VERSION ""

NS_ :

BS_:

BU_: WRCS SRS LECM3 LECM1 ECUspare6 CMS CIOM CCM AlcoLock2

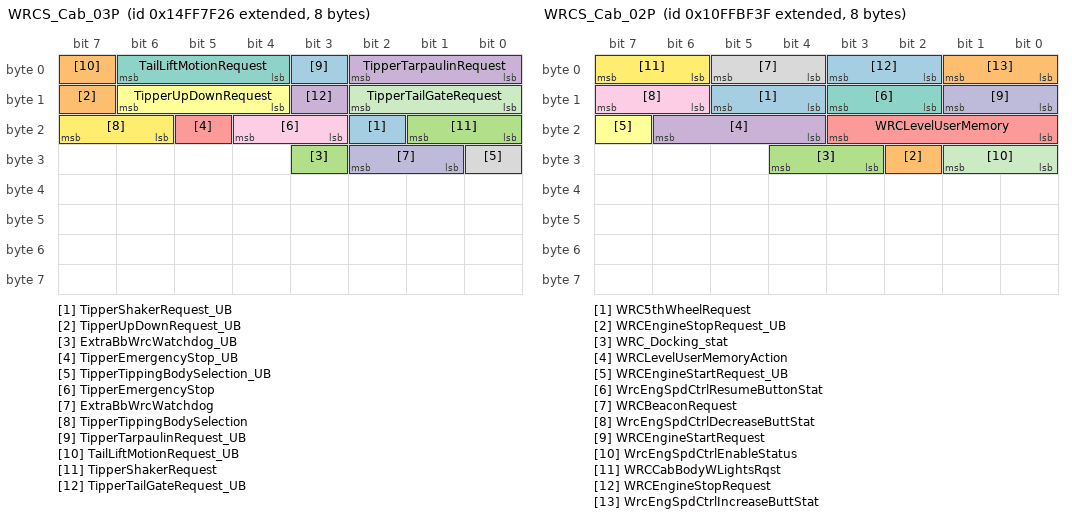
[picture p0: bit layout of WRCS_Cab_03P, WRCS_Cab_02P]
BO_ 2499772198 WRCS_Cab_03P: 8 WRCS
 SG_ TipperShakerRequest_UB : 18|1@1+ (1,0) [0|0] ""  CIOM
 SG_ TipperUpDownRequest_UB : 15|1@1+ (1,0) [0|0] ""  CIOM
 SG_ ExtraBbWrcWatchdog_UB : 27|1@1+ (1,0) [0|0] ""  CIOM
 SG_ TipperTarpaulinRequest : 0|3@1+ (1,0) [0|0] ""  CIOM
 SG_ TipperEmergencyStop_UB : 21|1@1+ (1,0) [0|0] ""  CIOM
 SG_ TipperUpDownRequest : 12|3@1+ (1,0) [0|0] ""  CIOM
 SG_ TailLiftMotionRequest : 4|3@1+ (1,0) [0|0] ""  CIOM
 SG_ TipperTippingBodySelection_UB : 24|1@1+ (1,0) [0|0] ""  CIOM
 SG_ TipperEmergencyStop : 19|2@1+ (1,0) [0|0] ""  CIOM
 SG_ ExtraBbWrcWatchdog : 25|2@1+ (1,0) [0|0] ""  CIOM
 SG_ TipperTailGateRequest : 8|3@1+ (1,0) [0|0] ""  CIOM
 SG_ TipperTippingBodySelection : 22|2@1+ (1,0) [0|0] ""  CIOM
 SG_ TipperTarpaulinRequest_UB : 3|1@1+ (1,0) [0|0] ""  CIOM
 SG_ TailLiftMotionRequest_UB : 7|1@1+ (1,0) [0|0] ""  CIOM
 SG_ TipperShakerRequest : 16|2@1+ (1,0) [0|0] ""  CIOM
 SG_ TipperTailGateRequest_UB : 11|1@1+ (1,0) [0|0] ""  CIOM

BO_ 2432679743 WRCS_Cab_02P: 8 WRCS
 SG_ WRC5thWheelRequest : 12|2@1+ (1,0) [0|0] ""  CIOM
 SG_ WRCEngineStopRequest_UB : 26|1@1+ (1,0) [0|0] ""  CIOM
 SG_ WRC_Docking_stat : 27|2@1+ (1,0) [0|0] ""  CIOM
 SG_ WRCLevelUserMemoryAction : 20|3@1+ (1,0) [0|0] ""  CIOM
 SG_ WRCLevelUserMemory : 16|4@1+ (1,0) [0|0] ""  CIOM
 SG_ WRCEngineStartRequest_UB : 23|1@1+ (1,0) [0|0] ""  CIOM
 SG_ WrcEngSpdCtrlResumeButtonStat : 10|2@1+ (1,0) [0|0] ""  CIOM
 SG_ WRCBeaconRequest : 4|2@1+ (1,0) [0|0] ""  CIOM
 SG_ WrcEngSpdCtrlDecreaseButtStat : 14|2@1+ (1,0) [0|0] ""  CIOM
 SG_ WRCEngineStartRequest : 8|2@1+ (1,0) [0|0] ""  CIOM
 SG_ WrcEngSpdCtrlEnableStatus : 24|2@1+ (1,0) [0|0] ""  CIOM
 SG_ WRCCabBodyWLightsRqst : 6|2@1+ (1,0) [0|0] ""  CIOM
 SG_ WRCEngineStopRequest : 2|2@1+ (1,0) [0|0] ""  CIOM
 SG_ WrcEngSpdCtrlIncreaseButtStat : 0|2@1+ (1,0) [0|0] ""  CIOM

BO_ 2365554559 WRCS_Cab_01P: 8 WRCS
 SG_ WrcPto1ButtonStatus : 2|2@1+ (1,0) [0|0] ""  CIOM
 SG_ ECSStandByReqWRC : 35|3@1+ (1,0) [0|0] ""  CIOM
 SG_ WRCCraneRequest : 22|2@1+ (1,0) [0|0] ""  CIOM
 SG_ WRCUnlockButtonStatus : 4|2@1+ (1,0) [0|0] ""  CIOM
 SG_ WRCRollRequest : 32|3@1+ (1,0) [0|0] ""  CIOM
 SG_ WRCAux3Request : 14|2@1+ (1,0) [0|0] ""  CIOM
 SG_ WRCAux2Request : 0|2@1+ (1,0) [0|0] ""  CIOM
 SG_ WrcPto3ButtonStatus : 20|2@1+ (1,0) [0|0] ""  CIOM
 SG_ WRCLevelAdjustmentAction : 44|4@1+ (1,0) [0|0] ""  CIOM
 SG_ WRCAux4Request : 10|2@1+ (1,0) [0|0] ""  CIOM
 SG_ WRCAux5Request : 8|2@1+ (1,0) [0|0] ""  CIOM
 SG_ WRCAux6Request : 16|2@1+ (1,0) [0|0] ""  CIOM
 SG_ WRCSideReverseWorkingRequest : 6|2@1+ (1,0) [0|0] ""  CIOM
 SG_ WrcPto2ButtonStatus : 12|2@1+ (1,0) [0|0] ""  CIOM
 SG_ WRCTailLiftRequest : 24|2@1+ (1,0) [0|0] ""  CIOM
 SG_ WrcPto4ButtonStatus : 30|2@1+ (1,0) [0|0] ""  CIOM
 SG_ WRCLevelAdjustmentStroke : 41|3@1+ (1,0) [0|0] ""  CIOM
 SG_ WRCLevelAdjustmentAxles : 38|3@1+ (1,0) [0|0] ""  CIOM
 SG_ WRCAirSuspensionStopRequest : 28|2@1+ (1,0) [0|0] ""  CIOM
 SG_ WRCAux1Request : 26|2@1+ (1,0) [0|0] ""  CIOM
 SG_ WRCLockButtonStatus : 18|2@1+ (1,0) [0|0] ""  CIOM

BO_ 2671902706 TesterFuncDiagMsg_Cab: 8 CIOM
 SG_ FuncDiagDataTester : 0|64@1+ (1,0) [0|0] ""  SRS,CCM,LECM1,WRCS,LECM3,CMS

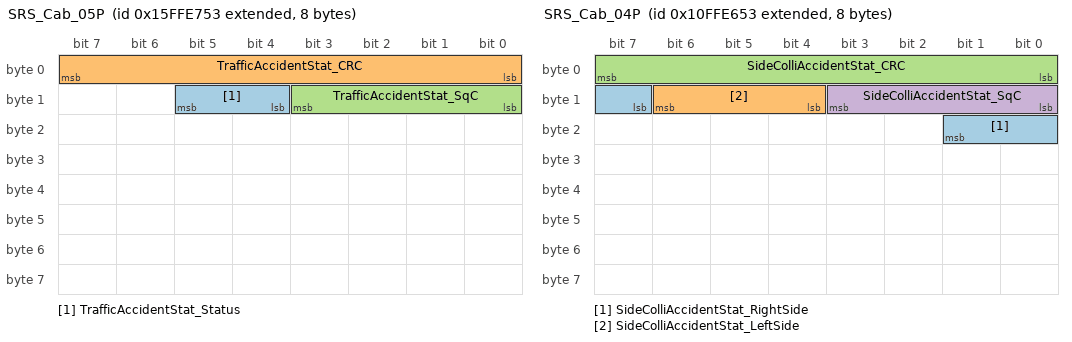
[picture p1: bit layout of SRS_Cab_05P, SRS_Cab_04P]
BO_ 2516576083 SRS_Cab_05P: 8 SRS
 SG_ TrafficAccidentStat_Status : 12|2@1+ (1,0) [0|0] ""  CIOM
 SG_ TrafficAccidentStat_CRC : 0|8@1+ (1,0) [0|255] ""  CIOM
 SG_ TrafficAccidentStat_SqC : 8|4@1+ (1,0) [0|14] "NotApplicable"  CIOM

BO_ 2432689747 SRS_Cab_04P: 8 SRS
 SG_ SideColliAccidentStat_RightSide : 15|3@1+ (1,0) [0|0] ""  CIOM
 SG_ SideColliAccidentStat_LeftSide : 12|3@1+ (1,0) [0|0] ""  CIOM
 SG_ SideColliAccidentStat_CRC : 0|8@1+ (1,0) [0|255] ""  CIOM
 SG_ SideColliAccidentStat_SqC : 8|4@1+ (1,0) [0|14] "NotApplicable"  CIOM

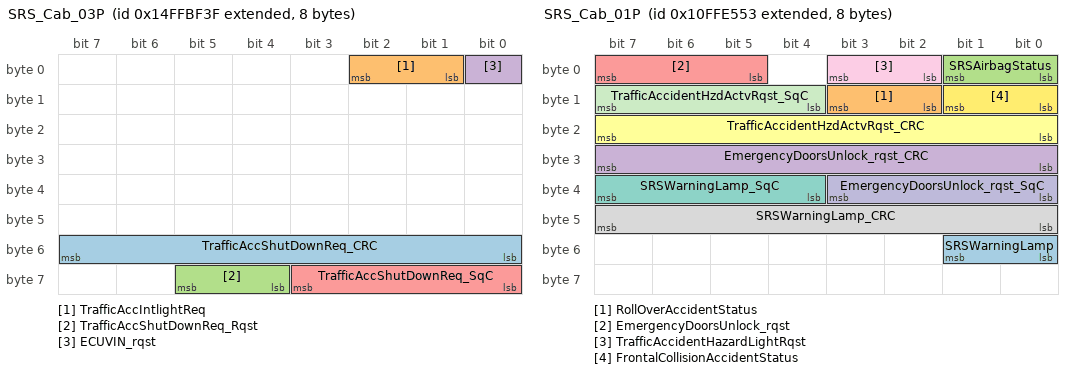
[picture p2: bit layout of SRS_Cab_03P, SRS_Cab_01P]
BO_ 2499788607 SRS_Cab_03P: 8 SRS
 SG_ TrafficAccShutDownReq_CRC : 48|8@1+ (1,0) [0|255] ""  CIOM
 SG_ TrafficAccIntlightReq : 1|2@1+ (1,0) [0|0] ""  CIOM
 SG_ TrafficAccShutDownReq_Rqst : 60|2@1+ (1,0) [0|0] ""  CIOM
 SG_ ECUVIN_rqst : 0|1@1+ (1,0) [0|0] ""  CIOM
 SG_ TrafficAccShutDownReq_SqC : 56|4@1+ (1,0) [0|0] ""  CIOM

BO_ 2432689491 SRS_Cab_01P: 8 SRS
 SG_ SRSWarningLamp : 48|2@1+ (1,0) [0|0] ""  CIOM
 SG_ RollOverAccidentStatus : 10|2@1+ (1,0) [0|0] ""  CCM,CIOM
 SG_ SRSAirbagStatus : 0|2@1+ (1,0) [0|0] ""  CIOM
 SG_ EmergencyDoorsUnlock_rqst_CRC : 24|8@1+ (1,0) [0|255] ""  CIOM
 SG_ EmergencyDoorsUnlock_rqst : 5|3@1+ (1,0) [0|0] ""  CIOM
 SG_ TrafficAccidentHzdActvRqst_CRC : 16|8@1+ (1,0) [0|255] ""  CIOM
 SG_ SRSWarningLamp_SqC : 36|4@1+ (1,0) [0|15] "Count"  CIOM
 SG_ SRSWarningLamp_CRC : 40|8@1+ (1,0) [0|255] ""  CIOM
 SG_ TrafficAccidentHazardLightRqst : 2|2@1+ (1,0) [0|0] ""  CIOM
 SG_ EmergencyDoorsUnlock_rqst_SqC : 32|4@1+ (1,0) [0|15] "Count"  CIOM
 SG_ TrafficAccidentHzdActvRqst_SqC : 12|4@1+ (1,0) [0|15] "Count"  CIOM
 SG_ FrontalCollisionAccidentStatus : 8|2@1+ (1,0) [0|0] ""  CIOM,CCM

BO_ 2658975757 SRSDiagPSTesterTx4_Cab: 8 SRS
 SG_ SRSDiagPSTesterTx4 : 0|64@1+ (1,0) [0|0] "" Vector__XXX

BO_ 2658975756 SRSDiagPSTesterTx3_Cab: 8 SRS
 SG_ SRSDiagPSTesterTx3 : 0|64@1+ (1,0) [0|0] "" Vector__XXX

BO_ 2658975755 SRSDiagPSTesterTx2_Cab: 8 SRS
 SG_ SRSDiagPSTesterTx2 : 0|64@1+ (1,0) [0|0] "" Vector__XXX

BO_ 2658967560 SRSDiagPSTesterTx1_Cab: 8 SRS
 SG_ SRSDiagPSTesterTx1 : 0|64@1+ (1,0) [0|0] "" Vector__XXX

BO_ 2658967559 SRSDiagPSTesterRx1_Cab: 8 Vector__XXX
 SG_ SRSDiagPSTesterRx1 : 0|64@1+ (1,0) [0|0] ""  SRS

BO_ 2671833762 PhysDiagRespMsg_F2_A2_Cab: 8 LECM3
 SG_ PhysDiagRespSig_F2_A2 : 0|64@1+ (1,0) [0|0] ""  CIOM

BO_ 2671833752 PhysDiagRespMsg_F2_98_Cab: 8 CCM
 SG_ PhysDiagRespSig_F2_98 : 0|64@1+ (1,0) [0|0] ""  CIOM

BO_ 2671833747 PhysDiagRespMsg_F2_93_Cab: 8 CMS
 SG_ PhysDiagRespSig_F2_93 : 0|64@1+ (1,0) [0|0] ""  CIOM

BO_ 2671833683 PhysDiagRespMsg_F2_53_Cab: 8 SRS
 SG_ PhysDiagRespSig_F2_53 : 0|64@1+ (1,0) [0|0] ""  CIOM

BO_ 2671833638 PhysDiagRespMsg_F2_26_Cab: 8 WRCS
 SG_ PhysDiagRespSig_F2_26 : 0|64@1+ (1,0) [0|0] ""  CIOM

BO_ 2564485459 PhysDiagRespMsg_F1_53_Cab: 8 SRS
 SG_ PhysDiagRespSig_F1_53 : 0|64@1+ (1,0) [0|0] ""  CIOM

BO_ 2671813362 PhysDiagReqMsg_A2_F2_Cab: 8 CIOM
 SG_ PhysDiagReqSig_A2_F2 : 0|64@1+ (1,0) [0|0] ""  LECM3,LECM1

BO_ 2671810802 PhysDiagReqMsg_98_F2_Cab: 8 CIOM
 SG_ PhysDiagReqSig_98_F2 : 0|64@1+ (1,0) [0|0] ""  CCM

BO_ 2671809522 PhysDiagReqMsg_93_F2_Cab: 8 CIOM
 SG_ PhysDiagReqSig_93_F2 : 0|64@1+ (1,0) [0|0] ""  CMS

BO_ 2671793138 PhysDiagReqMsg_53_F2_Cab: 8 CIOM
 SG_ PhysDiagReqSig_53_F2 : 0|64@1+ (1,0) [0|0] ""  SRS

BO_ 2564445169 PhysDiagReqMsg_53_F1_Cab: 8 CIOM
 SG_ PhysDiagReqSig_53_F1 : 0|64@1+ (1,0) [0|0] ""  SRS

BO_ 2671781618 PhysDiagReqMsg_26_F2_Cab: 8 CIOM
 SG_ PhysDiagReqSig_26_F2 : 0|64@1+ (1,0) [0|0] ""  WRCS

BO_ 2633990182 NmAsr_WRCS_Cab: 1 WRCS

BO_ 2633990227 NmAsr_SRS_Cab: 1 SRS

BO_ 2633990306 NmAsr_LECM1_Cab: 1 LECM3

BO_ 2633990291 NmAsr_CMS_Cab: 1 CMS

BO_ 2633990208 NmAsr_CIOM_Cab: 1 CIOM

BO_ 2633990296 NmAsr_CCM_Cab: 1 CCM

BO_ 2549208482 LECM3_Cab_02P: 8 LECM3
 SG_ LECM_Ent_UpDown_WheelStatus : 20|4@1+ (1,0) [0|0] ""  CIOM
 SG_ LECM_IntLight_SlprMaxLight_BS : 48|2@1+ (1,0) [0|0] ""  CIOM
 SG_ LECM_CabClim_Pwr_BtnStat : 14|2@1+ (1,0) [0|0] ""  CIOM
 SG_ LECM_LockControl_Lock_BtnStat : 52|2@1+ (1,0) [0|0] ""  CIOM
 SG_ LECM_CabClim_Auto_BtnStat : 10|2@1+ (1,0) [0|0] ""  CIOM
 SG_ LECM_CabClim_AC_BtnStat : 18|2@1+ (1,0) [0|0] ""  CIOM
 SG_ LECM_CabClim_FrPwr_BtnStat : 8|2@1+ (1,0) [0|0] ""  CIOM
 SG_ LECM_Ent_Volume_WheelStatus : 28|4@1+ (1,0) [0|0] ""  CIOM
 SG_ LECMCabClimSetTempSelectGuiReq : 62|2@1+ (1,0) [0|0] ""  CIOM
 SG_ LECM_IntLight_SlprAmbLow_BS : 46|2@1+ (1,0) [0|0] ""  CIOM
 SG_ LECM_CabClim_MaxDef_GuiReq : 54|2@1+ (1,0) [0|0] ""  CIOM
 SG_ LECM_CabClim_Fan_WheelStatus : 32|4@1+ (1,0) [0|0] ""  CIOM
 SG_ LECM_IntLight_SlprAmbUpp_BS : 44|2@1+ (1,0) [0|0] ""  CIOM
 SG_ LECM_Ent_AudioSettingsViewSts : 56|4@1+ (1,0) [0|0] ""  CIOM
 SG_ LECM_Panic_CMS_BtnStat : 50|2@1+ (1,0) [0|0] ""  CIOM
 SG_ LECM_CabClim_Sync_GuiReq : 16|2@1+ (1,0) [0|0] ""  CIOM
 SG_ LecmCutOffAnswerGuiRqst : 60|2@1+ (1,0) [0|0] ""  CIOM
 SG_ LECM_Ent_MediaSource_BtnStat : 12|2@1+ (1,0) [0|0] ""  CIOM
 SG_ LECM_CabClim_Temp_WheelStatus : 24|4@1+ (1,0) [0|0] ""  CIOM
 SG_ LECM_Power_Inverter_BtnStat : 0|2@1+ (1,0) [0|0] ""  CIOM
 SG_ LECM_Ent_SkpLeft_BtnStat : 2|2@1+ (1,0) [0|0] ""  CIOM
 SG_ LECM_IntLight_SlprDecrease_BS : 40|2@1+ (1,0) [0|0] ""  CIOM
 SG_ LECM_Ent_OnOff_BtnStat : 6|2@1+ (1,0) [0|0] ""  CIOM
 SG_ LECM_IntLight_SlprIncrease_BS : 42|2@1+ (1,0) [0|0] ""  CIOM
 SG_ LECM_Ent_SkpRight_BtnStat : 4|2@1+ (1,0) [0|0] ""  CIOM

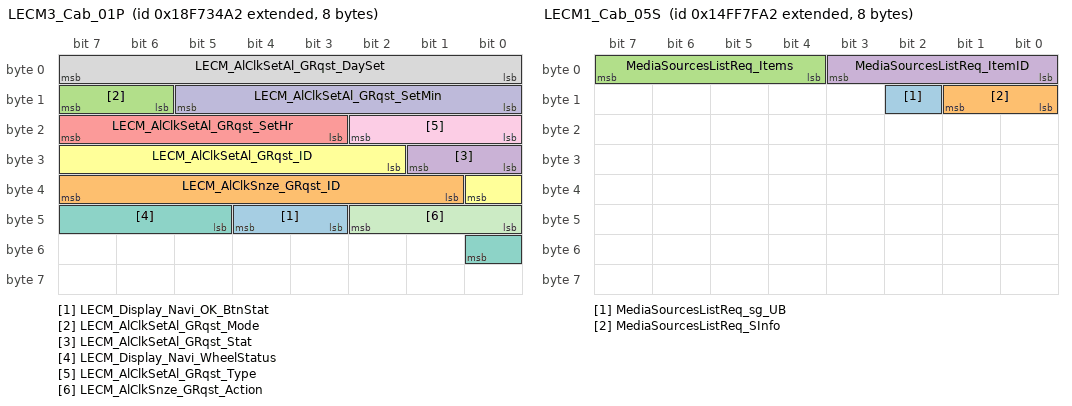
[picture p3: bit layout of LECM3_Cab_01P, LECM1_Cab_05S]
BO_ 2566337698 LECM3_Cab_01P: 8 LECM3
 SG_ LECM_Display_Navi_OK_BtnStat : 43|2@1+ (1,0) [0|0] ""  CIOM
 SG_ LECM_AlClkSnze_GRqst_ID : 33|7@1+ (1,0) [0|0] ""  CIOM
 SG_ LECM_AlClkSetAl_GRqst_Mode : 14|2@1+ (1,0) [0|0] ""  CIOM
 SG_ LECM_AlClkSetAl_GRqst_Stat : 24|2@1+ (1,0) [0|0] ""  CIOM
 SG_ LECM_AlClkSetAl_GRqst_SetHr : 19|5@1+ (1,0) [0|31] "h"  CIOM
 SG_ LECM_AlClkSetAl_GRqst_ID : 26|7@1+ (1,0) [0|0] ""  CIOM
 SG_ LECM_Display_Navi_WheelStatus : 45|4@1+ (1,0) [0|0] ""  CIOM
 SG_ LECM_AlClkSetAl_GRqst_DaySet : 0|8@1+ (1,0) [0|255] ""  CIOM
 SG_ LECM_AlClkSetAl_GRqst_Type : 16|3@1+ (1,0) [0|0] ""  CIOM
 SG_ LECM_AlClkSetAl_GRqst_SetMin : 8|6@1+ (1,0) [0|63] "min"  CIOM
 SG_ LECM_AlClkSnze_GRqst_Action : 40|3@1+ (1,0) [0|0] ""  CIOM

BO_ 2499772322 LECM1_Cab_05S: 8 LECM1
 SG_ MediaSourcesListReq_sg_UB : 10|1@1+ (1,0) [0|0] ""  CIOM
 SG_ MediaSourcesListReq_SInfo : 8|2@1+ (1,0) [0|0] ""  CIOM
 SG_ MediaSourcesListReq_Items : 4|4@1+ (1,0) [0|0] ""  CIOM
 SG_ MediaSourcesListReq_ItemID : 0|4@1+ (1,0) [0|0] ""  CIOM

BO_ 2489730210 LECM1_Cab_04P: 8 LECM1
 SG_ BunkH1AudioSrcSem_rqst : 0|4@1+ (1,0) [0|0] ""  CIOM
 SG_ CMSOnOffRqst : 4|2@1+ (1,0) [0|0] ""  CIOM

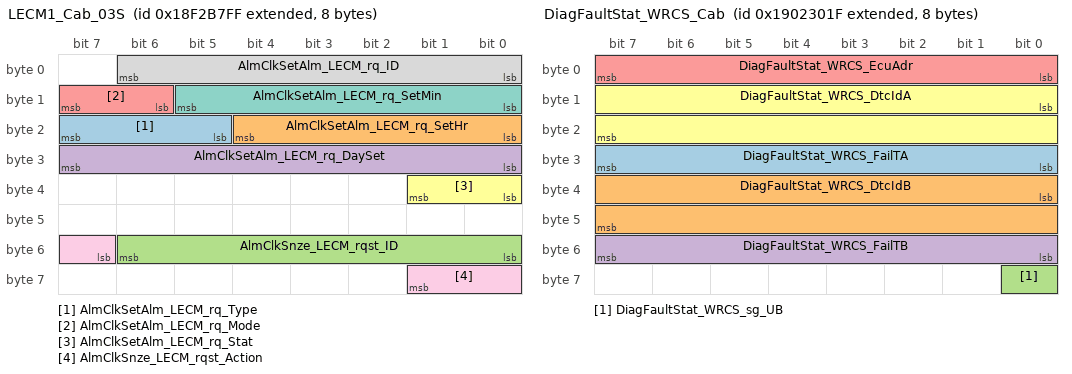
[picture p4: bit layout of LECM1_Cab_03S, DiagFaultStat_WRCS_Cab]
BO_ 2566043647 LECM1_Cab_03S: 8 LECM1
 SG_ AlmClkSetAlm_LECM_rq_Type : 21|3@1+ (1,0) [0|0] ""  CIOM
 SG_ AlmClkSetAlm_LECM_rq_SetHr : 16|5@1+ (1,0) [0|31] "h"  CIOM
 SG_ AlmClkSnze_LECM_rqst_ID : 48|7@1+ (1,0) [0|0] ""  CIOM
 SG_ AlmClkSetAlm_LECM_rq_DaySet : 24|8@1+ (1,0) [0|255] ""  CIOM
 SG_ AlmClkSetAlm_LECM_rq_Mode : 14|2@1+ (1,0) [0|0] ""  CIOM
 SG_ AlmClkSetAlm_LECM_rq_Stat : 32|2@1+ (1,0) [0|0] ""  CIOM
 SG_ AlmClkSetAlm_LECM_rq_SetMin : 8|6@1+ (1,0) [0|63] "min"  CIOM
 SG_ AlmClkSetAlm_LECM_rq_ID : 0|7@1+ (1,0) [0|0] ""  CIOM
 SG_ AlmClkSnze_LECM_rqst_Action : 55|3@1+ (1,0) [0|0] ""  CIOM

BO_ 2432693154 LECM1_Cab_02P: 8 LECM1
 SG_ BunkH1Prev_ButtonStatus : 0|2@1+ (1,0) [0|0] ""  CIOM
 SG_ BunkH1PowerWinOpenDSBtn_stat_UB : 58|1@1+ (1,0) [0|0] ""  CIOM
 SG_ BunkH1RoofhatchOpenBtn_Stat : 32|2@1+ (1,0) [0|0] ""  CIOM
 SG_ BunkH1IntLghtActvnBtn_stat : 6|2@1+ (1,0) [0|0] ""  CIOM
 SG_ BunkH1AudioSource_rqst : 48|3@1+ (1,0) [0|0] ""  CIOM
 SG_ BunkH1TempDec_ButtonStatus : 24|2@1+ (1,0) [0|0] ""  CCM
 SG_ BunkH1IntLghtDirAccsUpBtn_stat : 46|2@1+ (1,0) [0|0] ""  CIOM
 SG_ BunkH1RoofhatchCloseBtn_Stat : 28|2@1+ (1,0) [0|0] ""  CIOM
 SG_ BunkH1PowerWinClosePSBtn_stat_UB : 55|1@1+ (1,0) [0|0] ""  CIOM
 SG_ BunkH1VolumeDown_ButtonStatus : 18|2@1+ (1,0) [0|0] ""  CIOM
 SG_ BunkH1PowerWinCloseDSBtn_stat : 16|2@1+ (1,0) [0|0] ""  CIOM
 SG_ BunkH1Next_ButtonStatus : 20|2@1+ (1,0) [0|0] ""  CIOM
 SG_ BunkH1UnlockButtonStatus : 4|2@1+ (1,0) [0|0] ""  CIOM
 SG_ BunkH1ParkHeaterTimer2_cmd : 40|3@1+ (1,0) [0|0] ""  CCM
 SG_ BunkH1AudioOnOff_ButtonStatus : 2|2@1+ (1,0) [0|0] ""  CIOM
 SG_ BunkH1PowerWinOpenPSBtn_stat_UB : 59|1@1+ (1,0) [0|0] ""  CIOM
 SG_ BunkH1PowerWinOpenDSBtn_stat : 8|2@1+ (1,0) [0|0] ""  CIOM
 SG_ BunkH1ParkHeater_ButtonStatus : 14|2@1+ (1,0) [0|0] ""  CCM
 SG_ BunkH1VolumeUp_ButtonStatus : 30|2@1+ (1,0) [0|0] ""  CIOM
 SG_ BunkH1ParkHeaterTimer3_cmd : 36|3@1+ (1,0) [0|0] ""  CCM
 SG_ BunkH1Mute_ButtonStatus : 56|2@1+ (1,0) [0|0] ""  CIOM
 SG_ BunkH1IntLghtDirAccsDnBtn_stat : 22|2@1+ (1,0) [0|0] ""  CIOM
 SG_ BunkH1LockButtonStatus : 10|2@1+ (1,0) [0|0] ""  CIOM
 SG_ BunkH1ParkHeaterTimer1_cmd : 43|3@1+ (1,0) [0|0] ""  CCM
 SG_ BnkH1IntLghtMMenu_stat_IL_Mode : 51|3@1+ (1,0) [0|0] ""  CIOM
 SG_ BunkH1AudioSource_rqst2 : 60|4@1+ (1,0) [0|0] ""  CIOM
 SG_ BunkH1PowerWinCloseDSBtn_stat_UB : 39|1@1+ (1,0) [0|0] ""  CIOM
 SG_ BnkH1IntLghtMMenu_stat_EventFlag : 54|1@1+ (1,0) [0|0] ""  CIOM
 SG_ BunkH1PowerWinOpenPSBtn_stat : 26|2@1+ (1,0) [0|0] ""  CIOM
 SG_ BunkH1PowerWinClosePSBtn_stat : 34|2@1+ (1,0) [0|0] ""  CIOM
 SG_ BunkH1TempInc_ButtonStatus : 12|2@1+ (1,0) [0|0] ""  CCM

BO_ 2671902708 IntTesterTGW2FuncDiagMsg_Cab: 8 CIOM
 SG_ FuncDiagDataIntTesterTGW2 : 0|64@1+ (1,0) [0|0] ""  LECM3,LECM1,SRS,CCM,CMS,WRCS

BO_ 2671964834 DiagUUDTRespMsg1_F2_A2_Cab: 8 LECM1
 SG_ DiagUUDTRespSig_F2_A2 : 0|64@1+ (1,0) [0|0] ""  CIOM

BO_ 2671964824 DiagUUDTRespMsg1_F2_98_Cab: 8 CCM
 SG_ DiagUUDTRespSig_F2_98 : 0|64@1+ (1,0) [0|0] ""  CIOM

BO_ 2671964819 DiagUUDTRespMsg1_F2_93_Cab: 8 CMS
 SG_ DiagUUDTRespSig_F2_93 : 0|64@1+ (1,0) [0|0] ""  CIOM

BO_ 2671964755 DiagUUDTRespMsg1_F2_53_Cab: 8 SRS
 SG_ DiagUUDTRespSig_F2_53 : 0|64@1+ (1,0) [0|0] ""  CIOM

BO_ 2671964710 DiagUUDTRespMsg1_F2_26_Cab: 8 WRCS
 SG_ DiagUUDTRespSig_F2_26 : 0|64@1+ (1,0) [0|0] ""  CIOM

BO_ 2671834259 DiagRespMsgIntTGW_F4_93_Cab: 8 CMS
 SG_ InternalTesterDiagSig_F4_93 : 0|64@1+ (1,0) [0|0] ""  CIOM

BO_ 2671834274 DiagRespMsgIntTGW2_F4_A2_Cab: 8 LECM3
 SG_ InternalTesterDiagSig_F4_A2 : 0|64@1+ (1,0) [0|0] ""  CIOM

BO_ 2671834264 DiagRespMsgIntTGW2_F4_98_Cab: 8 CCM
 SG_ InternalTesterDiagSig_F4_98 : 0|64@1+ (1,0) [0|0] ""  CIOM

BO_ 2671834195 DiagRespMsgIntTGW2_F4_53_Cab: 8 SRS
 SG_ InternalTesterDiagSig_F4_53 : 0|64@1+ (1,0) [0|0] ""  CIOM

BO_ 2671834150 DiagRespMsgIntTGW2_F4_26_Cab: 8 WRCS
 SG_ InternalTesterDiagSig_F4_26 : 0|64@1+ (1,0) [0|0] ""  CIOM

BO_ 2671834003 DiagRespMsgIntIC_F3_93_Cab: 8 CMS
 SG_ InternalTesterDiagSig_F3_93 : 0|64@1+ (1,0) [0|0] ""  CIOM

BO_ 2671834018 DiagRespMsgIntHMIIOM_F3_A2_Cab: 8 LECM3
 SG_ InternalTesterDiagSig_F3_A2 : 0|64@1+ (1,0) [0|0] ""  CIOM

BO_ 2671834008 DiagRespMsgIntHMIIOM_F3_98_Cab: 8 CCM
 SG_ InternalTesterDiagSig_F3_98 : 0|64@1+ (1,0) [0|0] ""  CIOM

BO_ 2671833939 DiagRespMsgIntHMIIOM_F3_53_Cab: 8 SRS
 SG_ InternalTesterDiagSig_F3_53 : 0|64@1+ (1,0) [0|0] ""  CIOM

BO_ 2671833894 DiagRespMsgIntHMIIOM_F3_26_Cab: 8 WRCS
 SG_ InternalTesterDiagSig_F3_26 : 0|64@1+ (1,0) [0|0] ""  CIOM

BO_ 2671809524 DiagReqMsgIntTGW_93_F4_Cab: 8 CIOM
 SG_ InternalTesterDiagSig_93_F4 : 0|64@1+ (1,0) [0|0] ""  CMS

BO_ 2671813364 DiagReqMsgIntTGW2_A2_F4_Cab: 8 CIOM
 SG_ InternalTesterDiagSig_A2_F4 : 0|64@1+ (1,0) [0|0] ""  LECM1,LECM3

BO_ 2671810804 DiagReqMsgIntTGW2_98_F4_Cab: 8 CIOM
 SG_ InternalTesterDiagSig_98_F4 : 0|64@1+ (1,0) [0|0] ""  CCM

BO_ 2671793140 DiagReqMsgIntTGW2_53_F4_Cab: 8 CIOM
 SG_ InternalTesterDiagSig_53_F4 : 0|64@1+ (1,0) [0|0] ""  SRS

BO_ 2671781620 DiagReqMsgIntTGW2_26_F4_Cab: 8 CIOM
 SG_ InternalTesterDiagSig_26_F4 : 0|64@1+ (1,0) [0|0] ""  WRCS

BO_ 2671809523 DiagReqMsgIntIC_93_F3_Cab: 8 CIOM
 SG_ InternalTesterDiagSig_93_F3 : 0|64@1+ (1,0) [0|0] ""  CMS

BO_ 2671813363 DiagReqMsgIntHMIIOM_A2_F3_Cab: 8 CIOM
 SG_ InternalTesterDiagSig_A2_F3 : 0|64@1+ (1,0) [0|0] ""  LECM1,LECM3

BO_ 2671810803 DiagReqMsgIntHMIIOM_98_F3_Cab: 8 CIOM
 SG_ InternalTesterDiagSig_98_F3 : 0|64@1+ (1,0) [0|0] ""  CCM

BO_ 2671793139 DiagReqMsgIntHMIIOM_53_F3_Cab: 8 CIOM
 SG_ InternalTesterDiagSig_53_F3 : 0|64@1+ (1,0) [0|0] ""  SRS

BO_ 2671781619 DiagReqMsgIntHMIIOM_26_F3_Cab: 8 CIOM
 SG_ InternalTesterDiagSig_26_F3 : 0|64@1+ (1,0) [0|0] ""  WRCS

BO_ 2567057439 DiagFaultStat_WRCS_Cab: 8 WRCS
 SG_ DiagFaultStat_WRCS_FailTA : 24|8@1+ (1,0) [0|255] ""  CIOM
 SG_ DiagFaultStat_WRCS_DtcIdB : 32|16@1+ (1,0) [0|65535] ""  CIOM
 SG_ DiagFaultStat_WRCS_sg_UB : 56|1@1+ (1,0) [0|0] ""  CIOM
 SG_ DiagFaultStat_WRCS_FailTB : 48|8@1+ (1,0) [0|255] ""  CIOM
 SG_ DiagFaultStat_WRCS_EcuAdr : 0|8@1+ (1,0) [0|255] ""  CIOM
 SG_ DiagFaultStat_WRCS_DtcIdA : 8|16@1+ (1,0) [0|65535] ""  CIOM

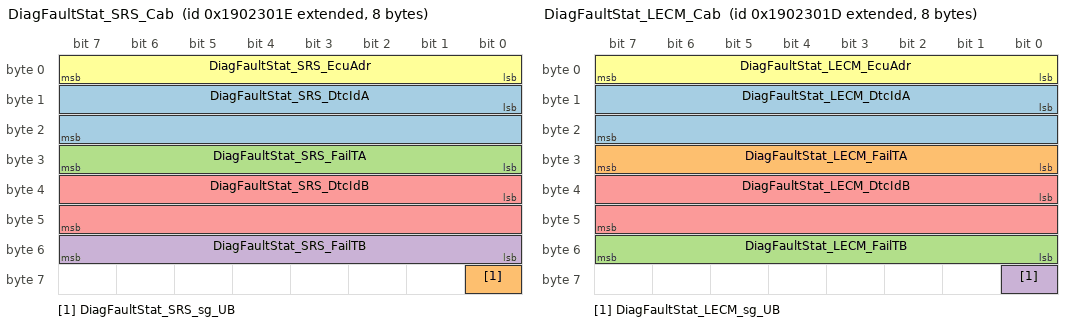
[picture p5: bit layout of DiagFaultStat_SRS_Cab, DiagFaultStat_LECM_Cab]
BO_ 2567057438 DiagFaultStat_SRS_Cab: 8 SRS
 SG_ DiagFaultStat_SRS_DtcIdA : 8|16@1+ (1,0) [0|65535] ""  CIOM
 SG_ DiagFaultStat_SRS_sg_UB : 56|1@1+ (1,0) [0|0] ""  CIOM
 SG_ DiagFaultStat_SRS_FailTA : 24|8@1+ (1,0) [0|255] ""  CIOM
 SG_ DiagFaultStat_SRS_FailTB : 48|8@1+ (1,0) [0|255] ""  CIOM
 SG_ DiagFaultStat_SRS_DtcIdB : 32|16@1+ (1,0) [0|65535] ""  CIOM
 SG_ DiagFaultStat_SRS_EcuAdr : 0|8@1+ (1,0) [0|255] ""  CIOM

BO_ 2567057437 DiagFaultStat_LECM_Cab: 8 LECM1
 SG_ DiagFaultStat_LECM_DtcIdA : 8|16@1+ (1,0) [0|65535] ""  CIOM
 SG_ DiagFaultStat_LECM_FailTA : 24|8@1+ (1,0) [0|255] ""  CIOM
 SG_ DiagFaultStat_LECM_FailTB : 48|8@1+ (1,0) [0|255] ""  CIOM
 SG_ DiagFaultStat_LECM_sg_UB : 56|1@1+ (1,0) [0|0] ""  CIOM
 SG_ DiagFaultStat_LECM_DtcIdB : 32|16@1+ (1,0) [0|65535] ""  CIOM
 SG_ DiagFaultStat_LECM_EcuAdr : 0|8@1+ (1,0) [0|255] ""  CIOM

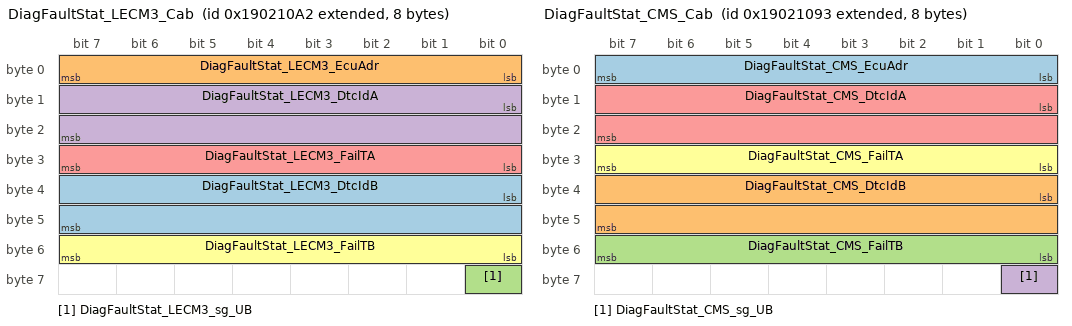
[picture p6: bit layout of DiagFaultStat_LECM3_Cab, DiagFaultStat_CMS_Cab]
BO_ 2567049378 DiagFaultStat_LECM3_Cab: 8 LECM3
 SG_ DiagFaultStat_LECM3_DtcIdB : 32|16@1+ (1,0) [0|65535] ""  CIOM
 SG_ DiagFaultStat_LECM3_EcuAdr : 0|8@1+ (1,0) [0|255] ""  CIOM
 SG_ DiagFaultStat_LECM3_sg_UB : 56|1@1+ (1,0) [0|0] ""  CIOM
 SG_ DiagFaultStat_LECM3_DtcIdA : 8|16@1+ (1,0) [0|65535] ""  CIOM
 SG_ DiagFaultStat_LECM3_FailTA : 24|8@1+ (1,0) [0|255] ""  CIOM
 SG_ DiagFaultStat_LECM3_FailTB : 48|8@1+ (1,0) [0|255] ""  CIOM

BO_ 2567049363 DiagFaultStat_CMS_Cab: 8 CMS
 SG_ DiagFaultStat_CMS_EcuAdr : 0|8@1+ (1,0) [0|255] ""  CIOM
 SG_ DiagFaultStat_CMS_DtcIdB : 32|16@1+ (1,0) [0|65535] ""  CIOM
 SG_ DiagFaultStat_CMS_FailTB : 48|8@1+ (1,0) [0|255] ""  CIOM
 SG_ DiagFaultStat_CMS_sg_UB : 56|1@1+ (1,0) [0|0] ""  CIOM
 SG_ DiagFaultStat_CMS_DtcIdA : 8|16@1+ (1,0) [0|65535] ""  CIOM
 SG_ DiagFaultStat_CMS_FailTA : 24|8@1+ (1,0) [0|255] ""  CIOM

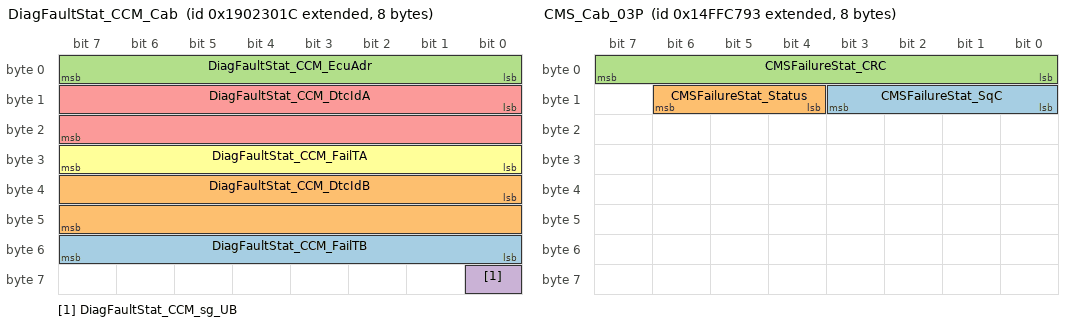
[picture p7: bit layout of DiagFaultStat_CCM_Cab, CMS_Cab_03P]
BO_ 2567057436 DiagFaultStat_CCM_Cab: 8 CCM
 SG_ DiagFaultStat_CCM_FailTB : 48|8@1+ (1,0) [0|255] ""  CIOM
 SG_ DiagFaultStat_CCM_DtcIdB : 32|16@1+ (1,0) [0|65535] ""  CIOM
 SG_ DiagFaultStat_CCM_EcuAdr : 0|8@1+ (1,0) [0|255] ""  CIOM
 SG_ DiagFaultStat_CCM_sg_UB : 56|1@1+ (1,0) [0|0] ""  CIOM
 SG_ DiagFaultStat_CCM_DtcIdA : 8|16@1+ (1,0) [0|65535] ""  CIOM
 SG_ DiagFaultStat_CCM_FailTA : 24|8@1+ (1,0) [0|255] ""  CIOM

BO_ 2634020435 Debug6_SRS_Cab: 8 SRS
 SG_ Debug_6_SRS : 0|64@1+ (1,0) [0|0] "" Vector__XXX

BO_ 2634020514 Debug6_LECM_Cab: 8 LECM1
 SG_ Debug_6_LECM : 0|64@1+ (1,0) [0|0] "" Vector__XXX

BO_ 2634022306 Debug6_LECM3_Cab: 8 LECM3
 SG_ Debug_6_LECM3 : 0|64@1+ (1,0) [0|0] "" Vector__XXX

BO_ 2634020499 Debug6_CMS_Cab: 8 CMS
 SG_ Debug_6_CMS : 0|64@1+ (1,0) [0|0] "" Vector__XXX

BO_ 2634020504 Debug6_CCM_Cab: 8 CCM
 SG_ Debug_6_CCM : 0|64@1+ (1,0) [0|0] "" Vector__XXX

BO_ 2634020179 Debug5_SRS_Cab: 8 SRS
 SG_ Debug_5_SRS : 0|64@1+ (1,0) [0|0] "" Vector__XXX

BO_ 2634020258 Debug5_LECM_Cab: 8 LECM1
 SG_ Debug_5_LECM : 0|64@1+ (1,0) [0|0] "" Vector__XXX

BO_ 2634022050 Debug5_LECM3_Cab: 8 LECM3
 SG_ Debug_5_LECM3 : 0|64@1+ (1,0) [0|0] "" Vector__XXX

BO_ 2634020243 Debug5_CMS_Cab: 8 CMS
 SG_ Debug_5_CMS : 0|64@1+ (1,0) [0|0] "" Vector__XXX

BO_ 2634020248 Debug5_CCM_Cab: 8 CCM
 SG_ Debug_5_CCM : 0|64@1+ (1,0) [0|0] "" Vector__XXX

BO_ 2634019923 Debug4_SRS_Cab: 8 SRS
 SG_ Debug_4_SRS : 0|64@1+ (1,0) [0|0] "" Vector__XXX

BO_ 2634020002 Debug4_LECM_Cab: 8 LECM1
 SG_ Debug_4_LECM : 0|64@1+ (1,0) [0|0] "" Vector__XXX

BO_ 2634021794 Debug4_LECM3_Cab: 8 LECM3
 SG_ Debug_4_LECM3 : 0|64@1+ (1,0) [0|0] "" Vector__XXX

BO_ 2634019987 Debug4_CMS_Cab: 8 CMS
 SG_ Debug_4_CMS : 0|64@1+ (1,0) [0|0] "" Vector__XXX

BO_ 2634019992 Debug4_CCM_Cab: 8 CCM
 SG_ Debug_4_CCM : 0|64@1+ (1,0) [0|0] "" Vector__XXX

BO_ 2634019667 Debug3_SRS_Cab: 8 SRS
 SG_ Debug_3_SRS : 0|64@1+ (1,0) [0|0] "" Vector__XXX

BO_ 2634019746 Debug3_LECM_Cab: 8 LECM1
 SG_ Debug_3_LECM : 0|64@1+ (1,0) [0|0] "" Vector__XXX

BO_ 2634021538 Debug3_LECM3_Cab: 8 LECM3
 SG_ Debug_3_LECM3 : 0|64@1+ (1,0) [0|0] "" Vector__XXX

BO_ 2634019731 Debug3_CMS_Cab: 8 CMS
 SG_ Debug_3_CMS : 0|64@1+ (1,0) [0|0] "" Vector__XXX

BO_ 2634019736 Debug3_CCM_Cab: 8 Vector__XXX
 SG_ Debug_3_CCM : 0|64@1+ (1,0) [0|0] ""  CCM

BO_ 2634019411 Debug2_SRS_Cab: 8 SRS
 SG_ Debug_2_SRS : 0|64@1+ (1,0) [0|0] "" Vector__XXX

BO_ 2634019490 Debug2_LECM_Cab: 8 LECM1
 SG_ Debug_2_LECM : 0|64@1+ (1,0) [0|0] "" Vector__XXX

BO_ 2634021282 Debug2_LECM3_Cab: 8 LECM3
 SG_ Debug_2_LECM3 : 0|64@1+ (1,0) [0|0] "" Vector__XXX

BO_ 2634019475 Debug2_CMS_Cab: 8 CMS
 SG_ Debug_2_CMS : 0|64@1+ (1,0) [0|0] "" Vector__XXX

BO_ 2634019480 Debug2_CCM_Cab: 8 Vector__XXX
 SG_ Debug_2_CCM : 0|64@1+ (1,0) [0|0] ""  CCM

BO_ 2634019155 Debug1_SRS_Cab: 8 Vector__XXX
 SG_ Debug_1_SRS : 0|64@1+ (1,0) [0|0] ""  SRS

BO_ 2634019234 Debug1_LECM_Cab: 8 Vector__XXX
 SG_ Debug_1_LECM : 0|64@1+ (1,0) [0|0] ""  LECM1

BO_ 2634021026 Debug1_LECM3_Cab: 8 Vector__XXX
 SG_ Debug_1_LECM3 : 0|64@1+ (1,0) [0|0] ""  LECM3

BO_ 2634019219 Debug1_CMS_Cab: 8 Vector__XXX
 SG_ Debug_1_CMS : 0|64@1+ (1,0) [0|0] ""  CMS

BO_ 2634019224 Debug1_CCM_Cab: 8 Vector__XXX
 SG_ Debug_1_CCM : 0|64@1+ (1,0) [0|0] ""  CCM

BO_ 2499790739 CMS_Cab_03P: 8 CMS
 SG_ CMSFailureStat_SqC : 8|4@1+ (1,0) [0|14] "NotApplicable"  CIOM
 SG_ CMSFailureStat_Status : 12|3@1+ (1,0) [0|0] ""  CIOM
 SG_ CMSFailureStat_CRC : 0|8@1+ (1,0) [0|255] ""  CIOM

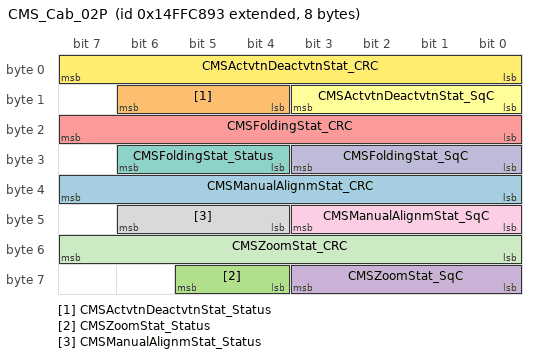
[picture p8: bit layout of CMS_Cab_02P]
BO_ 2499790995 CMS_Cab_02P: 8 CMS
 SG_ CMSManualAlignmStat_CRC : 32|8@1+ (1,0) [0|255] ""  CIOM
 SG_ CMSActvtnDeactvtnStat_Status : 12|3@1+ (1,0) [0|0] ""  LECM1,CIOM
 SG_ CMSZoomStat_Status : 60|2@1+ (1,0) [0|0] ""  CIOM
 SG_ CMSZoomStat_SqC : 56|4@1+ (1,0) [0|14] "NotApplicable"  CIOM
 SG_ CMSFoldingStat_CRC : 16|8@1+ (1,0) [0|255] ""  CIOM
 SG_ CMSActvtnDeactvtnStat_SqC : 8|4@1+ (1,0) [0|14] "NotApplicable"  LECM1,CIOM
 SG_ CMSFoldingStat_Status : 28|3@1+ (1,0) [0|0] ""  CIOM
 SG_ CMSManualAlignmStat_Status : 44|3@1+ (1,0) [0|0] ""  CIOM
 SG_ CMSManualAlignmStat_SqC : 40|4@1+ (1,0) [0|14] "NotApplicable"  CIOM
 SG_ CMSFoldingStat_SqC : 24|4@1+ (1,0) [0|14] "NotApplicable"  CIOM
 SG_ CMSZoomStat_CRC : 48|8@1+ (1,0) [0|255] ""  CIOM
 SG_ CMSActvtnDeactvtnStat_CRC : 0|8@1+ (1,0) [0|255] ""  CIOM,LECM1

BO_TX_BU_ 2671833762 : LECM1,LECM3;
BO_TX_BU_ 2633990306 : LECM1,LECM3;
BO_TX_BU_ 2671964834 : LECM3,LECM1;
BO_TX_BU_ 2671834274 : LECM1,LECM3;
BO_TX_BU_ 2671834018 : LECM1,LECM3;

CM_ "COM_MATRIX_T2_1.41.0";
CM_ BU_ WRCS "Wireless Remote Control Sensor";
CM_ BU_ SRS "Supplementary Restraint System";
CM_ BU_ LECM3 "Living Environment Control Module 3";
CM_ BU_ LECM1 "Living Environment Control Module 1";
CM_ BU_ CMS "Camera Monitor System";
CM_ BU_ CIOM "Cab I/O Module; Security and Cab Interface Module";
CM_ BU_ CCM "Climate Control Module";
CM_ SG_ 2566043647 AlmClkSetAlm_LECM_rq_SetHr "30 Error ; 31 Not Available";
CM_ SG_ 2566043647 AlmClkSetAlm_LECM_rq_SetMin "62 Error ; 63 Not Available";
BA_DEF_ BO_  "GenMsgStartDelayTime" INT 0 0;
BA_DEF_ BO_  "GenMsgDelayTime" INT 0 0;
BA_DEF_ BO_  "GenMsgCycleTime" INT 0 0;
BA_DEF_ BO_  "GenMsgSendType" ENUM  "Cyclic","NotUsed","NotUsed","NotUsed","NotUsed","NotUsed","NotUsed","IfActive","NoMsgSendType","NotUsed";
BA_DEF_ SG_  "GenSigStartValue" INT 0 0;
BA_DEF_ SG_  "GenSigCycleTimeActive" INT 0 0;
BA_DEF_ SG_  "GenSigCycleTime" INT 0 0;
BA_DEF_ SG_  "GenSigSendType" ENUM  "Cyclic","OnWrite","OnWriteWithRepetition","OnChange","OnChangeWithRepetition","IfActive","IfActiveWithRepetition","NoSigSendType","NotUsed","NotUsed","NotUsed","NotUsed","NotUsed";
BA_DEF_  "Baudrate" INT 0 1000000;
BA_DEF_  "NmType" STRING ;
BA_DEF_  "Manufacturer" STRING ;
BA_DEF_  "VersionYear" INT 0 99;
BA_DEF_  "VersionNumber" INT 0 99;
BA_DEF_  "VersionMonth" INT 1 12;
BA_DEF_  "VersionDay" INT 1 31;
BA_DEF_ BO_  "VFrameFormat" ENUM  "StandardCAN","ExtendedCAN","reserved","J1939PG","reserved","reserved","reserved","reserved","reserved","reserved","reserved","reserved","reserved","reserved","StandardCAN_FD","ExtendedCAN_FD";
BA_DEF_ BU_  "TpOwnSystemEcuNumber" HEX 0 255;
BA_DEF_ SG_  "SigType" ENUM  "Default","Range","RangeSigned","ASCII","Discrete","Control","ReferencePGN","DTC","StringDelimiter","StringLength","StringLengthControl";
BA_DEF_ SG_  "SeToolVersion_SIGNAL" STRING ;
BA_DEF_ SG_  "SeToolUniqueID_SIGNAL" STRING ;
BA_DEF_ SG_  "SeToolOwnerSigGroup_SIGNAL" STRING ;
BA_DEF_ SG_  "SeToolOwnerSigGroupID_SIGNAL" STRING ;
BA_DEF_ SG_  "SeToolName_SIGNAL" STRING ;
BA_DEF_ SG_  "SeToolItemID_SIGNAL" STRING ;
BA_DEF_ SG_  "SeToolAncestorID_SIGNAL" STRING ;
BA_DEF_ SG_  "Platform_VMCU1_Sig" ENUM  "No","Yes";
BA_DEF_ BU_  "NmStationAddress" INT 0 255;
BA_DEF_  "NmAsrWaitBusSleepTime" INT 0 65535;
BA_DEF_  "NmAsrTimeoutTime" INT 0 65535;
BA_DEF_  "NmAsrRepeatMessageTime" INT 0 65535;
BA_DEF_ BU_  "NmAsrNodeIdentifier" HEX 0 253;
BA_DEF_ BU_  "NmAsrNode" ENUM  "No","Yes";
BA_DEF_  "NmAsrMessageCount" INT 1 256;
BA_DEF_ BO_  "NmAsrMessage" ENUM  "No","Yes";
BA_DEF_  "NmAsrCanMsgCycleTime" INT 0 65535;
BA_DEF_  "NmAsrBaseAddress" HEX 0 536870911;
BA_DEF_ SG_  "NeedsUpdateBit" ENUM  "No","Yes";
BA_DEF_ SG_  "MmAnSignal" ENUM  "No","Yes";
BA_DEF_ SG_  "GenSigMaxLatency" INT 0 65535;
BA_DEF_ SG_  "GenSigILSupport" ENUM  "Yes","No";
BA_DEF_ BO_  "GenMsgILSupport" ENUM  "No","Yes";
BA_DEF_ SG_  "E2EProfile" STRING ;
BA_DEF_  "E2EP05WindowSize" INT 0 65535;
BA_DEF_  "E2EP05ProfileName" STRING ;
BA_DEF_  "E2EP05MinOkStateValid" INT 0 65535;
BA_DEF_  "E2EP05MinOkStateInvalid" INT 0 65535;
BA_DEF_  "E2EP05MinOkStateInit" INT 0 65535;
BA_DEF_  "E2EP05MaxErrorStateValid" INT 0 65535;
BA_DEF_  "E2EP05MaxErrorStateInvalid" INT 0 65535;
BA_DEF_  "E2EP05MaxErrorStateInit" INT 0 65535;
BA_DEF_  "E2EP05MaxDeltaCounter" INT 0 65535;
BA_DEF_  "E2EP01WindowSize" INT 0 65535;
BA_DEF_  "E2EP01SyncCounterInit" INT 0 65535;
BA_DEF_  "E2EP01ProfileName" STRING ;
BA_DEF_  "E2EP01MinOkStateValid" INT 0 65535;
BA_DEF_  "E2EP01MinOkStateInvalid" INT 0 65535;
BA_DEF_  "E2EP01MinOkStateInit" INT 0 65535;
BA_DEF_  "E2EP01MaxNoNewOrRepeatedData" INT 0 65535;
BA_DEF_  "E2EP01MaxErrorStateValid" INT 0 65535;
BA_DEF_  "E2EP01MaxErrorStateInvalid" INT 0 65535;
BA_DEF_  "E2EP01MaxErrorStateInit" INT 0 65535;
BA_DEF_  "E2EP01MaxDeltaCounter" INT 0 65535;
BA_DEF_  "E2EP01DataIdMode" ENUM  "all16Bit","alternating8Bit","lower12Bit","lower8Bit";
BA_DEF_  "E2EP01CounterOffset" INT 0 65535;
BA_DEF_ SG_  "E2EDataLength" INT 0 65535;
BA_DEF_ SG_  "E2EDataId" INT 0 65535;
BA_DEF_ BO_  "DiagUUDTResponse" ENUM  "No","Yes";
BA_DEF_ BO_  "DiagState" ENUM  "No","Yes";
BA_DEF_ BO_  "DiagResponse" ENUM  "No","Yes";
BA_DEF_ BO_  "DiagRequest" ENUM  "No","Yes";
BA_DEF_ BO_  "DiagConnection" HEX 0 65535;
BA_DEF_  "DBName" STRING ;
BA_DEF_ BO_  "CanTpSTmin" INT 0 255;
BA_DEF_ BO_  "CanTpFcFrameId" HEX 0 2147483647;
BA_DEF_ BO_  "CanTpBs" INT 0 255;
BA_DEF_  "BusType" STRING ;
BA_DEF_REL_ BU_SG_REL_  "GenSigTimeoutTime" INT 0 65535;
BA_DEF_REL_ BU_SG_REL_  "GenSigFirstTimeoutTime" INT 0 65535;
BA_DEF_DEF_  "GenMsgStartDelayTime" 0;
BA_DEF_DEF_  "GenMsgDelayTime" 0;
BA_DEF_DEF_  "GenMsgCycleTime" 0;
BA_DEF_DEF_  "GenMsgSendType" "Cyclic";
BA_DEF_DEF_  "GenSigStartValue" 0;
BA_DEF_DEF_  "GenSigCycleTimeActive" 0;
BA_DEF_DEF_  "GenSigCycleTime" 0;
BA_DEF_DEF_  "GenSigSendType" "Cyclic";
BA_DEF_DEF_  "Baudrate" 500000;
BA_DEF_DEF_  "NmType" "";
BA_DEF_DEF_  "Manufacturer" "VOLVO_AB";
BA_DEF_DEF_  "VersionYear" 0;
BA_DEF_DEF_  "VersionNumber" 0;
BA_DEF_DEF_  "VersionMonth" 1;
BA_DEF_DEF_  "VersionDay" 1;
BA_DEF_DEF_  "VFrameFormat" "ExtendedCAN";
BA_DEF_DEF_  "TpOwnSystemEcuNumber" 0;
BA_DEF_DEF_  "SigType" "Default";
BA_DEF_DEF_  "SeToolVersion_SIGNAL" "";
BA_DEF_DEF_  "SeToolUniqueID_SIGNAL" "";
BA_DEF_DEF_  "SeToolOwnerSigGroup_SIGNAL" "";
BA_DEF_DEF_  "SeToolOwnerSigGroupID_SIGNAL" "";
BA_DEF_DEF_  "SeToolName_SIGNAL" "";
BA_DEF_DEF_  "SeToolItemID_SIGNAL" "";
BA_DEF_DEF_  "SeToolAncestorID_SIGNAL" "";
BA_DEF_DEF_  "Platform_VMCU1_Sig" "No";
BA_DEF_DEF_  "NmStationAddress" 254;
BA_DEF_DEF_  "NmAsrWaitBusSleepTime" 750;
BA_DEF_DEF_  "NmAsrTimeoutTime" 5000;
BA_DEF_DEF_  "NmAsrRepeatMessageTime" 300;
BA_DEF_DEF_  "NmAsrNodeIdentifier" 0;
BA_DEF_DEF_  "NmAsrNode" "Yes";
BA_DEF_DEF_  "NmAsrMessageCount" 256;
BA_DEF_DEF_  "NmAsrMessage" "No";
BA_DEF_DEF_  "NmAsrCanMsgCycleTime" 200;
BA_DEF_DEF_  "NmAsrBaseAddress" 486506496;
BA_DEF_DEF_  "NeedsUpdateBit" "No";
BA_DEF_DEF_  "MmAnSignal" "No";
BA_DEF_DEF_  "GenSigMaxLatency" 0;
BA_DEF_DEF_  "GenSigILSupport" "Yes";
BA_DEF_DEF_  "GenMsgILSupport" "Yes";
BA_DEF_DEF_  "E2EProfile" "none";
BA_DEF_DEF_  "E2EP05WindowSize" 5;
BA_DEF_DEF_  "E2EP05ProfileName" "PROFILE_05";
BA_DEF_DEF_  "E2EP05MinOkStateValid" 1;
BA_DEF_DEF_  "E2EP05MinOkStateInvalid" 3;
BA_DEF_DEF_  "E2EP05MinOkStateInit" 1;
BA_DEF_DEF_  "E2EP05MaxErrorStateValid" 3;
BA_DEF_DEF_  "E2EP05MaxErrorStateInvalid" 1;
BA_DEF_DEF_  "E2EP05MaxErrorStateInit" 2;
BA_DEF_DEF_  "E2EP05MaxDeltaCounter" 3;
BA_DEF_DEF_  "E2EP01WindowSize" 5;
BA_DEF_DEF_  "E2EP01SyncCounterInit" 1;
BA_DEF_DEF_  "E2EP01ProfileName" "PROFILE_01";
BA_DEF_DEF_  "E2EP01MinOkStateValid" 1;
BA_DEF_DEF_  "E2EP01MinOkStateInvalid" 3;
BA_DEF_DEF_  "E2EP01MinOkStateInit" 1;
BA_DEF_DEF_  "E2EP01MaxNoNewOrRepeatedData" 5;
BA_DEF_DEF_  "E2EP01MaxErrorStateValid" 3;
BA_DEF_DEF_  "E2EP01MaxErrorStateInvalid" 1;
BA_DEF_DEF_  "E2EP01MaxErrorStateInit" 2;
BA_DEF_DEF_  "E2EP01MaxDeltaCounter" 3;
BA_DEF_DEF_  "E2EP01DataIdMode" "all16Bit";
BA_DEF_DEF_  "E2EP01CounterOffset" 8;
BA_DEF_DEF_  "E2EDataLength" 0;
BA_DEF_DEF_  "E2EDataId" 0;
BA_DEF_DEF_  "DiagUUDTResponse" "No";
BA_DEF_DEF_  "DiagState" "No";
BA_DEF_DEF_  "DiagResponse" "No";
BA_DEF_DEF_  "DiagRequest" "No";
BA_DEF_DEF_  "DiagConnection" 0;
BA_DEF_DEF_  "DBName" "";
BA_DEF_DEF_  "CanTpSTmin" 0;
BA_DEF_DEF_  "CanTpFcFrameId" 2147483647;
BA_DEF_DEF_  "CanTpBs" 255;
BA_DEF_DEF_  "BusType" "";
BA_DEF_DEF_REL_ "GenSigTimeoutTime" 0;
BA_DEF_DEF_REL_ "GenSigFirstTimeoutTime" 0;
BA_ "NmType" "NmAsr";
BA_ "BusType" "CAN";
BA_ "VersionDay" 4;
BA_ "VersionMonth" 4;
BA_ "VersionNumber" 1;
BA_ "VersionYear" 25;
BA_ "DBName" "CabSubnet";
BA_ "TpOwnSystemEcuNumber" BU_ WRCS 38;
BA_ "NmAsrNodeIdentifier" BU_ WRCS 38;
BA_ "TpOwnSystemEcuNumber" BU_ SRS 83;
BA_ "NmAsrNodeIdentifier" BU_ SRS 83;
BA_ "TpOwnSystemEcuNumber" BU_ LECM3 162;
BA_ "NmAsrNodeIdentifier" BU_ LECM3 162;
BA_ "TpOwnSystemEcuNumber" BU_ LECM1 162;
BA_ "NmAsrNodeIdentifier" BU_ LECM1 162;
BA_ "TpOwnSystemEcuNumber" BU_ CMS 147;
BA_ "NmAsrNodeIdentifier" BU_ CMS 147;
BA_ "TpOwnSystemEcuNumber" BU_ CIOM 64;
BA_ "NmAsrNodeIdentifier" BU_ CIOM 64;
BA_ "TpOwnSystemEcuNumber" BU_ CCM 152;
BA_ "NmAsrNodeIdentifier" BU_ CCM 152;
BA_ "GenMsgCycleTime" BO_ 2499772198 50;
BA_ "GenMsgStartDelayTime" BO_ 2499772198 15;
BA_ "GenMsgCycleTime" BO_ 2432679743 20;
BA_ "GenMsgStartDelayTime" BO_ 2432679743 5;
BA_ "GenMsgCycleTime" BO_ 2365554559 10;
BA_ "DiagConnection" BO_ 2671902706 62035;
BA_ "DiagState" BO_ 2671902706 1;
BA_ "GenMsgILSupport" BO_ 2671902706 0;
BA_ "GenMsgSendType" BO_ 2671902706 8;
BA_ "GenMsgCycleTime" BO_ 2516576083 100;
BA_ "GenMsgStartDelayTime" BO_ 2516576083 10;
BA_ "GenMsgCycleTime" BO_ 2432689747 20;
BA_ "GenMsgCycleTime" BO_ 2499788607 50;
BA_ "GenMsgStartDelayTime" BO_ 2499788607 5;
BA_ "GenMsgCycleTime" BO_ 2432689491 20;
BA_ "GenMsgILSupport" BO_ 2658975757 0;
BA_ "GenMsgSendType" BO_ 2658975757 8;
BA_ "GenMsgILSupport" BO_ 2658975756 0;
BA_ "GenMsgSendType" BO_ 2658975756 8;
BA_ "GenMsgILSupport" BO_ 2658975755 0;
BA_ "GenMsgSendType" BO_ 2658975755 8;
BA_ "GenMsgILSupport" BO_ 2658967560 0;
BA_ "GenMsgSendType" BO_ 2658967560 8;
BA_ "DiagConnection" BO_ 2671833762 62114;
BA_ "DiagResponse" BO_ 2671833762 1;
BA_ "GenMsgILSupport" BO_ 2671833762 0;
BA_ "GenMsgSendType" BO_ 2671833762 8;
BA_ "DiagConnection" BO_ 2671833752 62104;
BA_ "DiagResponse" BO_ 2671833752 1;
BA_ "GenMsgILSupport" BO_ 2671833752 0;
BA_ "GenMsgSendType" BO_ 2671833752 8;
BA_ "DiagConnection" BO_ 2671833747 62099;
BA_ "DiagResponse" BO_ 2671833747 1;
BA_ "GenMsgILSupport" BO_ 2671833747 0;
BA_ "GenMsgSendType" BO_ 2671833747 8;
BA_ "CanTpSTmin" BO_ 2671833683 1;
BA_ "DiagConnection" BO_ 2671833683 62035;
BA_ "DiagResponse" BO_ 2671833683 1;
BA_ "GenMsgILSupport" BO_ 2671833683 0;
BA_ "GenMsgSendType" BO_ 2671833683 8;
BA_ "DiagConnection" BO_ 2671833638 61990;
BA_ "DiagResponse" BO_ 2671833638 1;
BA_ "GenMsgILSupport" BO_ 2671833638 0;
BA_ "GenMsgSendType" BO_ 2671833638 8;
BA_ "DiagConnection" BO_ 2564485459 61779;
BA_ "DiagResponse" BO_ 2564485459 1;
BA_ "GenMsgILSupport" BO_ 2564485459 0;
BA_ "GenMsgSendType" BO_ 2564485459 8;
BA_ "DiagConnection" BO_ 2671813362 62114;
BA_ "DiagRequest" BO_ 2671813362 1;
BA_ "GenMsgILSupport" BO_ 2671813362 0;
BA_ "GenMsgSendType" BO_ 2671813362 8;
BA_ "DiagConnection" BO_ 2671810802 62104;
BA_ "DiagRequest" BO_ 2671810802 1;
BA_ "GenMsgILSupport" BO_ 2671810802 0;
BA_ "GenMsgSendType" BO_ 2671810802 8;
BA_ "DiagConnection" BO_ 2671809522 62099;
BA_ "DiagRequest" BO_ 2671809522 1;
BA_ "GenMsgILSupport" BO_ 2671809522 0;
BA_ "GenMsgSendType" BO_ 2671809522 8;
BA_ "DiagConnection" BO_ 2671793138 62035;
BA_ "DiagRequest" BO_ 2671793138 1;
BA_ "GenMsgILSupport" BO_ 2671793138 0;
BA_ "GenMsgSendType" BO_ 2671793138 8;
BA_ "DiagConnection" BO_ 2564445169 61779;
BA_ "DiagRequest" BO_ 2564445169 1;
BA_ "GenMsgILSupport" BO_ 2564445169 0;
BA_ "GenMsgSendType" BO_ 2564445169 8;
BA_ "DiagConnection" BO_ 2671781618 61990;
BA_ "DiagRequest" BO_ 2671781618 1;
BA_ "GenMsgILSupport" BO_ 2671781618 0;
BA_ "GenMsgSendType" BO_ 2671781618 8;
BA_ "GenMsgILSupport" BO_ 2633990182 0;
BA_ "NmAsrMessage" BO_ 2633990182 1;
BA_ "GenMsgSendType" BO_ 2633990182 8;
BA_ "GenMsgILSupport" BO_ 2633990227 0;
BA_ "NmAsrMessage" BO_ 2633990227 1;
BA_ "GenMsgSendType" BO_ 2633990227 8;
BA_ "GenMsgILSupport" BO_ 2633990306 0;
BA_ "NmAsrMessage" BO_ 2633990306 1;
BA_ "GenMsgSendType" BO_ 2633990306 8;
BA_ "GenMsgILSupport" BO_ 2633990291 0;
BA_ "NmAsrMessage" BO_ 2633990291 1;
BA_ "GenMsgSendType" BO_ 2633990291 8;
BA_ "GenMsgILSupport" BO_ 2633990208 0;
BA_ "NmAsrMessage" BO_ 2633990208 1;
BA_ "GenMsgSendType" BO_ 2633990208 8;
BA_ "GenMsgILSupport" BO_ 2633990296 0;
BA_ "NmAsrMessage" BO_ 2633990296 1;
BA_ "GenMsgSendType" BO_ 2633990296 8;
BA_ "GenMsgCycleTime" BO_ 2549208482 200;
BA_ "GenMsgDelayTime" BO_ 2549208482 20;
BA_ "GenMsgStartDelayTime" BO_ 2549208482 5;
BA_ "GenMsgCycleTime" BO_ 2566337698 500;
BA_ "GenMsgDelayTime" BO_ 2566337698 50;
BA_ "GenMsgStartDelayTime" BO_ 2566337698 10;
BA_ "GenMsgSendType" BO_ 2499772322 8;
BA_ "GenMsgDelayTime" BO_ 2499772322 50;
BA_ "GenMsgCycleTime" BO_ 2489730210 50;
BA_ "GenMsgStartDelayTime" BO_ 2489730210 10;
BA_ "GenMsgSendType" BO_ 2566043647 8;
BA_ "GenMsgDelayTime" BO_ 2566043647 200;
BA_ "GenMsgStartDelayTime" BO_ 2566043647 50;
BA_ "GenMsgCycleTime" BO_ 2432693154 10;
BA_ "GenMsgStartDelayTime" BO_ 2432693154 5;
BA_ "DiagConnection" BO_ 2671902708 62469;
BA_ "DiagState" BO_ 2671902708 1;
BA_ "GenMsgILSupport" BO_ 2671902708 0;
BA_ "GenMsgSendType" BO_ 2671902708 8;
BA_ "DiagConnection" BO_ 2671964834 62114;
BA_ "DiagUUDTResponse" BO_ 2671964834 1;
BA_ "GenMsgILSupport" BO_ 2671964834 0;
BA_ "GenMsgSendType" BO_ 2671964834 8;
BA_ "DiagConnection" BO_ 2671964824 62104;
BA_ "DiagUUDTResponse" BO_ 2671964824 1;
BA_ "GenMsgILSupport" BO_ 2671964824 0;
BA_ "GenMsgSendType" BO_ 2671964824 8;
BA_ "DiagConnection" BO_ 2671964819 62099;
BA_ "DiagUUDTResponse" BO_ 2671964819 1;
BA_ "GenMsgILSupport" BO_ 2671964819 0;
BA_ "GenMsgSendType" BO_ 2671964819 8;
BA_ "DiagConnection" BO_ 2671964755 62035;
BA_ "DiagUUDTResponse" BO_ 2671964755 1;
BA_ "GenMsgILSupport" BO_ 2671964755 0;
BA_ "GenMsgSendType" BO_ 2671964755 8;
BA_ "DiagConnection" BO_ 2671964710 61990;
BA_ "DiagUUDTResponse" BO_ 2671964710 1;
BA_ "GenMsgILSupport" BO_ 2671964710 0;
BA_ "GenMsgSendType" BO_ 2671964710 8;
BA_ "DiagConnection" BO_ 2671834259 62611;
BA_ "DiagResponse" BO_ 2671834259 1;
BA_ "GenMsgILSupport" BO_ 2671834259 0;
BA_ "GenMsgSendType" BO_ 2671834259 8;
BA_ "DiagConnection" BO_ 2671834274 62626;
BA_ "DiagResponse" BO_ 2671834274 1;
BA_ "GenMsgILSupport" BO_ 2671834274 0;
BA_ "GenMsgSendType" BO_ 2671834274 8;
BA_ "DiagConnection" BO_ 2671834264 62616;
BA_ "DiagResponse" BO_ 2671834264 1;
BA_ "GenMsgILSupport" BO_ 2671834264 0;
BA_ "GenMsgSendType" BO_ 2671834264 8;
BA_ "CanTpSTmin" BO_ 2671834195 1;
BA_ "DiagConnection" BO_ 2671834195 62547;
BA_ "DiagResponse" BO_ 2671834195 1;
BA_ "GenMsgILSupport" BO_ 2671834195 0;
BA_ "GenMsgSendType" BO_ 2671834195 8;
BA_ "DiagConnection" BO_ 2671834150 62502;
BA_ "DiagResponse" BO_ 2671834150 1;
BA_ "GenMsgILSupport" BO_ 2671834150 0;
BA_ "GenMsgSendType" BO_ 2671834150 8;
BA_ "DiagConnection" BO_ 2671834003 62355;
BA_ "DiagResponse" BO_ 2671834003 1;
BA_ "GenMsgILSupport" BO_ 2671834003 0;
BA_ "GenMsgSendType" BO_ 2671834003 8;
BA_ "DiagConnection" BO_ 2671834018 62370;
BA_ "DiagResponse" BO_ 2671834018 1;
BA_ "GenMsgILSupport" BO_ 2671834018 0;
BA_ "GenMsgSendType" BO_ 2671834018 8;
BA_ "DiagConnection" BO_ 2671834008 62360;
BA_ "DiagResponse" BO_ 2671834008 1;
BA_ "GenMsgILSupport" BO_ 2671834008 0;
BA_ "GenMsgSendType" BO_ 2671834008 8;
BA_ "CanTpSTmin" BO_ 2671833939 1;
BA_ "DiagConnection" BO_ 2671833939 62291;
BA_ "DiagResponse" BO_ 2671833939 1;
BA_ "GenMsgILSupport" BO_ 2671833939 0;
BA_ "GenMsgSendType" BO_ 2671833939 8;
BA_ "DiagConnection" BO_ 2671833894 62246;
BA_ "DiagResponse" BO_ 2671833894 1;
BA_ "GenMsgILSupport" BO_ 2671833894 0;
BA_ "GenMsgSendType" BO_ 2671833894 8;
BA_ "DiagConnection" BO_ 2671809524 62611;
BA_ "DiagRequest" BO_ 2671809524 1;
BA_ "GenMsgILSupport" BO_ 2671809524 0;
BA_ "GenMsgSendType" BO_ 2671809524 8;
BA_ "DiagConnection" BO_ 2671813364 62626;
BA_ "DiagRequest" BO_ 2671813364 1;
BA_ "GenMsgILSupport" BO_ 2671813364 0;
BA_ "GenMsgSendType" BO_ 2671813364 8;
BA_ "DiagConnection" BO_ 2671810804 62616;
BA_ "DiagRequest" BO_ 2671810804 1;
BA_ "GenMsgILSupport" BO_ 2671810804 0;
BA_ "GenMsgSendType" BO_ 2671810804 8;
BA_ "DiagConnection" BO_ 2671793140 62547;
BA_ "DiagRequest" BO_ 2671793140 1;
BA_ "GenMsgILSupport" BO_ 2671793140 0;
BA_ "GenMsgSendType" BO_ 2671793140 8;
BA_ "DiagConnection" BO_ 2671781620 62502;
BA_ "DiagRequest" BO_ 2671781620 1;
BA_ "GenMsgILSupport" BO_ 2671781620 0;
BA_ "GenMsgSendType" BO_ 2671781620 8;
BA_ "DiagConnection" BO_ 2671809523 62355;
BA_ "DiagRequest" BO_ 2671809523 1;
BA_ "GenMsgILSupport" BO_ 2671809523 0;
BA_ "GenMsgSendType" BO_ 2671809523 8;
BA_ "DiagConnection" BO_ 2671813363 62370;
BA_ "DiagRequest" BO_ 2671813363 1;
BA_ "GenMsgILSupport" BO_ 2671813363 0;
BA_ "GenMsgSendType" BO_ 2671813363 8;
BA_ "DiagConnection" BO_ 2671810803 62360;
BA_ "DiagRequest" BO_ 2671810803 1;
BA_ "GenMsgILSupport" BO_ 2671810803 0;
BA_ "GenMsgSendType" BO_ 2671810803 8;
BA_ "DiagConnection" BO_ 2671793139 62291;
BA_ "DiagRequest" BO_ 2671793139 1;
BA_ "GenMsgILSupport" BO_ 2671793139 0;
BA_ "GenMsgSendType" BO_ 2671793139 8;
BA_ "DiagConnection" BO_ 2671781619 62246;
BA_ "DiagRequest" BO_ 2671781619 1;
BA_ "GenMsgILSupport" BO_ 2671781619 0;
BA_ "GenMsgSendType" BO_ 2671781619 8;
BA_ "GenMsgCycleTime" BO_ 2567057439 1000;
BA_ "GenMsgDelayTime" BO_ 2567057439 90;
BA_ "GenMsgStartDelayTime" BO_ 2567057439 15;
BA_ "GenMsgCycleTime" BO_ 2567057438 1000;
BA_ "GenMsgDelayTime" BO_ 2567057438 95;
BA_ "GenMsgStartDelayTime" BO_ 2567057438 20;
BA_ "GenMsgCycleTime" BO_ 2567057437 1000;
BA_ "GenMsgDelayTime" BO_ 2567057437 95;
BA_ "GenMsgStartDelayTime" BO_ 2567057437 50;
BA_ "GenMsgCycleTime" BO_ 2567049378 1000;
BA_ "GenMsgDelayTime" BO_ 2567049378 85;
BA_ "GenMsgCycleTime" BO_ 2567049363 1000;
BA_ "GenMsgDelayTime" BO_ 2567049363 85;
BA_ "GenMsgStartDelayTime" BO_ 2567049363 5;
BA_ "GenMsgCycleTime" BO_ 2567057436 1000;
BA_ "GenMsgDelayTime" BO_ 2567057436 95;
BA_ "GenMsgStartDelayTime" BO_ 2567057436 55;
BA_ "GenMsgSendType" BO_ 2634020435 8;
BA_ "GenMsgDelayTime" BO_ 2634020435 50;
BA_ "GenMsgStartDelayTime" BO_ 2634020435 50;
BA_ "GenMsgSendType" BO_ 2634020514 8;
BA_ "GenMsgDelayTime" BO_ 2634020514 50;
BA_ "GenMsgStartDelayTime" BO_ 2634020514 50;
BA_ "GenMsgSendType" BO_ 2634022306 8;
BA_ "GenMsgDelayTime" BO_ 2634022306 50;
BA_ "GenMsgSendType" BO_ 2634020499 8;
BA_ "GenMsgDelayTime" BO_ 2634020499 50;
BA_ "GenMsgSendType" BO_ 2634020504 8;
BA_ "GenMsgDelayTime" BO_ 2634020504 50;
BA_ "GenMsgStartDelayTime" BO_ 2634020504 50;
BA_ "GenMsgSendType" BO_ 2634020179 8;
BA_ "GenMsgDelayTime" BO_ 2634020179 50;
BA_ "GenMsgStartDelayTime" BO_ 2634020179 50;
BA_ "GenMsgSendType" BO_ 2634020258 8;
BA_ "GenMsgDelayTime" BO_ 2634020258 50;
BA_ "GenMsgStartDelayTime" BO_ 2634020258 50;
BA_ "GenMsgSendType" BO_ 2634022050 8;
BA_ "GenMsgDelayTime" BO_ 2634022050 50;
BA_ "GenMsgSendType" BO_ 2634020243 8;
BA_ "GenMsgDelayTime" BO_ 2634020243 50;
BA_ "GenMsgSendType" BO_ 2634020248 8;
BA_ "GenMsgDelayTime" BO_ 2634020248 50;
BA_ "GenMsgStartDelayTime" BO_ 2634020248 50;
BA_ "GenMsgSendType" BO_ 2634019923 8;
BA_ "GenMsgDelayTime" BO_ 2634019923 50;
BA_ "GenMsgStartDelayTime" BO_ 2634019923 50;
BA_ "GenMsgSendType" BO_ 2634020002 8;
BA_ "GenMsgDelayTime" BO_ 2634020002 50;
BA_ "GenMsgStartDelayTime" BO_ 2634020002 50;
BA_ "GenMsgSendType" BO_ 2634021794 8;
BA_ "GenMsgDelayTime" BO_ 2634021794 50;
BA_ "GenMsgSendType" BO_ 2634019987 8;
BA_ "GenMsgDelayTime" BO_ 2634019987 50;
BA_ "GenMsgSendType" BO_ 2634019992 8;
BA_ "GenMsgDelayTime" BO_ 2634019992 50;
BA_ "GenMsgStartDelayTime" BO_ 2634019992 50;
BA_ "GenMsgSendType" BO_ 2634019667 8;
BA_ "GenMsgDelayTime" BO_ 2634019667 50;
BA_ "GenMsgStartDelayTime" BO_ 2634019667 50;
BA_ "GenMsgSendType" BO_ 2634019746 8;
BA_ "GenMsgDelayTime" BO_ 2634019746 50;
BA_ "GenMsgStartDelayTime" BO_ 2634019746 50;
BA_ "GenMsgSendType" BO_ 2634021538 8;
BA_ "GenMsgDelayTime" BO_ 2634021538 50;
BA_ "GenMsgSendType" BO_ 2634019731 8;
BA_ "GenMsgDelayTime" BO_ 2634019731 50;
BA_ "GenMsgSendType" BO_ 2634019411 8;
BA_ "GenMsgDelayTime" BO_ 2634019411 50;
BA_ "GenMsgStartDelayTime" BO_ 2634019411 50;
BA_ "GenMsgSendType" BO_ 2634019490 8;
BA_ "GenMsgDelayTime" BO_ 2634019490 50;
BA_ "GenMsgStartDelayTime" BO_ 2634019490 50;
BA_ "GenMsgSendType" BO_ 2634021282 8;
BA_ "GenMsgDelayTime" BO_ 2634021282 50;
BA_ "GenMsgSendType" BO_ 2634019475 8;
BA_ "GenMsgDelayTime" BO_ 2634019475 50;
BA_ "GenMsgCycleTime" BO_ 2499790739 50;
BA_ "GenMsgStartDelayTime" BO_ 2499790739 10;
BA_ "GenMsgCycleTime" BO_ 2499790995 50;
BA_ "GenMsgStartDelayTime" BO_ 2499790995 10;
BA_ "GenSigSendType" SG_ 2499772198 TipperShakerRequest_UB 7;
BA_ "GenSigSendType" SG_ 2499772198 TipperUpDownRequest_UB 7;
BA_ "GenSigSendType" SG_ 2499772198 ExtraBbWrcWatchdog_UB 7;
BA_ "GenSigCycleTime" SG_ 2499772198 TipperTarpaulinRequest 100;
BA_ "GenSigCycleTimeActive" SG_ 2499772198 TipperTarpaulinRequest 100;
BA_ "GenSigStartValue" SG_ 2499772198 TipperTarpaulinRequest 7;
BA_ "GenSigMaxLatency" SG_ 2499772198 TipperTarpaulinRequest 65;
BA_ "NeedsUpdateBit" SG_ 2499772198 TipperTarpaulinRequest 1;
BA_ "GenSigSendType" SG_ 2499772198 TipperEmergencyStop_UB 7;
BA_ "GenSigCycleTime" SG_ 2499772198 TipperUpDownRequest 100;
BA_ "GenSigCycleTimeActive" SG_ 2499772198 TipperUpDownRequest 100;
BA_ "GenSigStartValue" SG_ 2499772198 TipperUpDownRequest 7;
BA_ "GenSigMaxLatency" SG_ 2499772198 TipperUpDownRequest 65;
BA_ "NeedsUpdateBit" SG_ 2499772198 TipperUpDownRequest 1;
BA_ "GenSigCycleTime" SG_ 2499772198 TailLiftMotionRequest 100;
BA_ "GenSigCycleTimeActive" SG_ 2499772198 TailLiftMotionRequest 100;
BA_ "GenSigStartValue" SG_ 2499772198 TailLiftMotionRequest 7;
BA_ "GenSigMaxLatency" SG_ 2499772198 TailLiftMotionRequest 65;
BA_ "NeedsUpdateBit" SG_ 2499772198 TailLiftMotionRequest 1;
BA_ "GenSigSendType" SG_ 2499772198 TipperTippingBodySelection_UB 7;
BA_ "GenSigCycleTime" SG_ 2499772198 TipperEmergencyStop 100;
BA_ "GenSigCycleTimeActive" SG_ 2499772198 TipperEmergencyStop 100;
BA_ "GenSigStartValue" SG_ 2499772198 TipperEmergencyStop 3;
BA_ "GenSigMaxLatency" SG_ 2499772198 TipperEmergencyStop 65;
BA_ "NeedsUpdateBit" SG_ 2499772198 TipperEmergencyStop 1;
BA_ "GenSigCycleTime" SG_ 2499772198 ExtraBbWrcWatchdog 100;
BA_ "GenSigCycleTimeActive" SG_ 2499772198 ExtraBbWrcWatchdog 100;
BA_ "GenSigStartValue" SG_ 2499772198 ExtraBbWrcWatchdog 3;
BA_ "GenSigMaxLatency" SG_ 2499772198 ExtraBbWrcWatchdog 65;
BA_ "NeedsUpdateBit" SG_ 2499772198 ExtraBbWrcWatchdog 1;
BA_ "GenSigCycleTime" SG_ 2499772198 TipperTailGateRequest 100;
BA_ "GenSigCycleTimeActive" SG_ 2499772198 TipperTailGateRequest 100;
BA_ "GenSigStartValue" SG_ 2499772198 TipperTailGateRequest 7;
BA_ "GenSigMaxLatency" SG_ 2499772198 TipperTailGateRequest 65;
BA_ "NeedsUpdateBit" SG_ 2499772198 TipperTailGateRequest 1;
BA_ "GenSigCycleTime" SG_ 2499772198 TipperTippingBodySelection 100;
BA_ "GenSigCycleTimeActive" SG_ 2499772198 TipperTippingBodySelection 100;
BA_ "GenSigStartValue" SG_ 2499772198 TipperTippingBodySelection 3;
BA_ "GenSigMaxLatency" SG_ 2499772198 TipperTippingBodySelection 65;
BA_ "NeedsUpdateBit" SG_ 2499772198 TipperTippingBodySelection 1;
BA_ "GenSigSendType" SG_ 2499772198 TipperTarpaulinRequest_UB 7;
BA_ "GenSigSendType" SG_ 2499772198 TailLiftMotionRequest_UB 7;
BA_ "GenSigCycleTime" SG_ 2499772198 TipperShakerRequest 100;
BA_ "GenSigCycleTimeActive" SG_ 2499772198 TipperShakerRequest 100;
BA_ "GenSigStartValue" SG_ 2499772198 TipperShakerRequest 3;
BA_ "GenSigMaxLatency" SG_ 2499772198 TipperShakerRequest 65;
BA_ "NeedsUpdateBit" SG_ 2499772198 TipperShakerRequest 1;
BA_ "GenSigSendType" SG_ 2499772198 TipperTailGateRequest_UB 7;
BA_ "GenSigCycleTime" SG_ 2432679743 WRC5thWheelRequest 100;
BA_ "GenSigCycleTimeActive" SG_ 2432679743 WRC5thWheelRequest 100;
BA_ "GenSigStartValue" SG_ 2432679743 WRC5thWheelRequest 3;
BA_ "GenSigMaxLatency" SG_ 2432679743 WRC5thWheelRequest 35;
BA_ "GenSigSendType" SG_ 2432679743 WRCEngineStopRequest_UB 7;
BA_ "GenSigCycleTime" SG_ 2432679743 WRC_Docking_stat 100;
BA_ "GenSigCycleTimeActive" SG_ 2432679743 WRC_Docking_stat 100;
BA_ "GenSigStartValue" SG_ 2432679743 WRC_Docking_stat 3;
BA_ "GenSigCycleTime" SG_ 2432679743 WRCLevelUserMemoryAction 100;
BA_ "GenSigCycleTimeActive" SG_ 2432679743 WRCLevelUserMemoryAction 100;
BA_ "GenSigStartValue" SG_ 2432679743 WRCLevelUserMemoryAction 7;
BA_ "GenSigMaxLatency" SG_ 2432679743 WRCLevelUserMemoryAction 35;
BA_ "GenSigCycleTime" SG_ 2432679743 WRCLevelUserMemory 100;
BA_ "GenSigCycleTimeActive" SG_ 2432679743 WRCLevelUserMemory 100;
BA_ "GenSigStartValue" SG_ 2432679743 WRCLevelUserMemory 15;
BA_ "GenSigMaxLatency" SG_ 2432679743 WRCLevelUserMemory 35;
BA_ "GenSigSendType" SG_ 2432679743 WRCEngineStartRequest_UB 7;
BA_ "GenSigCycleTime" SG_ 2432679743 WrcEngSpdCtrlResumeButtonStat 100;
BA_ "GenSigCycleTimeActive" SG_ 2432679743 WrcEngSpdCtrlResumeButtonStat 100;
BA_ "GenSigStartValue" SG_ 2432679743 WrcEngSpdCtrlResumeButtonStat 3;
BA_ "GenSigMaxLatency" SG_ 2432679743 WrcEngSpdCtrlResumeButtonStat 35;
BA_ "GenSigCycleTime" SG_ 2432679743 WRCBeaconRequest 100;
BA_ "GenSigCycleTimeActive" SG_ 2432679743 WRCBeaconRequest 100;
BA_ "GenSigStartValue" SG_ 2432679743 WRCBeaconRequest 3;
BA_ "GenSigMaxLatency" SG_ 2432679743 WRCBeaconRequest 35;
BA_ "GenSigCycleTime" SG_ 2432679743 WrcEngSpdCtrlDecreaseButtStat 100;
BA_ "GenSigCycleTimeActive" SG_ 2432679743 WrcEngSpdCtrlDecreaseButtStat 100;
BA_ "GenSigStartValue" SG_ 2432679743 WrcEngSpdCtrlDecreaseButtStat 3;
BA_ "GenSigMaxLatency" SG_ 2432679743 WrcEngSpdCtrlDecreaseButtStat 35;
BA_ "GenSigCycleTime" SG_ 2432679743 WRCEngineStartRequest 100;
BA_ "GenSigCycleTimeActive" SG_ 2432679743 WRCEngineStartRequest 100;
BA_ "GenSigStartValue" SG_ 2432679743 WRCEngineStartRequest 3;
BA_ "GenSigMaxLatency" SG_ 2432679743 WRCEngineStartRequest 35;
BA_ "NeedsUpdateBit" SG_ 2432679743 WRCEngineStartRequest 1;
BA_ "GenSigCycleTime" SG_ 2432679743 WrcEngSpdCtrlEnableStatus 100;
BA_ "GenSigCycleTimeActive" SG_ 2432679743 WrcEngSpdCtrlEnableStatus 100;
BA_ "GenSigStartValue" SG_ 2432679743 WrcEngSpdCtrlEnableStatus 3;
BA_ "GenSigMaxLatency" SG_ 2432679743 WrcEngSpdCtrlEnableStatus 35;
BA_ "GenSigCycleTime" SG_ 2432679743 WRCCabBodyWLightsRqst 100;
BA_ "GenSigCycleTimeActive" SG_ 2432679743 WRCCabBodyWLightsRqst 100;
BA_ "GenSigStartValue" SG_ 2432679743 WRCCabBodyWLightsRqst 3;
BA_ "GenSigMaxLatency" SG_ 2432679743 WRCCabBodyWLightsRqst 35;
BA_ "GenSigCycleTime" SG_ 2432679743 WRCEngineStopRequest 100;
BA_ "GenSigCycleTimeActive" SG_ 2432679743 WRCEngineStopRequest 100;
BA_ "GenSigStartValue" SG_ 2432679743 WRCEngineStopRequest 3;
BA_ "GenSigMaxLatency" SG_ 2432679743 WRCEngineStopRequest 35;
BA_ "NeedsUpdateBit" SG_ 2432679743 WRCEngineStopRequest 1;
BA_ "GenSigCycleTime" SG_ 2432679743 WrcEngSpdCtrlIncreaseButtStat 100;
BA_ "GenSigCycleTimeActive" SG_ 2432679743 WrcEngSpdCtrlIncreaseButtStat 100;
BA_ "GenSigStartValue" SG_ 2432679743 WrcEngSpdCtrlIncreaseButtStat 3;
BA_ "GenSigMaxLatency" SG_ 2432679743 WrcEngSpdCtrlIncreaseButtStat 35;
BA_ "GenSigCycleTime" SG_ 2365554559 WrcPto1ButtonStatus 100;
BA_ "GenSigCycleTimeActive" SG_ 2365554559 WrcPto1ButtonStatus 100;
BA_ "GenSigStartValue" SG_ 2365554559 WrcPto1ButtonStatus 3;
BA_ "GenSigMaxLatency" SG_ 2365554559 WrcPto1ButtonStatus 15;
BA_ "GenSigCycleTime" SG_ 2365554559 ECSStandByReqWRC 100;
BA_ "GenSigCycleTimeActive" SG_ 2365554559 ECSStandByReqWRC 100;
BA_ "GenSigStartValue" SG_ 2365554559 ECSStandByReqWRC 7;
BA_ "GenSigMaxLatency" SG_ 2365554559 ECSStandByReqWRC 15;
BA_ "GenSigCycleTime" SG_ 2365554559 WRCCraneRequest 100;
BA_ "GenSigCycleTimeActive" SG_ 2365554559 WRCCraneRequest 100;
BA_ "GenSigStartValue" SG_ 2365554559 WRCCraneRequest 3;
BA_ "GenSigMaxLatency" SG_ 2365554559 WRCCraneRequest 15;
BA_ "GenSigCycleTime" SG_ 2365554559 WRCUnlockButtonStatus 100;
BA_ "GenSigCycleTimeActive" SG_ 2365554559 WRCUnlockButtonStatus 100;
BA_ "GenSigStartValue" SG_ 2365554559 WRCUnlockButtonStatus 3;
BA_ "GenSigMaxLatency" SG_ 2365554559 WRCUnlockButtonStatus 15;
BA_ "GenSigCycleTime" SG_ 2365554559 WRCRollRequest 100;
BA_ "GenSigCycleTimeActive" SG_ 2365554559 WRCRollRequest 100;
BA_ "GenSigStartValue" SG_ 2365554559 WRCRollRequest 7;
BA_ "GenSigMaxLatency" SG_ 2365554559 WRCRollRequest 15;
BA_ "GenSigCycleTime" SG_ 2365554559 WRCAux3Request 100;
BA_ "GenSigCycleTimeActive" SG_ 2365554559 WRCAux3Request 100;
BA_ "GenSigStartValue" SG_ 2365554559 WRCAux3Request 3;
BA_ "GenSigMaxLatency" SG_ 2365554559 WRCAux3Request 15;
BA_ "GenSigCycleTime" SG_ 2365554559 WRCAux2Request 100;
BA_ "GenSigCycleTimeActive" SG_ 2365554559 WRCAux2Request 100;
BA_ "GenSigStartValue" SG_ 2365554559 WRCAux2Request 3;
BA_ "GenSigMaxLatency" SG_ 2365554559 WRCAux2Request 15;
BA_ "GenSigCycleTime" SG_ 2365554559 WrcPto3ButtonStatus 100;
BA_ "GenSigCycleTimeActive" SG_ 2365554559 WrcPto3ButtonStatus 100;
BA_ "GenSigStartValue" SG_ 2365554559 WrcPto3ButtonStatus 3;
BA_ "GenSigMaxLatency" SG_ 2365554559 WrcPto3ButtonStatus 15;
BA_ "GenSigCycleTime" SG_ 2365554559 WRCLevelAdjustmentAction 100;
BA_ "GenSigCycleTimeActive" SG_ 2365554559 WRCLevelAdjustmentAction 100;
BA_ "GenSigStartValue" SG_ 2365554559 WRCLevelAdjustmentAction 15;
BA_ "GenSigMaxLatency" SG_ 2365554559 WRCLevelAdjustmentAction 15;
BA_ "GenSigCycleTime" SG_ 2365554559 WRCAux4Request 100;
BA_ "GenSigCycleTimeActive" SG_ 2365554559 WRCAux4Request 100;
BA_ "GenSigStartValue" SG_ 2365554559 WRCAux4Request 3;
BA_ "GenSigMaxLatency" SG_ 2365554559 WRCAux4Request 15;
BA_ "GenSigCycleTime" SG_ 2365554559 WRCAux5Request 100;
BA_ "GenSigCycleTimeActive" SG_ 2365554559 WRCAux5Request 100;
BA_ "GenSigStartValue" SG_ 2365554559 WRCAux5Request 3;
BA_ "GenSigMaxLatency" SG_ 2365554559 WRCAux5Request 15;
BA_ "GenSigCycleTime" SG_ 2365554559 WRCAux6Request 100;
BA_ "GenSigCycleTimeActive" SG_ 2365554559 WRCAux6Request 100;
BA_ "GenSigStartValue" SG_ 2365554559 WRCAux6Request 3;
BA_ "GenSigMaxLatency" SG_ 2365554559 WRCAux6Request 15;
BA_ "GenSigCycleTime" SG_ 2365554559 WRCSideReverseWorkingRequest 100;
BA_ "GenSigCycleTimeActive" SG_ 2365554559 WRCSideReverseWorkingRequest 100;
BA_ "GenSigStartValue" SG_ 2365554559 WRCSideReverseWorkingRequest 3;
BA_ "GenSigMaxLatency" SG_ 2365554559 WRCSideReverseWorkingRequest 15;
BA_ "GenSigCycleTime" SG_ 2365554559 WrcPto2ButtonStatus 100;
BA_ "GenSigCycleTimeActive" SG_ 2365554559 WrcPto2ButtonStatus 100;
BA_ "GenSigStartValue" SG_ 2365554559 WrcPto2ButtonStatus 3;
BA_ "GenSigMaxLatency" SG_ 2365554559 WrcPto2ButtonStatus 15;
BA_ "GenSigCycleTime" SG_ 2365554559 WRCTailLiftRequest 100;
BA_ "GenSigCycleTimeActive" SG_ 2365554559 WRCTailLiftRequest 100;
BA_ "GenSigStartValue" SG_ 2365554559 WRCTailLiftRequest 3;
BA_ "GenSigMaxLatency" SG_ 2365554559 WRCTailLiftRequest 15;
BA_ "GenSigCycleTime" SG_ 2365554559 WrcPto4ButtonStatus 100;
BA_ "GenSigCycleTimeActive" SG_ 2365554559 WrcPto4ButtonStatus 100;
BA_ "GenSigStartValue" SG_ 2365554559 WrcPto4ButtonStatus 3;
BA_ "GenSigMaxLatency" SG_ 2365554559 WrcPto4ButtonStatus 15;
BA_ "GenSigCycleTime" SG_ 2365554559 WRCLevelAdjustmentStroke 100;
BA_ "GenSigCycleTimeActive" SG_ 2365554559 WRCLevelAdjustmentStroke 100;
BA_ "GenSigStartValue" SG_ 2365554559 WRCLevelAdjustmentStroke 7;
BA_ "GenSigMaxLatency" SG_ 2365554559 WRCLevelAdjustmentStroke 15;
BA_ "GenSigCycleTime" SG_ 2365554559 WRCLevelAdjustmentAxles 100;
BA_ "GenSigCycleTimeActive" SG_ 2365554559 WRCLevelAdjustmentAxles 100;
BA_ "GenSigStartValue" SG_ 2365554559 WRCLevelAdjustmentAxles 7;
BA_ "GenSigMaxLatency" SG_ 2365554559 WRCLevelAdjustmentAxles 15;
BA_ "GenSigCycleTime" SG_ 2365554559 WRCAirSuspensionStopRequest 100;
BA_ "GenSigCycleTimeActive" SG_ 2365554559 WRCAirSuspensionStopRequest 100;
BA_ "GenSigStartValue" SG_ 2365554559 WRCAirSuspensionStopRequest 3;
BA_ "GenSigMaxLatency" SG_ 2365554559 WRCAirSuspensionStopRequest 15;
BA_ "GenSigCycleTime" SG_ 2365554559 WRCAux1Request 100;
BA_ "GenSigCycleTimeActive" SG_ 2365554559 WRCAux1Request 100;
BA_ "GenSigStartValue" SG_ 2365554559 WRCAux1Request 3;
BA_ "GenSigMaxLatency" SG_ 2365554559 WRCAux1Request 15;
BA_ "GenSigCycleTime" SG_ 2365554559 WRCLockButtonStatus 100;
BA_ "GenSigCycleTimeActive" SG_ 2365554559 WRCLockButtonStatus 100;
BA_ "GenSigStartValue" SG_ 2365554559 WRCLockButtonStatus 3;
BA_ "GenSigMaxLatency" SG_ 2365554559 WRCLockButtonStatus 15;
BA_ "GenSigSendType" SG_ 2671902706 FuncDiagDataTester 7;
BA_ "Platform_VMCU1_Sig" SG_ 2671902706 FuncDiagDataTester 1;
BA_ "GenSigCycleTime" SG_ 2516576083 TrafficAccidentStat_Status 100;
BA_ "GenSigCycleTimeActive" SG_ 2516576083 TrafficAccidentStat_Status 100;
BA_ "GenSigCycleTime" SG_ 2516576083 TrafficAccidentStat_CRC 100;
BA_ "GenSigCycleTimeActive" SG_ 2516576083 TrafficAccidentStat_CRC 100;
BA_ "E2EDataId" SG_ 2516576083 TrafficAccidentStat_CRC 565;
BA_ "E2EDataLength" SG_ 2516576083 TrafficAccidentStat_CRC 16;
BA_ "E2EProfile" SG_ 2516576083 TrafficAccidentStat_CRC "P01";
BA_ "GenSigCycleTime" SG_ 2516576083 TrafficAccidentStat_SqC 100;
BA_ "GenSigCycleTimeActive" SG_ 2516576083 TrafficAccidentStat_SqC 100;
BA_ "GenSigCycleTime" SG_ 2432689747 SideColliAccidentStat_RightSide 100;
BA_ "GenSigCycleTimeActive" SG_ 2432689747 SideColliAccidentStat_RightSide 100;
BA_ "GenSigStartValue" SG_ 2432689747 SideColliAccidentStat_RightSide 7;
BA_ "GenSigCycleTime" SG_ 2432689747 SideColliAccidentStat_LeftSide 100;
BA_ "GenSigCycleTimeActive" SG_ 2432689747 SideColliAccidentStat_LeftSide 100;
BA_ "GenSigStartValue" SG_ 2432689747 SideColliAccidentStat_LeftSide 7;
BA_ "GenSigCycleTime" SG_ 2432689747 SideColliAccidentStat_CRC 100;
BA_ "GenSigCycleTimeActive" SG_ 2432689747 SideColliAccidentStat_CRC 100;
BA_ "GenSigStartValue" SG_ 2432689747 SideColliAccidentStat_CRC 255;
BA_ "E2EDataId" SG_ 2432689747 SideColliAccidentStat_CRC 426;
BA_ "E2EDataLength" SG_ 2432689747 SideColliAccidentStat_CRC 24;
BA_ "E2EProfile" SG_ 2432689747 SideColliAccidentStat_CRC "P01";
BA_ "GenSigCycleTime" SG_ 2432689747 SideColliAccidentStat_SqC 100;
BA_ "GenSigCycleTimeActive" SG_ 2432689747 SideColliAccidentStat_SqC 100;
BA_ "GenSigStartValue" SG_ 2432689747 SideColliAccidentStat_SqC 14;
BA_ "GenSigCycleTime" SG_ 2499788607 TrafficAccShutDownReq_CRC 100;
BA_ "GenSigCycleTimeActive" SG_ 2499788607 TrafficAccShutDownReq_CRC 100;
BA_ "E2EDataId" SG_ 2499788607 TrafficAccShutDownReq_CRC 10;
BA_ "GenSigCycleTime" SG_ 2499788607 TrafficAccIntlightReq 100;
BA_ "GenSigCycleTimeActive" SG_ 2499788607 TrafficAccIntlightReq 100;
BA_ "GenSigStartValue" SG_ 2499788607 TrafficAccIntlightReq 3;
BA_ "GenSigCycleTime" SG_ 2499788607 TrafficAccShutDownReq_Rqst 100;
BA_ "GenSigCycleTimeActive" SG_ 2499788607 TrafficAccShutDownReq_Rqst 100;
BA_ "GenSigStartValue" SG_ 2499788607 TrafficAccShutDownReq_Rqst 3;
BA_ "GenSigCycleTime" SG_ 2499788607 ECUVIN_rqst 100;
BA_ "GenSigCycleTimeActive" SG_ 2499788607 ECUVIN_rqst 100;
BA_ "GenSigMaxLatency" SG_ 2499788607 ECUVIN_rqst 60;
BA_ "GenSigCycleTime" SG_ 2499788607 TrafficAccShutDownReq_SqC 100;
BA_ "GenSigCycleTimeActive" SG_ 2499788607 TrafficAccShutDownReq_SqC 100;
BA_ "GenSigCycleTime" SG_ 2432689491 SRSWarningLamp 100;
BA_ "GenSigCycleTimeActive" SG_ 2432689491 SRSWarningLamp 100;
BA_ "GenSigStartValue" SG_ 2432689491 SRSWarningLamp 3;
BA_ "GenSigCycleTime" SG_ 2432689491 RollOverAccidentStatus 100;
BA_ "GenSigCycleTimeActive" SG_ 2432689491 RollOverAccidentStatus 100;
BA_ "GenSigStartValue" SG_ 2432689491 RollOverAccidentStatus 3;
BA_ "GenSigCycleTime" SG_ 2432689491 SRSAirbagStatus 100;
BA_ "GenSigCycleTimeActive" SG_ 2432689491 SRSAirbagStatus 100;
BA_ "GenSigStartValue" SG_ 2432689491 SRSAirbagStatus 3;
BA_ "GenSigMaxLatency" SG_ 2432689491 SRSAirbagStatus 26;
BA_ "SeToolAncestorID_SIGNAL" SG_ 2432689491 SRSAirbagStatus "x0000001D04147207";
BA_ "SeToolItemID_SIGNAL" SG_ 2432689491 SRSAirbagStatus "x0000001D042F372C";
BA_ "SeToolName_SIGNAL" SG_ 2432689491 SRSAirbagStatus "SRSAirbagStatus";
BA_ "SeToolVersion_SIGNAL" SG_ 2432689491 SRSAirbagStatus "2";
BA_ "GenSigCycleTime" SG_ 2432689491 EmergencyDoorsUnlock_rqst_CRC 100;
BA_ "GenSigCycleTimeActive" SG_ 2432689491 EmergencyDoorsUnlock_rqst_CRC 100;
BA_ "GenSigStartValue" SG_ 2432689491 EmergencyDoorsUnlock_rqst_CRC 255;
BA_ "E2EDataId" SG_ 2432689491 EmergencyDoorsUnlock_rqst_CRC 2;
BA_ "GenSigCycleTime" SG_ 2432689491 EmergencyDoorsUnlock_rqst 100;
BA_ "GenSigCycleTimeActive" SG_ 2432689491 EmergencyDoorsUnlock_rqst 100;
BA_ "GenSigStartValue" SG_ 2432689491 EmergencyDoorsUnlock_rqst 7;
BA_ "GenSigMaxLatency" SG_ 2432689491 EmergencyDoorsUnlock_rqst 26;
BA_ "GenSigCycleTime" SG_ 2432689491 TrafficAccidentHzdActvRqst_CRC 100;
BA_ "GenSigCycleTimeActive" SG_ 2432689491 TrafficAccidentHzdActvRqst_CRC 100;
BA_ "GenSigStartValue" SG_ 2432689491 TrafficAccidentHzdActvRqst_CRC 255;
BA_ "E2EDataId" SG_ 2432689491 TrafficAccidentHzdActvRqst_CRC 1;
BA_ "GenSigCycleTime" SG_ 2432689491 SRSWarningLamp_SqC 100;
BA_ "GenSigCycleTimeActive" SG_ 2432689491 SRSWarningLamp_SqC 100;
BA_ "GenSigStartValue" SG_ 2432689491 SRSWarningLamp_SqC 15;
BA_ "GenSigCycleTime" SG_ 2432689491 SRSWarningLamp_CRC 100;
BA_ "GenSigCycleTimeActive" SG_ 2432689491 SRSWarningLamp_CRC 100;
BA_ "GenSigStartValue" SG_ 2432689491 SRSWarningLamp_CRC 255;
BA_ "E2EDataId" SG_ 2432689491 SRSWarningLamp_CRC 3;
BA_ "GenSigCycleTime" SG_ 2432689491 TrafficAccidentHazardLightRqst 100;
BA_ "GenSigCycleTimeActive" SG_ 2432689491 TrafficAccidentHazardLightRqst 100;
BA_ "GenSigStartValue" SG_ 2432689491 TrafficAccidentHazardLightRqst 3;
BA_ "GenSigCycleTime" SG_ 2432689491 EmergencyDoorsUnlock_rqst_SqC 100;
BA_ "GenSigCycleTimeActive" SG_ 2432689491 EmergencyDoorsUnlock_rqst_SqC 100;
BA_ "GenSigStartValue" SG_ 2432689491 EmergencyDoorsUnlock_rqst_SqC 15;
BA_ "GenSigCycleTime" SG_ 2432689491 TrafficAccidentHzdActvRqst_SqC 100;
BA_ "GenSigCycleTimeActive" SG_ 2432689491 TrafficAccidentHzdActvRqst_SqC 100;
BA_ "GenSigStartValue" SG_ 2432689491 TrafficAccidentHzdActvRqst_SqC 15;
BA_ "GenSigCycleTime" SG_ 2432689491 FrontalCollisionAccidentStatus 100;
BA_ "GenSigCycleTimeActive" SG_ 2432689491 FrontalCollisionAccidentStatus 100;
BA_ "GenSigStartValue" SG_ 2432689491 FrontalCollisionAccidentStatus 3;
BA_ "GenSigSendType" SG_ 2658975757 SRSDiagPSTesterTx4 7;
BA_ "GenSigSendType" SG_ 2658975756 SRSDiagPSTesterTx3 7;
BA_ "GenSigSendType" SG_ 2658975755 SRSDiagPSTesterTx2 7;
BA_ "GenSigSendType" SG_ 2658967560 SRSDiagPSTesterTx1 7;
BA_ "GenSigSendType" SG_ 2658967559 SRSDiagPSTesterRx1 7;
BA_ "GenSigSendType" SG_ 2671833762 PhysDiagRespSig_F2_A2 7;
BA_ "GenSigSendType" SG_ 2671833752 PhysDiagRespSig_F2_98 7;
BA_ "GenSigSendType" SG_ 2671833747 PhysDiagRespSig_F2_93 7;
BA_ "Platform_VMCU1_Sig" SG_ 2671833747 PhysDiagRespSig_F2_93 1;
BA_ "GenSigSendType" SG_ 2671833683 PhysDiagRespSig_F2_53 7;
BA_ "GenSigSendType" SG_ 2671833638 PhysDiagRespSig_F2_26 7;
BA_ "GenSigSendType" SG_ 2564485459 PhysDiagRespSig_F1_53 7;
BA_ "GenSigSendType" SG_ 2671813362 PhysDiagReqSig_A2_F2 7;
BA_ "GenSigSendType" SG_ 2671810802 PhysDiagReqSig_98_F2 7;
BA_ "GenSigSendType" SG_ 2671809522 PhysDiagReqSig_93_F2 7;
BA_ "Platform_VMCU1_Sig" SG_ 2671809522 PhysDiagReqSig_93_F2 1;
BA_ "GenSigSendType" SG_ 2671793138 PhysDiagReqSig_53_F2 7;
BA_ "GenSigSendType" SG_ 2564445169 PhysDiagReqSig_53_F1 7;
BA_ "GenSigSendType" SG_ 2671781618 PhysDiagReqSig_26_F2 7;
BA_ "GenSigSendType" SG_ 2549208482 LECM_Ent_UpDown_WheelStatus 3;
BA_ "GenSigStartValue" SG_ 2549208482 LECM_Ent_UpDown_WheelStatus 15;
BA_ "GenSigMaxLatency" SG_ 2549208482 LECM_Ent_UpDown_WheelStatus 235;
BA_ "GenSigSendType" SG_ 2549208482 LECM_IntLight_SlprMaxLight_BS 3;
BA_ "GenSigStartValue" SG_ 2549208482 LECM_IntLight_SlprMaxLight_BS 3;
BA_ "GenSigMaxLatency" SG_ 2549208482 LECM_IntLight_SlprMaxLight_BS 235;
BA_ "GenSigSendType" SG_ 2549208482 LECM_CabClim_Pwr_BtnStat 3;
BA_ "GenSigStartValue" SG_ 2549208482 LECM_CabClim_Pwr_BtnStat 3;
BA_ "GenSigMaxLatency" SG_ 2549208482 LECM_CabClim_Pwr_BtnStat 235;
BA_ "GenSigSendType" SG_ 2549208482 LECM_LockControl_Lock_BtnStat 3;
BA_ "GenSigStartValue" SG_ 2549208482 LECM_LockControl_Lock_BtnStat 3;
BA_ "GenSigMaxLatency" SG_ 2549208482 LECM_LockControl_Lock_BtnStat 235;
BA_ "GenSigSendType" SG_ 2549208482 LECM_CabClim_Auto_BtnStat 3;
BA_ "GenSigStartValue" SG_ 2549208482 LECM_CabClim_Auto_BtnStat 3;
BA_ "GenSigMaxLatency" SG_ 2549208482 LECM_CabClim_Auto_BtnStat 235;
BA_ "GenSigSendType" SG_ 2549208482 LECM_CabClim_AC_BtnStat 3;
BA_ "GenSigStartValue" SG_ 2549208482 LECM_CabClim_AC_BtnStat 3;
BA_ "GenSigMaxLatency" SG_ 2549208482 LECM_CabClim_AC_BtnStat 235;
BA_ "GenSigSendType" SG_ 2549208482 LECM_CabClim_FrPwr_BtnStat 3;
BA_ "GenSigStartValue" SG_ 2549208482 LECM_CabClim_FrPwr_BtnStat 3;
BA_ "GenSigMaxLatency" SG_ 2549208482 LECM_CabClim_FrPwr_BtnStat 235;
BA_ "GenSigSendType" SG_ 2549208482 LECM_Ent_Volume_WheelStatus 3;
BA_ "GenSigStartValue" SG_ 2549208482 LECM_Ent_Volume_WheelStatus 15;
BA_ "GenSigMaxLatency" SG_ 2549208482 LECM_Ent_Volume_WheelStatus 235;
BA_ "GenSigSendType" SG_ 2549208482 LECMCabClimSetTempSelectGuiReq 3;
BA_ "GenSigStartValue" SG_ 2549208482 LECMCabClimSetTempSelectGuiReq 3;
BA_ "GenSigSendType" SG_ 2549208482 LECM_IntLight_SlprAmbLow_BS 3;
BA_ "GenSigStartValue" SG_ 2549208482 LECM_IntLight_SlprAmbLow_BS 3;
BA_ "GenSigMaxLatency" SG_ 2549208482 LECM_IntLight_SlprAmbLow_BS 235;
BA_ "GenSigSendType" SG_ 2549208482 LECM_CabClim_MaxDef_GuiReq 3;
BA_ "GenSigStartValue" SG_ 2549208482 LECM_CabClim_MaxDef_GuiReq 3;
BA_ "GenSigSendType" SG_ 2549208482 LECM_CabClim_Fan_WheelStatus 3;
BA_ "GenSigStartValue" SG_ 2549208482 LECM_CabClim_Fan_WheelStatus 15;
BA_ "GenSigMaxLatency" SG_ 2549208482 LECM_CabClim_Fan_WheelStatus 235;
BA_ "GenSigSendType" SG_ 2549208482 LECM_IntLight_SlprAmbUpp_BS 3;
BA_ "GenSigStartValue" SG_ 2549208482 LECM_IntLight_SlprAmbUpp_BS 3;
BA_ "GenSigMaxLatency" SG_ 2549208482 LECM_IntLight_SlprAmbUpp_BS 235;
BA_ "GenSigSendType" SG_ 2549208482 LECM_Ent_AudioSettingsViewSts 3;
BA_ "GenSigStartValue" SG_ 2549208482 LECM_Ent_AudioSettingsViewSts 15;
BA_ "GenSigCycleTime" SG_ 2549208482 LECM_Panic_CMS_BtnStat 100;
BA_ "GenSigCycleTimeActive" SG_ 2549208482 LECM_Panic_CMS_BtnStat 100;
BA_ "GenSigStartValue" SG_ 2549208482 LECM_Panic_CMS_BtnStat 3;
BA_ "GenSigSendType" SG_ 2549208482 LECM_CabClim_Sync_GuiReq 3;
BA_ "GenSigStartValue" SG_ 2549208482 LECM_CabClim_Sync_GuiReq 3;
BA_ "GenSigMaxLatency" SG_ 2549208482 LECM_CabClim_Sync_GuiReq 235;
BA_ "GenSigSendType" SG_ 2549208482 LecmCutOffAnswerGuiRqst 3;
BA_ "GenSigStartValue" SG_ 2549208482 LecmCutOffAnswerGuiRqst 3;
BA_ "GenSigSendType" SG_ 2549208482 LECM_Ent_MediaSource_BtnStat 3;
BA_ "GenSigStartValue" SG_ 2549208482 LECM_Ent_MediaSource_BtnStat 3;
BA_ "GenSigMaxLatency" SG_ 2549208482 LECM_Ent_MediaSource_BtnStat 235;
BA_ "GenSigSendType" SG_ 2549208482 LECM_CabClim_Temp_WheelStatus 3;
BA_ "GenSigStartValue" SG_ 2549208482 LECM_CabClim_Temp_WheelStatus 15;
BA_ "GenSigMaxLatency" SG_ 2549208482 LECM_CabClim_Temp_WheelStatus 235;
BA_ "GenSigSendType" SG_ 2549208482 LECM_Power_Inverter_BtnStat 3;
BA_ "GenSigStartValue" SG_ 2549208482 LECM_Power_Inverter_BtnStat 3;
BA_ "GenSigMaxLatency" SG_ 2549208482 LECM_Power_Inverter_BtnStat 235;
BA_ "GenSigSendType" SG_ 2549208482 LECM_Ent_SkpLeft_BtnStat 3;
BA_ "GenSigStartValue" SG_ 2549208482 LECM_Ent_SkpLeft_BtnStat 3;
BA_ "GenSigMaxLatency" SG_ 2549208482 LECM_Ent_SkpLeft_BtnStat 235;
BA_ "GenSigSendType" SG_ 2549208482 LECM_IntLight_SlprDecrease_BS 3;
BA_ "GenSigStartValue" SG_ 2549208482 LECM_IntLight_SlprDecrease_BS 3;
BA_ "GenSigMaxLatency" SG_ 2549208482 LECM_IntLight_SlprDecrease_BS 235;
BA_ "GenSigSendType" SG_ 2549208482 LECM_Ent_OnOff_BtnStat 3;
BA_ "GenSigStartValue" SG_ 2549208482 LECM_Ent_OnOff_BtnStat 3;
BA_ "GenSigMaxLatency" SG_ 2549208482 LECM_Ent_OnOff_BtnStat 235;
BA_ "GenSigSendType" SG_ 2549208482 LECM_IntLight_SlprIncrease_BS 3;
BA_ "GenSigStartValue" SG_ 2549208482 LECM_IntLight_SlprIncrease_BS 3;
BA_ "GenSigMaxLatency" SG_ 2549208482 LECM_IntLight_SlprIncrease_BS 235;
BA_ "GenSigSendType" SG_ 2549208482 LECM_Ent_SkpRight_BtnStat 3;
BA_ "GenSigStartValue" SG_ 2549208482 LECM_Ent_SkpRight_BtnStat 3;
BA_ "GenSigMaxLatency" SG_ 2549208482 LECM_Ent_SkpRight_BtnStat 235;
BA_ "GenSigSendType" SG_ 2566337698 LECM_Display_Navi_OK_BtnStat 3;
BA_ "GenSigStartValue" SG_ 2566337698 LECM_Display_Navi_OK_BtnStat 3;
BA_ "GenSigSendType" SG_ 2566337698 LECM_AlClkSnze_GRqst_ID 3;
BA_ "GenSigStartValue" SG_ 2566337698 LECM_AlClkSnze_GRqst_ID 127;
BA_ "GenSigMaxLatency" SG_ 2566337698 LECM_AlClkSnze_GRqst_ID 1030;
BA_ "GenSigSendType" SG_ 2566337698 LECM_AlClkSetAl_GRqst_Mode 3;
BA_ "GenSigStartValue" SG_ 2566337698 LECM_AlClkSetAl_GRqst_Mode 3;
BA_ "GenSigMaxLatency" SG_ 2566337698 LECM_AlClkSetAl_GRqst_Mode 1030;
BA_ "GenSigSendType" SG_ 2566337698 LECM_AlClkSetAl_GRqst_Stat 3;
BA_ "GenSigStartValue" SG_ 2566337698 LECM_AlClkSetAl_GRqst_Stat 3;
BA_ "GenSigMaxLatency" SG_ 2566337698 LECM_AlClkSetAl_GRqst_Stat 1030;
BA_ "GenSigSendType" SG_ 2566337698 LECM_AlClkSetAl_GRqst_SetHr 3;
BA_ "GenSigStartValue" SG_ 2566337698 LECM_AlClkSetAl_GRqst_SetHr 31;
BA_ "GenSigMaxLatency" SG_ 2566337698 LECM_AlClkSetAl_GRqst_SetHr 1030;
BA_ "GenSigSendType" SG_ 2566337698 LECM_AlClkSetAl_GRqst_ID 3;
BA_ "GenSigStartValue" SG_ 2566337698 LECM_AlClkSetAl_GRqst_ID 127;
BA_ "GenSigMaxLatency" SG_ 2566337698 LECM_AlClkSetAl_GRqst_ID 1030;
BA_ "GenSigSendType" SG_ 2566337698 LECM_Display_Navi_WheelStatus 3;
BA_ "GenSigStartValue" SG_ 2566337698 LECM_Display_Navi_WheelStatus 15;
BA_ "GenSigSendType" SG_ 2566337698 LECM_AlClkSetAl_GRqst_DaySet 3;
BA_ "GenSigStartValue" SG_ 2566337698 LECM_AlClkSetAl_GRqst_DaySet 255;
BA_ "GenSigMaxLatency" SG_ 2566337698 LECM_AlClkSetAl_GRqst_DaySet 1030;
BA_ "GenSigSendType" SG_ 2566337698 LECM_AlClkSetAl_GRqst_Type 3;
BA_ "GenSigStartValue" SG_ 2566337698 LECM_AlClkSetAl_GRqst_Type 7;
BA_ "GenSigMaxLatency" SG_ 2566337698 LECM_AlClkSetAl_GRqst_Type 1030;
BA_ "GenSigSendType" SG_ 2566337698 LECM_AlClkSetAl_GRqst_SetMin 3;
BA_ "GenSigStartValue" SG_ 2566337698 LECM_AlClkSetAl_GRqst_SetMin 63;
BA_ "GenSigMaxLatency" SG_ 2566337698 LECM_AlClkSetAl_GRqst_SetMin 1030;
BA_ "GenSigSendType" SG_ 2566337698 LECM_AlClkSnze_GRqst_Action 3;
BA_ "GenSigStartValue" SG_ 2566337698 LECM_AlClkSnze_GRqst_Action 7;
BA_ "GenSigMaxLatency" SG_ 2566337698 LECM_AlClkSnze_GRqst_Action 1030;
BA_ "GenSigSendType" SG_ 2499772322 MediaSourcesListReq_sg_UB 7;
BA_ "GenSigSendType" SG_ 2499772322 MediaSourcesListReq_SInfo 1;
BA_ "GenSigStartValue" SG_ 2499772322 MediaSourcesListReq_SInfo 3;
BA_ "GenSigMaxLatency" SG_ 2499772322 MediaSourcesListReq_SInfo 100;
BA_ "NeedsUpdateBit" SG_ 2499772322 MediaSourcesListReq_SInfo 1;
BA_ "GenSigSendType" SG_ 2499772322 MediaSourcesListReq_Items 1;
BA_ "GenSigMaxLatency" SG_ 2499772322 MediaSourcesListReq_Items 100;
BA_ "NeedsUpdateBit" SG_ 2499772322 MediaSourcesListReq_Items 1;
BA_ "GenSigSendType" SG_ 2499772322 MediaSourcesListReq_ItemID 1;
BA_ "GenSigMaxLatency" SG_ 2499772322 MediaSourcesListReq_ItemID 100;
BA_ "NeedsUpdateBit" SG_ 2499772322 MediaSourcesListReq_ItemID 1;
BA_ "GenSigCycleTime" SG_ 2489730210 BunkH1AudioSrcSem_rqst 100;
BA_ "GenSigCycleTimeActive" SG_ 2489730210 BunkH1AudioSrcSem_rqst 100;
BA_ "GenSigStartValue" SG_ 2489730210 BunkH1AudioSrcSem_rqst 15;
BA_ "GenSigCycleTime" SG_ 2489730210 CMSOnOffRqst 100;
BA_ "GenSigCycleTimeActive" SG_ 2489730210 CMSOnOffRqst 100;
BA_ "GenSigStartValue" SG_ 2489730210 CMSOnOffRqst 3;
BA_ "GenSigSendType" SG_ 2566043647 AlmClkSetAlm_LECM_rq_Type 1;
BA_ "GenSigCycleTime" SG_ 2566043647 AlmClkSetAlm_LECM_rq_Type 100;
BA_ "GenSigCycleTimeActive" SG_ 2566043647 AlmClkSetAlm_LECM_rq_Type 100;
BA_ "GenSigStartValue" SG_ 2566043647 AlmClkSetAlm_LECM_rq_Type 7;
BA_ "GenSigMaxLatency" SG_ 2566043647 AlmClkSetAlm_LECM_rq_Type 220;
BA_ "GenSigSendType" SG_ 2566043647 AlmClkSetAlm_LECM_rq_SetHr 1;
BA_ "GenSigCycleTime" SG_ 2566043647 AlmClkSetAlm_LECM_rq_SetHr 100;
BA_ "GenSigCycleTimeActive" SG_ 2566043647 AlmClkSetAlm_LECM_rq_SetHr 100;
BA_ "GenSigStartValue" SG_ 2566043647 AlmClkSetAlm_LECM_rq_SetHr 31;
BA_ "GenSigMaxLatency" SG_ 2566043647 AlmClkSetAlm_LECM_rq_SetHr 220;
BA_ "GenSigSendType" SG_ 2566043647 AlmClkSnze_LECM_rqst_ID 1;
BA_ "GenSigCycleTime" SG_ 2566043647 AlmClkSnze_LECM_rqst_ID 100;
BA_ "GenSigCycleTimeActive" SG_ 2566043647 AlmClkSnze_LECM_rqst_ID 100;
BA_ "GenSigStartValue" SG_ 2566043647 AlmClkSnze_LECM_rqst_ID 127;
BA_ "GenSigSendType" SG_ 2566043647 AlmClkSetAlm_LECM_rq_DaySet 1;
BA_ "GenSigCycleTime" SG_ 2566043647 AlmClkSetAlm_LECM_rq_DaySet 100;
BA_ "GenSigCycleTimeActive" SG_ 2566043647 AlmClkSetAlm_LECM_rq_DaySet 100;
BA_ "GenSigMaxLatency" SG_ 2566043647 AlmClkSetAlm_LECM_rq_DaySet 220;
BA_ "GenSigSendType" SG_ 2566043647 AlmClkSetAlm_LECM_rq_Mode 1;
BA_ "GenSigCycleTime" SG_ 2566043647 AlmClkSetAlm_LECM_rq_Mode 100;
BA_ "GenSigCycleTimeActive" SG_ 2566043647 AlmClkSetAlm_LECM_rq_Mode 100;
BA_ "GenSigMaxLatency" SG_ 2566043647 AlmClkSetAlm_LECM_rq_Mode 220;
BA_ "GenSigSendType" SG_ 2566043647 AlmClkSetAlm_LECM_rq_Stat 1;
BA_ "GenSigCycleTime" SG_ 2566043647 AlmClkSetAlm_LECM_rq_Stat 100;
BA_ "GenSigCycleTimeActive" SG_ 2566043647 AlmClkSetAlm_LECM_rq_Stat 100;
BA_ "GenSigMaxLatency" SG_ 2566043647 AlmClkSetAlm_LECM_rq_Stat 220;
BA_ "GenSigSendType" SG_ 2566043647 AlmClkSetAlm_LECM_rq_SetMin 1;
BA_ "GenSigCycleTime" SG_ 2566043647 AlmClkSetAlm_LECM_rq_SetMin 100;
BA_ "GenSigCycleTimeActive" SG_ 2566043647 AlmClkSetAlm_LECM_rq_SetMin 100;
BA_ "GenSigStartValue" SG_ 2566043647 AlmClkSetAlm_LECM_rq_SetMin 63;
BA_ "GenSigMaxLatency" SG_ 2566043647 AlmClkSetAlm_LECM_rq_SetMin 220;
BA_ "GenSigSendType" SG_ 2566043647 AlmClkSetAlm_LECM_rq_ID 1;
BA_ "GenSigCycleTime" SG_ 2566043647 AlmClkSetAlm_LECM_rq_ID 100;
BA_ "GenSigCycleTimeActive" SG_ 2566043647 AlmClkSetAlm_LECM_rq_ID 100;
BA_ "GenSigStartValue" SG_ 2566043647 AlmClkSetAlm_LECM_rq_ID 127;
BA_ "GenSigMaxLatency" SG_ 2566043647 AlmClkSetAlm_LECM_rq_ID 220;
BA_ "GenSigSendType" SG_ 2566043647 AlmClkSnze_LECM_rqst_Action 1;
BA_ "GenSigCycleTime" SG_ 2566043647 AlmClkSnze_LECM_rqst_Action 100;
BA_ "GenSigCycleTimeActive" SG_ 2566043647 AlmClkSnze_LECM_rqst_Action 100;
BA_ "GenSigStartValue" SG_ 2566043647 AlmClkSnze_LECM_rqst_Action 7;
BA_ "GenSigCycleTime" SG_ 2432693154 BunkH1Prev_ButtonStatus 100;
BA_ "GenSigCycleTimeActive" SG_ 2432693154 BunkH1Prev_ButtonStatus 100;
BA_ "GenSigStartValue" SG_ 2432693154 BunkH1Prev_ButtonStatus 3;
BA_ "GenSigSendType" SG_ 2432693154 BunkH1PowerWinOpenDSBtn_stat_UB 7;
BA_ "GenSigCycleTime" SG_ 2432693154 BunkH1RoofhatchOpenBtn_Stat 100;
BA_ "GenSigCycleTimeActive" SG_ 2432693154 BunkH1RoofhatchOpenBtn_Stat 100;
BA_ "GenSigStartValue" SG_ 2432693154 BunkH1RoofhatchOpenBtn_Stat 3;
BA_ "GenSigMaxLatency" SG_ 2432693154 BunkH1RoofhatchOpenBtn_Stat 26;
BA_ "GenSigCycleTime" SG_ 2432693154 BunkH1IntLghtActvnBtn_stat 100;
BA_ "GenSigCycleTimeActive" SG_ 2432693154 BunkH1IntLghtActvnBtn_stat 100;
BA_ "GenSigStartValue" SG_ 2432693154 BunkH1IntLghtActvnBtn_stat 3;
BA_ "GenSigCycleTime" SG_ 2432693154 BunkH1AudioSource_rqst 100;
BA_ "GenSigCycleTimeActive" SG_ 2432693154 BunkH1AudioSource_rqst 100;
BA_ "GenSigStartValue" SG_ 2432693154 BunkH1AudioSource_rqst 7;
BA_ "GenSigCycleTime" SG_ 2432693154 BunkH1TempDec_ButtonStatus 100;
BA_ "GenSigCycleTimeActive" SG_ 2432693154 BunkH1TempDec_ButtonStatus 100;
BA_ "GenSigStartValue" SG_ 2432693154 BunkH1TempDec_ButtonStatus 3;
BA_ "GenSigMaxLatency" SG_ 2432693154 BunkH1TempDec_ButtonStatus 26;
BA_ "GenSigCycleTime" SG_ 2432693154 BunkH1IntLghtDirAccsUpBtn_stat 100;
BA_ "GenSigCycleTimeActive" SG_ 2432693154 BunkH1IntLghtDirAccsUpBtn_stat 100;
BA_ "GenSigStartValue" SG_ 2432693154 BunkH1IntLghtDirAccsUpBtn_stat 3;
BA_ "GenSigCycleTime" SG_ 2432693154 BunkH1RoofhatchCloseBtn_Stat 100;
BA_ "GenSigCycleTimeActive" SG_ 2432693154 BunkH1RoofhatchCloseBtn_Stat 100;
BA_ "GenSigStartValue" SG_ 2432693154 BunkH1RoofhatchCloseBtn_Stat 3;
BA_ "GenSigMaxLatency" SG_ 2432693154 BunkH1RoofhatchCloseBtn_Stat 26;
BA_ "GenSigSendType" SG_ 2432693154 BunkH1PowerWinClosePSBtn_stat_UB 7;
BA_ "GenSigCycleTime" SG_ 2432693154 BunkH1VolumeDown_ButtonStatus 100;
BA_ "GenSigCycleTimeActive" SG_ 2432693154 BunkH1VolumeDown_ButtonStatus 100;
BA_ "GenSigStartValue" SG_ 2432693154 BunkH1VolumeDown_ButtonStatus 3;
BA_ "GenSigCycleTime" SG_ 2432693154 BunkH1PowerWinCloseDSBtn_stat 100;
BA_ "GenSigCycleTimeActive" SG_ 2432693154 BunkH1PowerWinCloseDSBtn_stat 100;
BA_ "GenSigStartValue" SG_ 2432693154 BunkH1PowerWinCloseDSBtn_stat 3;
BA_ "GenSigMaxLatency" SG_ 2432693154 BunkH1PowerWinCloseDSBtn_stat 26;
BA_ "NeedsUpdateBit" SG_ 2432693154 BunkH1PowerWinCloseDSBtn_stat 1;
BA_ "GenSigCycleTime" SG_ 2432693154 BunkH1Next_ButtonStatus 100;
BA_ "GenSigCycleTimeActive" SG_ 2432693154 BunkH1Next_ButtonStatus 100;
BA_ "GenSigStartValue" SG_ 2432693154 BunkH1Next_ButtonStatus 3;
BA_ "GenSigCycleTime" SG_ 2432693154 BunkH1UnlockButtonStatus 100;
BA_ "GenSigCycleTimeActive" SG_ 2432693154 BunkH1UnlockButtonStatus 100;
BA_ "GenSigStartValue" SG_ 2432693154 BunkH1UnlockButtonStatus 3;
BA_ "GenSigMaxLatency" SG_ 2432693154 BunkH1UnlockButtonStatus 26;
BA_ "GenSigCycleTime" SG_ 2432693154 BunkH1ParkHeaterTimer2_cmd 100;
BA_ "GenSigCycleTimeActive" SG_ 2432693154 BunkH1ParkHeaterTimer2_cmd 100;
BA_ "GenSigStartValue" SG_ 2432693154 BunkH1ParkHeaterTimer2_cmd 7;
BA_ "GenSigMaxLatency" SG_ 2432693154 BunkH1ParkHeaterTimer2_cmd 26;
BA_ "GenSigCycleTime" SG_ 2432693154 BunkH1AudioOnOff_ButtonStatus 100;
BA_ "GenSigCycleTimeActive" SG_ 2432693154 BunkH1AudioOnOff_ButtonStatus 100;
BA_ "GenSigStartValue" SG_ 2432693154 BunkH1AudioOnOff_ButtonStatus 3;
BA_ "GenSigSendType" SG_ 2432693154 BunkH1PowerWinOpenPSBtn_stat_UB 7;
BA_ "GenSigCycleTime" SG_ 2432693154 BunkH1PowerWinOpenDSBtn_stat 100;
BA_ "GenSigCycleTimeActive" SG_ 2432693154 BunkH1PowerWinOpenDSBtn_stat 100;
BA_ "GenSigStartValue" SG_ 2432693154 BunkH1PowerWinOpenDSBtn_stat 3;
BA_ "GenSigMaxLatency" SG_ 2432693154 BunkH1PowerWinOpenDSBtn_stat 26;
BA_ "NeedsUpdateBit" SG_ 2432693154 BunkH1PowerWinOpenDSBtn_stat 1;
BA_ "GenSigCycleTime" SG_ 2432693154 BunkH1ParkHeater_ButtonStatus 100;
BA_ "GenSigCycleTimeActive" SG_ 2432693154 BunkH1ParkHeater_ButtonStatus 100;
BA_ "GenSigStartValue" SG_ 2432693154 BunkH1ParkHeater_ButtonStatus 3;
BA_ "GenSigMaxLatency" SG_ 2432693154 BunkH1ParkHeater_ButtonStatus 26;
BA_ "GenSigCycleTime" SG_ 2432693154 BunkH1VolumeUp_ButtonStatus 100;
BA_ "GenSigCycleTimeActive" SG_ 2432693154 BunkH1VolumeUp_ButtonStatus 100;
BA_ "GenSigStartValue" SG_ 2432693154 BunkH1VolumeUp_ButtonStatus 3;
BA_ "GenSigCycleTime" SG_ 2432693154 BunkH1ParkHeaterTimer3_cmd 100;
BA_ "GenSigCycleTimeActive" SG_ 2432693154 BunkH1ParkHeaterTimer3_cmd 100;
BA_ "GenSigStartValue" SG_ 2432693154 BunkH1ParkHeaterTimer3_cmd 7;
BA_ "GenSigMaxLatency" SG_ 2432693154 BunkH1ParkHeaterTimer3_cmd 26;
BA_ "GenSigCycleTime" SG_ 2432693154 BunkH1Mute_ButtonStatus 100;
BA_ "GenSigCycleTimeActive" SG_ 2432693154 BunkH1Mute_ButtonStatus 100;
BA_ "GenSigStartValue" SG_ 2432693154 BunkH1Mute_ButtonStatus 3;
BA_ "GenSigCycleTime" SG_ 2432693154 BunkH1IntLghtDirAccsDnBtn_stat 100;
BA_ "GenSigCycleTimeActive" SG_ 2432693154 BunkH1IntLghtDirAccsDnBtn_stat 100;
BA_ "GenSigStartValue" SG_ 2432693154 BunkH1IntLghtDirAccsDnBtn_stat 3;
BA_ "GenSigCycleTime" SG_ 2432693154 BunkH1LockButtonStatus 100;
BA_ "GenSigCycleTimeActive" SG_ 2432693154 BunkH1LockButtonStatus 100;
BA_ "GenSigStartValue" SG_ 2432693154 BunkH1LockButtonStatus 3;
BA_ "GenSigMaxLatency" SG_ 2432693154 BunkH1LockButtonStatus 26;
BA_ "GenSigCycleTime" SG_ 2432693154 BunkH1ParkHeaterTimer1_cmd 100;
BA_ "GenSigCycleTimeActive" SG_ 2432693154 BunkH1ParkHeaterTimer1_cmd 100;
BA_ "GenSigStartValue" SG_ 2432693154 BunkH1ParkHeaterTimer1_cmd 7;
BA_ "GenSigMaxLatency" SG_ 2432693154 BunkH1ParkHeaterTimer1_cmd 26;
BA_ "GenSigCycleTime" SG_ 2432693154 BnkH1IntLghtMMenu_stat_IL_Mode 100;
BA_ "GenSigCycleTimeActive" SG_ 2432693154 BnkH1IntLghtMMenu_stat_IL_Mode 100;
BA_ "GenSigStartValue" SG_ 2432693154 BnkH1IntLghtMMenu_stat_IL_Mode 7;
BA_ "GenSigCycleTime" SG_ 2432693154 BunkH1AudioSource_rqst2 100;
BA_ "GenSigCycleTimeActive" SG_ 2432693154 BunkH1AudioSource_rqst2 100;
BA_ "GenSigStartValue" SG_ 2432693154 BunkH1AudioSource_rqst2 15;
BA_ "GenSigSendType" SG_ 2432693154 BunkH1PowerWinCloseDSBtn_stat_UB 7;
BA_ "GenSigCycleTime" SG_ 2432693154 BnkH1IntLghtMMenu_stat_EventFlag 100;
BA_ "GenSigCycleTimeActive" SG_ 2432693154 BnkH1IntLghtMMenu_stat_EventFlag 100;
BA_ "GenSigCycleTime" SG_ 2432693154 BunkH1PowerWinOpenPSBtn_stat 100;
BA_ "GenSigCycleTimeActive" SG_ 2432693154 BunkH1PowerWinOpenPSBtn_stat 100;
BA_ "GenSigStartValue" SG_ 2432693154 BunkH1PowerWinOpenPSBtn_stat 3;
BA_ "GenSigMaxLatency" SG_ 2432693154 BunkH1PowerWinOpenPSBtn_stat 26;
BA_ "NeedsUpdateBit" SG_ 2432693154 BunkH1PowerWinOpenPSBtn_stat 1;
BA_ "GenSigCycleTime" SG_ 2432693154 BunkH1PowerWinClosePSBtn_stat 100;
BA_ "GenSigCycleTimeActive" SG_ 2432693154 BunkH1PowerWinClosePSBtn_stat 100;
BA_ "GenSigStartValue" SG_ 2432693154 BunkH1PowerWinClosePSBtn_stat 3;
BA_ "GenSigMaxLatency" SG_ 2432693154 BunkH1PowerWinClosePSBtn_stat 26;
BA_ "NeedsUpdateBit" SG_ 2432693154 BunkH1PowerWinClosePSBtn_stat 1;
BA_ "GenSigCycleTime" SG_ 2432693154 BunkH1TempInc_ButtonStatus 100;
BA_ "GenSigCycleTimeActive" SG_ 2432693154 BunkH1TempInc_ButtonStatus 100;
BA_ "GenSigStartValue" SG_ 2432693154 BunkH1TempInc_ButtonStatus 3;
BA_ "GenSigMaxLatency" SG_ 2432693154 BunkH1TempInc_ButtonStatus 26;
BA_ "GenSigSendType" SG_ 2671902708 FuncDiagDataIntTesterTGW2 7;
BA_ "Platform_VMCU1_Sig" SG_ 2671902708 FuncDiagDataIntTesterTGW2 1;
BA_ "GenSigSendType" SG_ 2671964834 DiagUUDTRespSig_F2_A2 7;
BA_ "GenSigSendType" SG_ 2671964824 DiagUUDTRespSig_F2_98 7;
BA_ "GenSigSendType" SG_ 2671964819 DiagUUDTRespSig_F2_93 7;
BA_ "Platform_VMCU1_Sig" SG_ 2671964819 DiagUUDTRespSig_F2_93 1;
BA_ "GenSigSendType" SG_ 2671964755 DiagUUDTRespSig_F2_53 7;
BA_ "GenSigSendType" SG_ 2671964710 DiagUUDTRespSig_F2_26 7;
BA_ "GenSigSendType" SG_ 2671834259 InternalTesterDiagSig_F4_93 7;
BA_ "Platform_VMCU1_Sig" SG_ 2671834259 InternalTesterDiagSig_F4_93 1;
BA_ "GenSigSendType" SG_ 2671834274 InternalTesterDiagSig_F4_A2 7;
BA_ "GenSigSendType" SG_ 2671834264 InternalTesterDiagSig_F4_98 7;
BA_ "GenSigSendType" SG_ 2671834195 InternalTesterDiagSig_F4_53 7;
BA_ "GenSigSendType" SG_ 2671834150 InternalTesterDiagSig_F4_26 7;
BA_ "GenSigSendType" SG_ 2671834003 InternalTesterDiagSig_F3_93 7;
BA_ "Platform_VMCU1_Sig" SG_ 2671834003 InternalTesterDiagSig_F3_93 1;
BA_ "GenSigSendType" SG_ 2671834018 InternalTesterDiagSig_F3_A2 7;
BA_ "GenSigSendType" SG_ 2671834008 InternalTesterDiagSig_F3_98 7;
BA_ "GenSigSendType" SG_ 2671833939 InternalTesterDiagSig_F3_53 7;
BA_ "GenSigSendType" SG_ 2671833894 InternalTesterDiagSig_F3_26 7;
BA_ "GenSigSendType" SG_ 2671809524 InternalTesterDiagSig_93_F4 7;
BA_ "Platform_VMCU1_Sig" SG_ 2671809524 InternalTesterDiagSig_93_F4 1;
BA_ "GenSigSendType" SG_ 2671813364 InternalTesterDiagSig_A2_F4 7;
BA_ "GenSigSendType" SG_ 2671810804 InternalTesterDiagSig_98_F4 7;
BA_ "GenSigSendType" SG_ 2671793140 InternalTesterDiagSig_53_F4 7;
BA_ "GenSigSendType" SG_ 2671781620 InternalTesterDiagSig_26_F4 7;
BA_ "GenSigSendType" SG_ 2671809523 InternalTesterDiagSig_93_F3 7;
BA_ "Platform_VMCU1_Sig" SG_ 2671809523 InternalTesterDiagSig_93_F3 1;
BA_ "GenSigSendType" SG_ 2671813363 InternalTesterDiagSig_A2_F3 7;
BA_ "GenSigSendType" SG_ 2671810803 InternalTesterDiagSig_98_F3 7;
BA_ "GenSigSendType" SG_ 2671793139 InternalTesterDiagSig_53_F3 7;
BA_ "GenSigSendType" SG_ 2671781619 InternalTesterDiagSig_26_F3 7;
BA_ "GenSigSendType" SG_ 2567057439 DiagFaultStat_WRCS_FailTA 3;
BA_ "NeedsUpdateBit" SG_ 2567057439 DiagFaultStat_WRCS_FailTA 1;
BA_ "GenSigSendType" SG_ 2567057439 DiagFaultStat_WRCS_DtcIdB 3;
BA_ "NeedsUpdateBit" SG_ 2567057439 DiagFaultStat_WRCS_DtcIdB 1;
BA_ "GenSigSendType" SG_ 2567057439 DiagFaultStat_WRCS_sg_UB 7;
BA_ "GenSigSendType" SG_ 2567057439 DiagFaultStat_WRCS_FailTB 3;
BA_ "NeedsUpdateBit" SG_ 2567057439 DiagFaultStat_WRCS_FailTB 1;
BA_ "GenSigSendType" SG_ 2567057439 DiagFaultStat_WRCS_EcuAdr 3;
BA_ "GenSigStartValue" SG_ 2567057439 DiagFaultStat_WRCS_EcuAdr 255;
BA_ "NeedsUpdateBit" SG_ 2567057439 DiagFaultStat_WRCS_EcuAdr 1;
BA_ "GenSigSendType" SG_ 2567057439 DiagFaultStat_WRCS_DtcIdA 3;
BA_ "NeedsUpdateBit" SG_ 2567057439 DiagFaultStat_WRCS_DtcIdA 1;
BA_ "GenSigSendType" SG_ 2567057438 DiagFaultStat_SRS_DtcIdA 3;
BA_ "NeedsUpdateBit" SG_ 2567057438 DiagFaultStat_SRS_DtcIdA 1;
BA_ "GenSigSendType" SG_ 2567057438 DiagFaultStat_SRS_sg_UB 7;
BA_ "GenSigSendType" SG_ 2567057438 DiagFaultStat_SRS_FailTA 3;
BA_ "NeedsUpdateBit" SG_ 2567057438 DiagFaultStat_SRS_FailTA 1;
BA_ "GenSigSendType" SG_ 2567057438 DiagFaultStat_SRS_FailTB 3;
BA_ "NeedsUpdateBit" SG_ 2567057438 DiagFaultStat_SRS_FailTB 1;
BA_ "GenSigSendType" SG_ 2567057438 DiagFaultStat_SRS_DtcIdB 3;
BA_ "NeedsUpdateBit" SG_ 2567057438 DiagFaultStat_SRS_DtcIdB 1;
BA_ "GenSigSendType" SG_ 2567057438 DiagFaultStat_SRS_EcuAdr 3;
BA_ "GenSigStartValue" SG_ 2567057438 DiagFaultStat_SRS_EcuAdr 255;
BA_ "NeedsUpdateBit" SG_ 2567057438 DiagFaultStat_SRS_EcuAdr 1;
BA_ "GenSigSendType" SG_ 2567057437 DiagFaultStat_LECM_DtcIdA 3;
BA_ "NeedsUpdateBit" SG_ 2567057437 DiagFaultStat_LECM_DtcIdA 1;
BA_ "GenSigSendType" SG_ 2567057437 DiagFaultStat_LECM_FailTA 3;
BA_ "NeedsUpdateBit" SG_ 2567057437 DiagFaultStat_LECM_FailTA 1;
BA_ "GenSigSendType" SG_ 2567057437 DiagFaultStat_LECM_FailTB 3;
BA_ "NeedsUpdateBit" SG_ 2567057437 DiagFaultStat_LECM_FailTB 1;
BA_ "GenSigSendType" SG_ 2567057437 DiagFaultStat_LECM_sg_UB 7;
BA_ "GenSigSendType" SG_ 2567057437 DiagFaultStat_LECM_DtcIdB 3;
BA_ "NeedsUpdateBit" SG_ 2567057437 DiagFaultStat_LECM_DtcIdB 1;
BA_ "GenSigSendType" SG_ 2567057437 DiagFaultStat_LECM_EcuAdr 3;
BA_ "GenSigStartValue" SG_ 2567057437 DiagFaultStat_LECM_EcuAdr 255;
BA_ "NeedsUpdateBit" SG_ 2567057437 DiagFaultStat_LECM_EcuAdr 1;
BA_ "GenSigSendType" SG_ 2567049378 DiagFaultStat_LECM3_DtcIdB 3;
BA_ "NeedsUpdateBit" SG_ 2567049378 DiagFaultStat_LECM3_DtcIdB 1;
BA_ "GenSigSendType" SG_ 2567049378 DiagFaultStat_LECM3_EcuAdr 3;
BA_ "GenSigStartValue" SG_ 2567049378 DiagFaultStat_LECM3_EcuAdr 255;
BA_ "NeedsUpdateBit" SG_ 2567049378 DiagFaultStat_LECM3_EcuAdr 1;
BA_ "GenSigSendType" SG_ 2567049378 DiagFaultStat_LECM3_sg_UB 7;
BA_ "GenSigSendType" SG_ 2567049378 DiagFaultStat_LECM3_DtcIdA 3;
BA_ "NeedsUpdateBit" SG_ 2567049378 DiagFaultStat_LECM3_DtcIdA 1;
BA_ "GenSigSendType" SG_ 2567049378 DiagFaultStat_LECM3_FailTA 3;
BA_ "NeedsUpdateBit" SG_ 2567049378 DiagFaultStat_LECM3_FailTA 1;
BA_ "GenSigSendType" SG_ 2567049378 DiagFaultStat_LECM3_FailTB 3;
BA_ "NeedsUpdateBit" SG_ 2567049378 DiagFaultStat_LECM3_FailTB 1;
BA_ "GenSigSendType" SG_ 2567049363 DiagFaultStat_CMS_EcuAdr 3;
BA_ "GenSigStartValue" SG_ 2567049363 DiagFaultStat_CMS_EcuAdr 147;
BA_ "NeedsUpdateBit" SG_ 2567049363 DiagFaultStat_CMS_EcuAdr 1;
BA_ "GenSigSendType" SG_ 2567049363 DiagFaultStat_CMS_DtcIdB 3;
BA_ "NeedsUpdateBit" SG_ 2567049363 DiagFaultStat_CMS_DtcIdB 1;
BA_ "GenSigSendType" SG_ 2567049363 DiagFaultStat_CMS_FailTB 3;
BA_ "NeedsUpdateBit" SG_ 2567049363 DiagFaultStat_CMS_FailTB 1;
BA_ "GenSigSendType" SG_ 2567049363 DiagFaultStat_CMS_sg_UB 7;
BA_ "GenSigSendType" SG_ 2567049363 DiagFaultStat_CMS_DtcIdA 3;
BA_ "NeedsUpdateBit" SG_ 2567049363 DiagFaultStat_CMS_DtcIdA 1;
BA_ "GenSigSendType" SG_ 2567049363 DiagFaultStat_CMS_FailTA 3;
BA_ "NeedsUpdateBit" SG_ 2567049363 DiagFaultStat_CMS_FailTA 1;
BA_ "GenSigSendType" SG_ 2567057436 DiagFaultStat_CCM_FailTB 3;
BA_ "NeedsUpdateBit" SG_ 2567057436 DiagFaultStat_CCM_FailTB 1;
BA_ "GenSigSendType" SG_ 2567057436 DiagFaultStat_CCM_DtcIdB 3;
BA_ "NeedsUpdateBit" SG_ 2567057436 DiagFaultStat_CCM_DtcIdB 1;
BA_ "GenSigSendType" SG_ 2567057436 DiagFaultStat_CCM_EcuAdr 3;
BA_ "GenSigStartValue" SG_ 2567057436 DiagFaultStat_CCM_EcuAdr 255;
BA_ "NeedsUpdateBit" SG_ 2567057436 DiagFaultStat_CCM_EcuAdr 1;
BA_ "GenSigSendType" SG_ 2567057436 DiagFaultStat_CCM_sg_UB 7;
BA_ "GenSigSendType" SG_ 2567057436 DiagFaultStat_CCM_DtcIdA 3;
BA_ "NeedsUpdateBit" SG_ 2567057436 DiagFaultStat_CCM_DtcIdA 1;
BA_ "GenSigSendType" SG_ 2567057436 DiagFaultStat_CCM_FailTA 3;
BA_ "NeedsUpdateBit" SG_ 2567057436 DiagFaultStat_CCM_FailTA 1;
BA_ "GenSigSendType" SG_ 2634020435 Debug_6_SRS 1;
BA_ "GenSigMaxLatency" SG_ 2634020435 Debug_6_SRS 59;
BA_ "GenSigSendType" SG_ 2634020514 Debug_6_LECM 1;
BA_ "GenSigMaxLatency" SG_ 2634020514 Debug_6_LECM 59;
BA_ "GenSigSendType" SG_ 2634022306 Debug_6_LECM3 1;
BA_ "GenSigSendType" SG_ 2634020499 Debug_6_CMS 1;
BA_ "GenSigSendType" SG_ 2634020504 Debug_6_CCM 1;
BA_ "GenSigMaxLatency" SG_ 2634020504 Debug_6_CCM 59;
BA_ "GenSigSendType" SG_ 2634020179 Debug_5_SRS 1;
BA_ "GenSigMaxLatency" SG_ 2634020179 Debug_5_SRS 59;
BA_ "GenSigSendType" SG_ 2634020258 Debug_5_LECM 1;
BA_ "GenSigMaxLatency" SG_ 2634020258 Debug_5_LECM 59;
BA_ "GenSigSendType" SG_ 2634022050 Debug_5_LECM3 1;
BA_ "GenSigSendType" SG_ 2634020243 Debug_5_CMS 1;
BA_ "GenSigSendType" SG_ 2634020248 Debug_5_CCM 1;
BA_ "GenSigMaxLatency" SG_ 2634020248 Debug_5_CCM 59;
BA_ "GenSigSendType" SG_ 2634019923 Debug_4_SRS 1;
BA_ "GenSigMaxLatency" SG_ 2634019923 Debug_4_SRS 59;
BA_ "GenSigSendType" SG_ 2634020002 Debug_4_LECM 1;
BA_ "GenSigMaxLatency" SG_ 2634020002 Debug_4_LECM 59;
BA_ "GenSigSendType" SG_ 2634021794 Debug_4_LECM3 1;
BA_ "GenSigSendType" SG_ 2634019987 Debug_4_CMS 1;
BA_ "GenSigSendType" SG_ 2634019992 Debug_4_CCM 1;
BA_ "GenSigMaxLatency" SG_ 2634019992 Debug_4_CCM 59;
BA_ "GenSigSendType" SG_ 2634019667 Debug_3_SRS 1;
BA_ "GenSigMaxLatency" SG_ 2634019667 Debug_3_SRS 59;
BA_ "GenSigSendType" SG_ 2634019746 Debug_3_LECM 1;
BA_ "GenSigMaxLatency" SG_ 2634019746 Debug_3_LECM 59;
BA_ "GenSigSendType" SG_ 2634021538 Debug_3_LECM3 1;
BA_ "GenSigSendType" SG_ 2634019731 Debug_3_CMS 1;
BA_ "GenSigSendType" SG_ 2634019736 Debug_3_CCM 1;
BA_ "GenSigMaxLatency" SG_ 2634019736 Debug_3_CCM 59;
BA_ "GenSigSendType" SG_ 2634019411 Debug_2_SRS 1;
BA_ "GenSigMaxLatency" SG_ 2634019411 Debug_2_SRS 59;
BA_ "GenSigSendType" SG_ 2634019490 Debug_2_LECM 1;
BA_ "GenSigMaxLatency" SG_ 2634019490 Debug_2_LECM 59;
BA_ "GenSigSendType" SG_ 2634021282 Debug_2_LECM3 1;
BA_ "GenSigSendType" SG_ 2634019475 Debug_2_CMS 1;
BA_ "GenSigSendType" SG_ 2634019480 Debug_2_CCM 1;
BA_ "GenSigMaxLatency" SG_ 2634019480 Debug_2_CCM 59;
BA_ "GenSigSendType" SG_ 2634019155 Debug_1_SRS 1;
BA_ "GenSigSendType" SG_ 2634019234 Debug_1_LECM 1;
BA_ "GenSigSendType" SG_ 2634021026 Debug_1_LECM3 1;
BA_ "GenSigSendType" SG_ 2634019219 Debug_1_CMS 1;
BA_ "GenSigSendType" SG_ 2634019224 Debug_1_CCM 1;
BA_ "GenSigCycleTime" SG_ 2499790739 CMSFailureStat_SqC 100;
BA_ "GenSigCycleTimeActive" SG_ 2499790739 CMSFailureStat_SqC 100;
BA_ "GenSigCycleTime" SG_ 2499790739 CMSFailureStat_Status 100;
BA_ "GenSigCycleTimeActive" SG_ 2499790739 CMSFailureStat_Status 100;
BA_ "GenSigStartValue" SG_ 2499790739 CMSFailureStat_Status 7;
BA_ "GenSigCycleTime" SG_ 2499790739 CMSFailureStat_CRC 100;
BA_ "GenSigCycleTimeActive" SG_ 2499790739 CMSFailureStat_CRC 100;
BA_ "E2EDataId" SG_ 2499790739 CMSFailureStat_CRC 318;
BA_ "E2EDataLength" SG_ 2499790739 CMSFailureStat_CRC 16;
BA_ "E2EProfile" SG_ 2499790739 CMSFailureStat_CRC "P01";
BA_ "GenSigCycleTime" SG_ 2499790995 CMSManualAlignmStat_CRC 100;
BA_ "GenSigCycleTimeActive" SG_ 2499790995 CMSManualAlignmStat_CRC 100;
BA_ "E2EDataId" SG_ 2499790995 CMSManualAlignmStat_CRC 316;
BA_ "E2EDataLength" SG_ 2499790995 CMSManualAlignmStat_CRC 16;
BA_ "E2EProfile" SG_ 2499790995 CMSManualAlignmStat_CRC "P01";
BA_ "GenSigCycleTime" SG_ 2499790995 CMSActvtnDeactvtnStat_Status 100;
BA_ "GenSigCycleTimeActive" SG_ 2499790995 CMSActvtnDeactvtnStat_Status 100;
BA_ "GenSigStartValue" SG_ 2499790995 CMSActvtnDeactvtnStat_Status 7;
BA_ "GenSigCycleTime" SG_ 2499790995 CMSZoomStat_Status 100;
BA_ "GenSigCycleTimeActive" SG_ 2499790995 CMSZoomStat_Status 100;
BA_ "GenSigStartValue" SG_ 2499790995 CMSZoomStat_Status 3;
BA_ "GenSigCycleTime" SG_ 2499790995 CMSZoomStat_SqC 100;
BA_ "GenSigCycleTimeActive" SG_ 2499790995 CMSZoomStat_SqC 100;
BA_ "GenSigCycleTime" SG_ 2499790995 CMSFoldingStat_CRC 100;
BA_ "GenSigCycleTimeActive" SG_ 2499790995 CMSFoldingStat_CRC 100;
BA_ "E2EDataId" SG_ 2499790995 CMSFoldingStat_CRC 313;
BA_ "E2EDataLength" SG_ 2499790995 CMSFoldingStat_CRC 16;
BA_ "E2EProfile" SG_ 2499790995 CMSFoldingStat_CRC "P01";
BA_ "GenSigCycleTime" SG_ 2499790995 CMSActvtnDeactvtnStat_SqC 100;
BA_ "GenSigCycleTimeActive" SG_ 2499790995 CMSActvtnDeactvtnStat_SqC 100;
BA_ "GenSigCycleTime" SG_ 2499790995 CMSFoldingStat_Status 100;
BA_ "GenSigCycleTimeActive" SG_ 2499790995 CMSFoldingStat_Status 100;
BA_ "GenSigStartValue" SG_ 2499790995 CMSFoldingStat_Status 7;
BA_ "GenSigCycleTime" SG_ 2499790995 CMSManualAlignmStat_Status 100;
BA_ "GenSigCycleTimeActive" SG_ 2499790995 CMSManualAlignmStat_Status 100;
BA_ "GenSigStartValue" SG_ 2499790995 CMSManualAlignmStat_Status 7;
BA_ "GenSigCycleTime" SG_ 2499790995 CMSManualAlignmStat_SqC 100;
BA_ "GenSigCycleTimeActive" SG_ 2499790995 CMSManualAlignmStat_SqC 100;
BA_ "GenSigCycleTime" SG_ 2499790995 CMSFoldingStat_SqC 100;
BA_ "GenSigCycleTimeActive" SG_ 2499790995 CMSFoldingStat_SqC 100;
BA_ "GenSigCycleTime" SG_ 2499790995 CMSZoomStat_CRC 100;
BA_ "GenSigCycleTimeActive" SG_ 2499790995 CMSZoomStat_CRC 100;
BA_ "E2EDataId" SG_ 2499790995 CMSZoomStat_CRC 314;
BA_ "E2EDataLength" SG_ 2499790995 CMSZoomStat_CRC 16;
BA_ "E2EProfile" SG_ 2499790995 CMSZoomStat_CRC "P01";
BA_ "GenSigCycleTime" SG_ 2499790995 CMSActvtnDeactvtnStat_CRC 100;
BA_ "GenSigCycleTimeActive" SG_ 2499790995 CMSActvtnDeactvtnStat_CRC 100;
BA_ "E2EDataId" SG_ 2499790995 CMSActvtnDeactvtnStat_CRC 315;
BA_ "E2EDataLength" SG_ 2499790995 CMSActvtnDeactvtnStat_CRC 16;
BA_ "E2EProfile" SG_ 2499790995 CMSActvtnDeactvtnStat_CRC "P01";
BA_REL_ "GenSigFirstTimeoutTime" BU_SG_REL_ CIOM SG_ 2499772198 TipperTarpaulinRequest 3000;
BA_REL_ "GenSigTimeoutTime" BU_SG_REL_ CIOM SG_ 2499772198 TipperTarpaulinRequest 500;
BA_REL_ "GenSigFirstTimeoutTime" BU_SG_REL_ CIOM SG_ 2499772198 TipperUpDownRequest 3000;
BA_REL_ "GenSigTimeoutTime" BU_SG_REL_ CIOM SG_ 2499772198 TipperUpDownRequest 500;
BA_REL_ "GenSigFirstTimeoutTime" BU_SG_REL_ CIOM SG_ 2499772198 TailLiftMotionRequest 3000;
BA_REL_ "GenSigTimeoutTime" BU_SG_REL_ CIOM SG_ 2499772198 TailLiftMotionRequest 500;
BA_REL_ "GenSigFirstTimeoutTime" BU_SG_REL_ CIOM SG_ 2499772198 TipperEmergencyStop 3000;
BA_REL_ "GenSigTimeoutTime" BU_SG_REL_ CIOM SG_ 2499772198 TipperEmergencyStop 500;
BA_REL_ "GenSigFirstTimeoutTime" BU_SG_REL_ CIOM SG_ 2499772198 ExtraBbWrcWatchdog 3000;
BA_REL_ "GenSigTimeoutTime" BU_SG_REL_ CIOM SG_ 2499772198 ExtraBbWrcWatchdog 500;
BA_REL_ "GenSigFirstTimeoutTime" BU_SG_REL_ CIOM SG_ 2499772198 TipperTailGateRequest 3000;
BA_REL_ "GenSigTimeoutTime" BU_SG_REL_ CIOM SG_ 2499772198 TipperTailGateRequest 500;
BA_REL_ "GenSigFirstTimeoutTime" BU_SG_REL_ CIOM SG_ 2499772198 TipperTippingBodySelection 3000;
BA_REL_ "GenSigTimeoutTime" BU_SG_REL_ CIOM SG_ 2499772198 TipperTippingBodySelection 500;
BA_REL_ "GenSigFirstTimeoutTime" BU_SG_REL_ CIOM SG_ 2499772198 TipperShakerRequest 3000;
BA_REL_ "GenSigTimeoutTime" BU_SG_REL_ CIOM SG_ 2499772198 TipperShakerRequest 500;
BA_REL_ "GenSigFirstTimeoutTime" BU_SG_REL_ CIOM SG_ 2432679743 WRC5thWheelRequest 3000;
BA_REL_ "GenSigTimeoutTime" BU_SG_REL_ CIOM SG_ 2432679743 WRC5thWheelRequest 120;
BA_REL_ "GenSigFirstTimeoutTime" BU_SG_REL_ CIOM SG_ 2432679743 WRC_Docking_stat 3000;
BA_REL_ "GenSigTimeoutTime" BU_SG_REL_ CIOM SG_ 2432679743 WRC_Docking_stat 120;
BA_REL_ "GenSigFirstTimeoutTime" BU_SG_REL_ CIOM SG_ 2432679743 WRCLevelUserMemoryAction 3000;
BA_REL_ "GenSigTimeoutTime" BU_SG_REL_ CIOM SG_ 2432679743 WRCLevelUserMemoryAction 120;
BA_REL_ "GenSigFirstTimeoutTime" BU_SG_REL_ CIOM SG_ 2432679743 WRCLevelUserMemory 3000;
BA_REL_ "GenSigTimeoutTime" BU_SG_REL_ CIOM SG_ 2432679743 WRCLevelUserMemory 120;
BA_REL_ "GenSigFirstTimeoutTime" BU_SG_REL_ CIOM SG_ 2432679743 WrcEngSpdCtrlResumeButtonStat 3000;
BA_REL_ "GenSigTimeoutTime" BU_SG_REL_ CIOM SG_ 2432679743 WrcEngSpdCtrlResumeButtonStat 120;
BA_REL_ "GenSigFirstTimeoutTime" BU_SG_REL_ CIOM SG_ 2432679743 WRCBeaconRequest 3000;
BA_REL_ "GenSigTimeoutTime" BU_SG_REL_ CIOM SG_ 2432679743 WRCBeaconRequest 120;
BA_REL_ "GenSigFirstTimeoutTime" BU_SG_REL_ CIOM SG_ 2432679743 WrcEngSpdCtrlDecreaseButtStat 3000;
BA_REL_ "GenSigTimeoutTime" BU_SG_REL_ CIOM SG_ 2432679743 WrcEngSpdCtrlDecreaseButtStat 120;
BA_REL_ "GenSigFirstTimeoutTime" BU_SG_REL_ CIOM SG_ 2432679743 WRCEngineStartRequest 3000;
BA_REL_ "GenSigTimeoutTime" BU_SG_REL_ CIOM SG_ 2432679743 WRCEngineStartRequest 500;
BA_REL_ "GenSigFirstTimeoutTime" BU_SG_REL_ CIOM SG_ 2432679743 WrcEngSpdCtrlEnableStatus 3000;
BA_REL_ "GenSigTimeoutTime" BU_SG_REL_ CIOM SG_ 2432679743 WrcEngSpdCtrlEnableStatus 120;
BA_REL_ "GenSigFirstTimeoutTime" BU_SG_REL_ CIOM SG_ 2432679743 WRCCabBodyWLightsRqst 3000;
BA_REL_ "GenSigTimeoutTime" BU_SG_REL_ CIOM SG_ 2432679743 WRCCabBodyWLightsRqst 120;
BA_REL_ "GenSigFirstTimeoutTime" BU_SG_REL_ CIOM SG_ 2432679743 WRCEngineStopRequest 3000;
BA_REL_ "GenSigTimeoutTime" BU_SG_REL_ CIOM SG_ 2432679743 WRCEngineStopRequest 500;
BA_REL_ "GenSigFirstTimeoutTime" BU_SG_REL_ CIOM SG_ 2432679743 WrcEngSpdCtrlIncreaseButtStat 3000;
BA_REL_ "GenSigTimeoutTime" BU_SG_REL_ CIOM SG_ 2432679743 WrcEngSpdCtrlIncreaseButtStat 120;
BA_REL_ "GenSigFirstTimeoutTime" BU_SG_REL_ CIOM SG_ 2365554559 WrcPto1ButtonStatus 3000;
BA_REL_ "GenSigTimeoutTime" BU_SG_REL_ CIOM SG_ 2365554559 WrcPto1ButtonStatus 60;
BA_REL_ "GenSigFirstTimeoutTime" BU_SG_REL_ CIOM SG_ 2365554559 ECSStandByReqWRC 3000;
BA_REL_ "GenSigTimeoutTime" BU_SG_REL_ CIOM SG_ 2365554559 ECSStandByReqWRC 60;
BA_REL_ "GenSigFirstTimeoutTime" BU_SG_REL_ CIOM SG_ 2365554559 WRCCraneRequest 3000;
BA_REL_ "GenSigTimeoutTime" BU_SG_REL_ CIOM SG_ 2365554559 WRCCraneRequest 60;
BA_REL_ "GenSigFirstTimeoutTime" BU_SG_REL_ CIOM SG_ 2365554559 WRCUnlockButtonStatus 3000;
BA_REL_ "GenSigTimeoutTime" BU_SG_REL_ CIOM SG_ 2365554559 WRCUnlockButtonStatus 60;
BA_REL_ "GenSigFirstTimeoutTime" BU_SG_REL_ CIOM SG_ 2365554559 WRCRollRequest 3000;
BA_REL_ "GenSigTimeoutTime" BU_SG_REL_ CIOM SG_ 2365554559 WRCRollRequest 60;
BA_REL_ "GenSigFirstTimeoutTime" BU_SG_REL_ CIOM SG_ 2365554559 WRCAux3Request 3000;
BA_REL_ "GenSigTimeoutTime" BU_SG_REL_ CIOM SG_ 2365554559 WRCAux3Request 60;
BA_REL_ "GenSigFirstTimeoutTime" BU_SG_REL_ CIOM SG_ 2365554559 WRCAux2Request 3000;
BA_REL_ "GenSigTimeoutTime" BU_SG_REL_ CIOM SG_ 2365554559 WRCAux2Request 60;
BA_REL_ "GenSigFirstTimeoutTime" BU_SG_REL_ CIOM SG_ 2365554559 WrcPto3ButtonStatus 3000;
BA_REL_ "GenSigTimeoutTime" BU_SG_REL_ CIOM SG_ 2365554559 WrcPto3ButtonStatus 60;
BA_REL_ "GenSigFirstTimeoutTime" BU_SG_REL_ CIOM SG_ 2365554559 WRCLevelAdjustmentAction 3000;
BA_REL_ "GenSigTimeoutTime" BU_SG_REL_ CIOM SG_ 2365554559 WRCLevelAdjustmentAction 60;
BA_REL_ "GenSigFirstTimeoutTime" BU_SG_REL_ CIOM SG_ 2365554559 WRCAux4Request 3000;
BA_REL_ "GenSigTimeoutTime" BU_SG_REL_ CIOM SG_ 2365554559 WRCAux4Request 60;
BA_REL_ "GenSigFirstTimeoutTime" BU_SG_REL_ CIOM SG_ 2365554559 WRCAux5Request 3000;
BA_REL_ "GenSigTimeoutTime" BU_SG_REL_ CIOM SG_ 2365554559 WRCAux5Request 60;
BA_REL_ "GenSigFirstTimeoutTime" BU_SG_REL_ CIOM SG_ 2365554559 WRCAux6Request 3000;
BA_REL_ "GenSigTimeoutTime" BU_SG_REL_ CIOM SG_ 2365554559 WRCAux6Request 60;
BA_REL_ "GenSigFirstTimeoutTime" BU_SG_REL_ CIOM SG_ 2365554559 WRCSideReverseWorkingRequest 3000;
BA_REL_ "GenSigTimeoutTime" BU_SG_REL_ CIOM SG_ 2365554559 WRCSideReverseWorkingRequest 60;
BA_REL_ "GenSigFirstTimeoutTime" BU_SG_REL_ CIOM SG_ 2365554559 WrcPto2ButtonStatus 3000;
BA_REL_ "GenSigTimeoutTime" BU_SG_REL_ CIOM SG_ 2365554559 WrcPto2ButtonStatus 60;
BA_REL_ "GenSigFirstTimeoutTime" BU_SG_REL_ CIOM SG_ 2365554559 WRCTailLiftRequest 3000;
BA_REL_ "GenSigTimeoutTime" BU_SG_REL_ CIOM SG_ 2365554559 WRCTailLiftRequest 60;
BA_REL_ "GenSigFirstTimeoutTime" BU_SG_REL_ CIOM SG_ 2365554559 WrcPto4ButtonStatus 3000;
BA_REL_ "GenSigTimeoutTime" BU_SG_REL_ CIOM SG_ 2365554559 WrcPto4ButtonStatus 60;
BA_REL_ "GenSigFirstTimeoutTime" BU_SG_REL_ CIOM SG_ 2365554559 WRCLevelAdjustmentStroke 3000;
BA_REL_ "GenSigTimeoutTime" BU_SG_REL_ CIOM SG_ 2365554559 WRCLevelAdjustmentStroke 60;
BA_REL_ "GenSigFirstTimeoutTime" BU_SG_REL_ CIOM SG_ 2365554559 WRCLevelAdjustmentAxles 3000;
BA_REL_ "GenSigTimeoutTime" BU_SG_REL_ CIOM SG_ 2365554559 WRCLevelAdjustmentAxles 60;
BA_REL_ "GenSigFirstTimeoutTime" BU_SG_REL_ CIOM SG_ 2365554559 WRCAirSuspensionStopRequest 3000;
BA_REL_ "GenSigTimeoutTime" BU_SG_REL_ CIOM SG_ 2365554559 WRCAirSuspensionStopRequest 60;
BA_REL_ "GenSigFirstTimeoutTime" BU_SG_REL_ CIOM SG_ 2365554559 WRCAux1Request 3000;
BA_REL_ "GenSigTimeoutTime" BU_SG_REL_ CIOM SG_ 2365554559 WRCAux1Request 60;
BA_REL_ "GenSigFirstTimeoutTime" BU_SG_REL_ CIOM SG_ 2365554559 WRCLockButtonStatus 3000;
BA_REL_ "GenSigTimeoutTime" BU_SG_REL_ CIOM SG_ 2365554559 WRCLockButtonStatus 60;
BA_REL_ "GenSigFirstTimeoutTime" BU_SG_REL_ CIOM SG_ 2516576083 TrafficAccidentStat_Status 3000;
BA_REL_ "GenSigTimeoutTime" BU_SG_REL_ CIOM SG_ 2516576083 TrafficAccidentStat_Status 600;
BA_REL_ "GenSigFirstTimeoutTime" BU_SG_REL_ CIOM SG_ 2516576083 TrafficAccidentStat_CRC 3000;
BA_REL_ "GenSigTimeoutTime" BU_SG_REL_ CIOM SG_ 2516576083 TrafficAccidentStat_CRC 600;
BA_REL_ "GenSigFirstTimeoutTime" BU_SG_REL_ CIOM SG_ 2516576083 TrafficAccidentStat_SqC 3000;
BA_REL_ "GenSigTimeoutTime" BU_SG_REL_ CIOM SG_ 2516576083 TrafficAccidentStat_SqC 600;
BA_REL_ "GenSigFirstTimeoutTime" BU_SG_REL_ CIOM SG_ 2432689747 SideColliAccidentStat_RightSide 3000;
BA_REL_ "GenSigTimeoutTime" BU_SG_REL_ CIOM SG_ 2432689747 SideColliAccidentStat_RightSide 120;
BA_REL_ "GenSigFirstTimeoutTime" BU_SG_REL_ CIOM SG_ 2432689747 SideColliAccidentStat_LeftSide 3000;
BA_REL_ "GenSigTimeoutTime" BU_SG_REL_ CIOM SG_ 2432689747 SideColliAccidentStat_LeftSide 120;
BA_REL_ "GenSigFirstTimeoutTime" BU_SG_REL_ CIOM SG_ 2432689747 SideColliAccidentStat_CRC 3000;
BA_REL_ "GenSigTimeoutTime" BU_SG_REL_ CIOM SG_ 2432689747 SideColliAccidentStat_CRC 120;
BA_REL_ "GenSigFirstTimeoutTime" BU_SG_REL_ CIOM SG_ 2432689747 SideColliAccidentStat_SqC 3000;
BA_REL_ "GenSigTimeoutTime" BU_SG_REL_ CIOM SG_ 2432689747 SideColliAccidentStat_SqC 120;
BA_REL_ "GenSigFirstTimeoutTime" BU_SG_REL_ CIOM SG_ 2499788607 TrafficAccShutDownReq_CRC 3000;
BA_REL_ "GenSigTimeoutTime" BU_SG_REL_ CIOM SG_ 2499788607 TrafficAccShutDownReq_CRC 300;
BA_REL_ "GenSigFirstTimeoutTime" BU_SG_REL_ CIOM SG_ 2499788607 TrafficAccIntlightReq 3000;
BA_REL_ "GenSigTimeoutTime" BU_SG_REL_ CIOM SG_ 2499788607 TrafficAccIntlightReq 300;
BA_REL_ "GenSigFirstTimeoutTime" BU_SG_REL_ CIOM SG_ 2499788607 TrafficAccShutDownReq_Rqst 3000;
BA_REL_ "GenSigTimeoutTime" BU_SG_REL_ CIOM SG_ 2499788607 TrafficAccShutDownReq_Rqst 300;
BA_REL_ "GenSigFirstTimeoutTime" BU_SG_REL_ CIOM SG_ 2499788607 ECUVIN_rqst 3000;
BA_REL_ "GenSigTimeoutTime" BU_SG_REL_ CIOM SG_ 2499788607 ECUVIN_rqst 300;
BA_REL_ "GenSigFirstTimeoutTime" BU_SG_REL_ CIOM SG_ 2499788607 TrafficAccShutDownReq_SqC 3000;
BA_REL_ "GenSigTimeoutTime" BU_SG_REL_ CIOM SG_ 2499788607 TrafficAccShutDownReq_SqC 300;
BA_REL_ "GenSigFirstTimeoutTime" BU_SG_REL_ CIOM SG_ 2432689491 SRSWarningLamp 3000;
BA_REL_ "GenSigTimeoutTime" BU_SG_REL_ CIOM SG_ 2432689491 SRSWarningLamp 120;
BA_REL_ "GenSigFirstTimeoutTime" BU_SG_REL_ CCM SG_ 2432689491 RollOverAccidentStatus 3000;
BA_REL_ "GenSigTimeoutTime" BU_SG_REL_ CCM SG_ 2432689491 RollOverAccidentStatus 120;
BA_REL_ "GenSigFirstTimeoutTime" BU_SG_REL_ CIOM SG_ 2432689491 RollOverAccidentStatus 3000;
BA_REL_ "GenSigTimeoutTime" BU_SG_REL_ CIOM SG_ 2432689491 RollOverAccidentStatus 120;
BA_REL_ "GenSigFirstTimeoutTime" BU_SG_REL_ CIOM SG_ 2432689491 SRSAirbagStatus 3000;
BA_REL_ "GenSigTimeoutTime" BU_SG_REL_ CIOM SG_ 2432689491 SRSAirbagStatus 120;
BA_REL_ "GenSigFirstTimeoutTime" BU_SG_REL_ CIOM SG_ 2432689491 EmergencyDoorsUnlock_rqst_CRC 3000;
BA_REL_ "GenSigTimeoutTime" BU_SG_REL_ CIOM SG_ 2432689491 EmergencyDoorsUnlock_rqst_CRC 120;
BA_REL_ "GenSigFirstTimeoutTime" BU_SG_REL_ CIOM SG_ 2432689491 EmergencyDoorsUnlock_rqst 3000;
BA_REL_ "GenSigTimeoutTime" BU_SG_REL_ CIOM SG_ 2432689491 EmergencyDoorsUnlock_rqst 120;
BA_REL_ "GenSigFirstTimeoutTime" BU_SG_REL_ CIOM SG_ 2432689491 TrafficAccidentHzdActvRqst_CRC 3000;
BA_REL_ "GenSigTimeoutTime" BU_SG_REL_ CIOM SG_ 2432689491 TrafficAccidentHzdActvRqst_CRC 120;
BA_REL_ "GenSigFirstTimeoutTime" BU_SG_REL_ CIOM SG_ 2432689491 SRSWarningLamp_SqC 3000;
BA_REL_ "GenSigTimeoutTime" BU_SG_REL_ CIOM SG_ 2432689491 SRSWarningLamp_SqC 120;
BA_REL_ "GenSigFirstTimeoutTime" BU_SG_REL_ CIOM SG_ 2432689491 SRSWarningLamp_CRC 3000;
BA_REL_ "GenSigTimeoutTime" BU_SG_REL_ CIOM SG_ 2432689491 SRSWarningLamp_CRC 120;
BA_REL_ "GenSigFirstTimeoutTime" BU_SG_REL_ CIOM SG_ 2432689491 TrafficAccidentHazardLightRqst 3000;
BA_REL_ "GenSigTimeoutTime" BU_SG_REL_ CIOM SG_ 2432689491 TrafficAccidentHazardLightRqst 120;
BA_REL_ "GenSigFirstTimeoutTime" BU_SG_REL_ CIOM SG_ 2432689491 EmergencyDoorsUnlock_rqst_SqC 3000;
BA_REL_ "GenSigTimeoutTime" BU_SG_REL_ CIOM SG_ 2432689491 EmergencyDoorsUnlock_rqst_SqC 120;
BA_REL_ "GenSigFirstTimeoutTime" BU_SG_REL_ CIOM SG_ 2432689491 TrafficAccidentHzdActvRqst_SqC 3000;
BA_REL_ "GenSigTimeoutTime" BU_SG_REL_ CIOM SG_ 2432689491 TrafficAccidentHzdActvRqst_SqC 120;
BA_REL_ "GenSigFirstTimeoutTime" BU_SG_REL_ CIOM SG_ 2432689491 FrontalCollisionAccidentStatus 3000;
BA_REL_ "GenSigTimeoutTime" BU_SG_REL_ CIOM SG_ 2432689491 FrontalCollisionAccidentStatus 120;
BA_REL_ "GenSigFirstTimeoutTime" BU_SG_REL_ CCM SG_ 2432689491 FrontalCollisionAccidentStatus 3000;
BA_REL_ "GenSigTimeoutTime" BU_SG_REL_ CCM SG_ 2432689491 FrontalCollisionAccidentStatus 120;
BA_REL_ "GenSigFirstTimeoutTime" BU_SG_REL_ CIOM SG_ 2549208482 LECM_Ent_UpDown_WheelStatus 4800;
BA_REL_ "GenSigTimeoutTime" BU_SG_REL_ CIOM SG_ 2549208482 LECM_Ent_UpDown_WheelStatus 1200;
BA_REL_ "GenSigFirstTimeoutTime" BU_SG_REL_ CIOM SG_ 2549208482 LECM_IntLight_SlprMaxLight_BS 4800;
BA_REL_ "GenSigTimeoutTime" BU_SG_REL_ CIOM SG_ 2549208482 LECM_IntLight_SlprMaxLight_BS 1200;
BA_REL_ "GenSigFirstTimeoutTime" BU_SG_REL_ CIOM SG_ 2549208482 LECM_CabClim_Pwr_BtnStat 4800;
BA_REL_ "GenSigTimeoutTime" BU_SG_REL_ CIOM SG_ 2549208482 LECM_CabClim_Pwr_BtnStat 1200;
BA_REL_ "GenSigFirstTimeoutTime" BU_SG_REL_ CIOM SG_ 2549208482 LECM_LockControl_Lock_BtnStat 4800;
BA_REL_ "GenSigTimeoutTime" BU_SG_REL_ CIOM SG_ 2549208482 LECM_LockControl_Lock_BtnStat 1200;
BA_REL_ "GenSigFirstTimeoutTime" BU_SG_REL_ CIOM SG_ 2549208482 LECM_CabClim_Auto_BtnStat 4800;
BA_REL_ "GenSigTimeoutTime" BU_SG_REL_ CIOM SG_ 2549208482 LECM_CabClim_Auto_BtnStat 1200;
BA_REL_ "GenSigFirstTimeoutTime" BU_SG_REL_ CIOM SG_ 2549208482 LECM_CabClim_AC_BtnStat 4800;
BA_REL_ "GenSigTimeoutTime" BU_SG_REL_ CIOM SG_ 2549208482 LECM_CabClim_AC_BtnStat 1200;
BA_REL_ "GenSigFirstTimeoutTime" BU_SG_REL_ CIOM SG_ 2549208482 LECM_CabClim_FrPwr_BtnStat 4800;
BA_REL_ "GenSigTimeoutTime" BU_SG_REL_ CIOM SG_ 2549208482 LECM_CabClim_FrPwr_BtnStat 1200;
BA_REL_ "GenSigFirstTimeoutTime" BU_SG_REL_ CIOM SG_ 2549208482 LECM_Ent_Volume_WheelStatus 4800;
BA_REL_ "GenSigTimeoutTime" BU_SG_REL_ CIOM SG_ 2549208482 LECM_Ent_Volume_WheelStatus 1200;
BA_REL_ "GenSigFirstTimeoutTime" BU_SG_REL_ CIOM SG_ 2549208482 LECMCabClimSetTempSelectGuiReq 4800;
BA_REL_ "GenSigTimeoutTime" BU_SG_REL_ CIOM SG_ 2549208482 LECMCabClimSetTempSelectGuiReq 1200;
BA_REL_ "GenSigFirstTimeoutTime" BU_SG_REL_ CIOM SG_ 2549208482 LECM_IntLight_SlprAmbLow_BS 4800;
BA_REL_ "GenSigTimeoutTime" BU_SG_REL_ CIOM SG_ 2549208482 LECM_IntLight_SlprAmbLow_BS 1200;
BA_REL_ "GenSigFirstTimeoutTime" BU_SG_REL_ CIOM SG_ 2549208482 LECM_CabClim_MaxDef_GuiReq 4800;
BA_REL_ "GenSigTimeoutTime" BU_SG_REL_ CIOM SG_ 2549208482 LECM_CabClim_MaxDef_GuiReq 1200;
BA_REL_ "GenSigFirstTimeoutTime" BU_SG_REL_ CIOM SG_ 2549208482 LECM_CabClim_Fan_WheelStatus 4800;
BA_REL_ "GenSigTimeoutTime" BU_SG_REL_ CIOM SG_ 2549208482 LECM_CabClim_Fan_WheelStatus 1200;
BA_REL_ "GenSigFirstTimeoutTime" BU_SG_REL_ CIOM SG_ 2549208482 LECM_IntLight_SlprAmbUpp_BS 4800;
BA_REL_ "GenSigTimeoutTime" BU_SG_REL_ CIOM SG_ 2549208482 LECM_IntLight_SlprAmbUpp_BS 1200;
BA_REL_ "GenSigFirstTimeoutTime" BU_SG_REL_ CIOM SG_ 2549208482 LECM_Ent_AudioSettingsViewSts 4800;
BA_REL_ "GenSigTimeoutTime" BU_SG_REL_ CIOM SG_ 2549208482 LECM_Ent_AudioSettingsViewSts 1200;
BA_REL_ "GenSigFirstTimeoutTime" BU_SG_REL_ CIOM SG_ 2549208482 LECM_Panic_CMS_BtnStat 4800;
BA_REL_ "GenSigTimeoutTime" BU_SG_REL_ CIOM SG_ 2549208482 LECM_Panic_CMS_BtnStat 1200;
BA_REL_ "GenSigFirstTimeoutTime" BU_SG_REL_ CIOM SG_ 2549208482 LECM_CabClim_Sync_GuiReq 4800;
BA_REL_ "GenSigTimeoutTime" BU_SG_REL_ CIOM SG_ 2549208482 LECM_CabClim_Sync_GuiReq 1200;
BA_REL_ "GenSigFirstTimeoutTime" BU_SG_REL_ CIOM SG_ 2549208482 LecmCutOffAnswerGuiRqst 4800;
BA_REL_ "GenSigTimeoutTime" BU_SG_REL_ CIOM SG_ 2549208482 LecmCutOffAnswerGuiRqst 1200;
BA_REL_ "GenSigFirstTimeoutTime" BU_SG_REL_ CIOM SG_ 2549208482 LECM_Ent_MediaSource_BtnStat 4800;
BA_REL_ "GenSigTimeoutTime" BU_SG_REL_ CIOM SG_ 2549208482 LECM_Ent_MediaSource_BtnStat 1200;
BA_REL_ "GenSigFirstTimeoutTime" BU_SG_REL_ CIOM SG_ 2549208482 LECM_CabClim_Temp_WheelStatus 4800;
BA_REL_ "GenSigTimeoutTime" BU_SG_REL_ CIOM SG_ 2549208482 LECM_CabClim_Temp_WheelStatus 1200;
BA_REL_ "GenSigFirstTimeoutTime" BU_SG_REL_ CIOM SG_ 2549208482 LECM_Power_Inverter_BtnStat 4800;
BA_REL_ "GenSigTimeoutTime" BU_SG_REL_ CIOM SG_ 2549208482 LECM_Power_Inverter_BtnStat 1200;
BA_REL_ "GenSigFirstTimeoutTime" BU_SG_REL_ CIOM SG_ 2549208482 LECM_Ent_SkpLeft_BtnStat 4800;
BA_REL_ "GenSigTimeoutTime" BU_SG_REL_ CIOM SG_ 2549208482 LECM_Ent_SkpLeft_BtnStat 1200;
BA_REL_ "GenSigFirstTimeoutTime" BU_SG_REL_ CIOM SG_ 2549208482 LECM_IntLight_SlprDecrease_BS 4800;
BA_REL_ "GenSigTimeoutTime" BU_SG_REL_ CIOM SG_ 2549208482 LECM_IntLight_SlprDecrease_BS 1200;
BA_REL_ "GenSigFirstTimeoutTime" BU_SG_REL_ CIOM SG_ 2549208482 LECM_Ent_OnOff_BtnStat 4800;
BA_REL_ "GenSigTimeoutTime" BU_SG_REL_ CIOM SG_ 2549208482 LECM_Ent_OnOff_BtnStat 1200;
BA_REL_ "GenSigFirstTimeoutTime" BU_SG_REL_ CIOM SG_ 2549208482 LECM_IntLight_SlprIncrease_BS 4800;
BA_REL_ "GenSigTimeoutTime" BU_SG_REL_ CIOM SG_ 2549208482 LECM_IntLight_SlprIncrease_BS 1200;
BA_REL_ "GenSigFirstTimeoutTime" BU_SG_REL_ CIOM SG_ 2549208482 LECM_Ent_SkpRight_BtnStat 4800;
BA_REL_ "GenSigTimeoutTime" BU_SG_REL_ CIOM SG_ 2549208482 LECM_Ent_SkpRight_BtnStat 1200;
BA_REL_ "GenSigFirstTimeoutTime" BU_SG_REL_ CIOM SG_ 2566337698 LECM_Display_Navi_OK_BtnStat 12000;
BA_REL_ "GenSigTimeoutTime" BU_SG_REL_ CIOM SG_ 2566337698 LECM_Display_Navi_OK_BtnStat 3000;
BA_REL_ "GenSigFirstTimeoutTime" BU_SG_REL_ CIOM SG_ 2566337698 LECM_AlClkSnze_GRqst_ID 12000;
BA_REL_ "GenSigTimeoutTime" BU_SG_REL_ CIOM SG_ 2566337698 LECM_AlClkSnze_GRqst_ID 3000;
BA_REL_ "GenSigFirstTimeoutTime" BU_SG_REL_ CIOM SG_ 2566337698 LECM_AlClkSetAl_GRqst_Mode 12000;
BA_REL_ "GenSigTimeoutTime" BU_SG_REL_ CIOM SG_ 2566337698 LECM_AlClkSetAl_GRqst_Mode 3000;
BA_REL_ "GenSigFirstTimeoutTime" BU_SG_REL_ CIOM SG_ 2566337698 LECM_AlClkSetAl_GRqst_Stat 12000;
BA_REL_ "GenSigTimeoutTime" BU_SG_REL_ CIOM SG_ 2566337698 LECM_AlClkSetAl_GRqst_Stat 3000;
BA_REL_ "GenSigFirstTimeoutTime" BU_SG_REL_ CIOM SG_ 2566337698 LECM_AlClkSetAl_GRqst_SetHr 12000;
BA_REL_ "GenSigTimeoutTime" BU_SG_REL_ CIOM SG_ 2566337698 LECM_AlClkSetAl_GRqst_SetHr 3000;
BA_REL_ "GenSigFirstTimeoutTime" BU_SG_REL_ CIOM SG_ 2566337698 LECM_AlClkSetAl_GRqst_ID 12000;
BA_REL_ "GenSigTimeoutTime" BU_SG_REL_ CIOM SG_ 2566337698 LECM_AlClkSetAl_GRqst_ID 3000;
BA_REL_ "GenSigFirstTimeoutTime" BU_SG_REL_ CIOM SG_ 2566337698 LECM_Display_Navi_WheelStatus 12000;
BA_REL_ "GenSigTimeoutTime" BU_SG_REL_ CIOM SG_ 2566337698 LECM_Display_Navi_WheelStatus 3000;
BA_REL_ "GenSigFirstTimeoutTime" BU_SG_REL_ CIOM SG_ 2566337698 LECM_AlClkSetAl_GRqst_DaySet 12000;
BA_REL_ "GenSigTimeoutTime" BU_SG_REL_ CIOM SG_ 2566337698 LECM_AlClkSetAl_GRqst_DaySet 3000;
BA_REL_ "GenSigFirstTimeoutTime" BU_SG_REL_ CIOM SG_ 2566337698 LECM_AlClkSetAl_GRqst_Type 12000;
BA_REL_ "GenSigTimeoutTime" BU_SG_REL_ CIOM SG_ 2566337698 LECM_AlClkSetAl_GRqst_Type 3000;
BA_REL_ "GenSigFirstTimeoutTime" BU_SG_REL_ CIOM SG_ 2566337698 LECM_AlClkSetAl_GRqst_SetMin 12000;
BA_REL_ "GenSigTimeoutTime" BU_SG_REL_ CIOM SG_ 2566337698 LECM_AlClkSetAl_GRqst_SetMin 3000;
BA_REL_ "GenSigFirstTimeoutTime" BU_SG_REL_ CIOM SG_ 2566337698 LECM_AlClkSnze_GRqst_Action 12000;
BA_REL_ "GenSigTimeoutTime" BU_SG_REL_ CIOM SG_ 2566337698 LECM_AlClkSnze_GRqst_Action 3000;
BA_REL_ "GenSigFirstTimeoutTime" BU_SG_REL_ CIOM SG_ 2489730210 BunkH1AudioSrcSem_rqst 3000;
BA_REL_ "GenSigTimeoutTime" BU_SG_REL_ CIOM SG_ 2489730210 BunkH1AudioSrcSem_rqst 300;
BA_REL_ "GenSigFirstTimeoutTime" BU_SG_REL_ CIOM SG_ 2489730210 CMSOnOffRqst 3000;
BA_REL_ "GenSigTimeoutTime" BU_SG_REL_ CIOM SG_ 2489730210 CMSOnOffRqst 300;
BA_REL_ "GenSigFirstTimeoutTime" BU_SG_REL_ CIOM SG_ 2432693154 BunkH1Prev_ButtonStatus 3000;
BA_REL_ "GenSigTimeoutTime" BU_SG_REL_ CIOM SG_ 2432693154 BunkH1Prev_ButtonStatus 60;
BA_REL_ "GenSigFirstTimeoutTime" BU_SG_REL_ CIOM SG_ 2432693154 BunkH1RoofhatchOpenBtn_Stat 3000;
BA_REL_ "GenSigTimeoutTime" BU_SG_REL_ CIOM SG_ 2432693154 BunkH1RoofhatchOpenBtn_Stat 60;
BA_REL_ "GenSigFirstTimeoutTime" BU_SG_REL_ CIOM SG_ 2432693154 BunkH1IntLghtActvnBtn_stat 3000;
BA_REL_ "GenSigTimeoutTime" BU_SG_REL_ CIOM SG_ 2432693154 BunkH1IntLghtActvnBtn_stat 60;
BA_REL_ "GenSigFirstTimeoutTime" BU_SG_REL_ CIOM SG_ 2432693154 BunkH1AudioSource_rqst 3000;
BA_REL_ "GenSigTimeoutTime" BU_SG_REL_ CIOM SG_ 2432693154 BunkH1AudioSource_rqst 60;
BA_REL_ "GenSigFirstTimeoutTime" BU_SG_REL_ CCM SG_ 2432693154 BunkH1TempDec_ButtonStatus 3000;
BA_REL_ "GenSigTimeoutTime" BU_SG_REL_ CCM SG_ 2432693154 BunkH1TempDec_ButtonStatus 60;
BA_REL_ "GenSigFirstTimeoutTime" BU_SG_REL_ CIOM SG_ 2432693154 BunkH1IntLghtDirAccsUpBtn_stat 3000;
BA_REL_ "GenSigTimeoutTime" BU_SG_REL_ CIOM SG_ 2432693154 BunkH1IntLghtDirAccsUpBtn_stat 60;
BA_REL_ "GenSigFirstTimeoutTime" BU_SG_REL_ CIOM SG_ 2432693154 BunkH1RoofhatchCloseBtn_Stat 3000;
BA_REL_ "GenSigTimeoutTime" BU_SG_REL_ CIOM SG_ 2432693154 BunkH1RoofhatchCloseBtn_Stat 60;
BA_REL_ "GenSigFirstTimeoutTime" BU_SG_REL_ CIOM SG_ 2432693154 BunkH1VolumeDown_ButtonStatus 3000;
BA_REL_ "GenSigTimeoutTime" BU_SG_REL_ CIOM SG_ 2432693154 BunkH1VolumeDown_ButtonStatus 60;
BA_REL_ "GenSigFirstTimeoutTime" BU_SG_REL_ CIOM SG_ 2432693154 BunkH1PowerWinCloseDSBtn_stat 3000;
BA_REL_ "GenSigTimeoutTime" BU_SG_REL_ CIOM SG_ 2432693154 BunkH1PowerWinCloseDSBtn_stat 500;
BA_REL_ "GenSigFirstTimeoutTime" BU_SG_REL_ CIOM SG_ 2432693154 BunkH1Next_ButtonStatus 3000;
BA_REL_ "GenSigTimeoutTime" BU_SG_REL_ CIOM SG_ 2432693154 BunkH1Next_ButtonStatus 60;
BA_REL_ "GenSigFirstTimeoutTime" BU_SG_REL_ CIOM SG_ 2432693154 BunkH1UnlockButtonStatus 3000;
BA_REL_ "GenSigTimeoutTime" BU_SG_REL_ CIOM SG_ 2432693154 BunkH1UnlockButtonStatus 60;
BA_REL_ "GenSigFirstTimeoutTime" BU_SG_REL_ CCM SG_ 2432693154 BunkH1ParkHeaterTimer2_cmd 3000;
BA_REL_ "GenSigTimeoutTime" BU_SG_REL_ CCM SG_ 2432693154 BunkH1ParkHeaterTimer2_cmd 60;
BA_REL_ "GenSigFirstTimeoutTime" BU_SG_REL_ CIOM SG_ 2432693154 BunkH1AudioOnOff_ButtonStatus 3000;
BA_REL_ "GenSigTimeoutTime" BU_SG_REL_ CIOM SG_ 2432693154 BunkH1AudioOnOff_ButtonStatus 60;
BA_REL_ "GenSigFirstTimeoutTime" BU_SG_REL_ CIOM SG_ 2432693154 BunkH1PowerWinOpenDSBtn_stat 3000;
BA_REL_ "GenSigTimeoutTime" BU_SG_REL_ CIOM SG_ 2432693154 BunkH1PowerWinOpenDSBtn_stat 500;
BA_REL_ "GenSigFirstTimeoutTime" BU_SG_REL_ CCM SG_ 2432693154 BunkH1ParkHeater_ButtonStatus 3000;
BA_REL_ "GenSigTimeoutTime" BU_SG_REL_ CCM SG_ 2432693154 BunkH1ParkHeater_ButtonStatus 60;
BA_REL_ "GenSigFirstTimeoutTime" BU_SG_REL_ CIOM SG_ 2432693154 BunkH1VolumeUp_ButtonStatus 3000;
BA_REL_ "GenSigTimeoutTime" BU_SG_REL_ CIOM SG_ 2432693154 BunkH1VolumeUp_ButtonStatus 60;
BA_REL_ "GenSigFirstTimeoutTime" BU_SG_REL_ CCM SG_ 2432693154 BunkH1ParkHeaterTimer3_cmd 3000;
BA_REL_ "GenSigTimeoutTime" BU_SG_REL_ CCM SG_ 2432693154 BunkH1ParkHeaterTimer3_cmd 60;
BA_REL_ "GenSigFirstTimeoutTime" BU_SG_REL_ CIOM SG_ 2432693154 BunkH1Mute_ButtonStatus 3000;
BA_REL_ "GenSigTimeoutTime" BU_SG_REL_ CIOM SG_ 2432693154 BunkH1Mute_ButtonStatus 60;
BA_REL_ "GenSigFirstTimeoutTime" BU_SG_REL_ CIOM SG_ 2432693154 BunkH1IntLghtDirAccsDnBtn_stat 3000;
BA_REL_ "GenSigTimeoutTime" BU_SG_REL_ CIOM SG_ 2432693154 BunkH1IntLghtDirAccsDnBtn_stat 60;
BA_REL_ "GenSigFirstTimeoutTime" BU_SG_REL_ CIOM SG_ 2432693154 BunkH1LockButtonStatus 3000;
BA_REL_ "GenSigTimeoutTime" BU_SG_REL_ CIOM SG_ 2432693154 BunkH1LockButtonStatus 60;
BA_REL_ "GenSigFirstTimeoutTime" BU_SG_REL_ CCM SG_ 2432693154 BunkH1ParkHeaterTimer1_cmd 3000;
BA_REL_ "GenSigTimeoutTime" BU_SG_REL_ CCM SG_ 2432693154 BunkH1ParkHeaterTimer1_cmd 60;
BA_REL_ "GenSigFirstTimeoutTime" BU_SG_REL_ CIOM SG_ 2432693154 BnkH1IntLghtMMenu_stat_IL_Mode 3000;
BA_REL_ "GenSigTimeoutTime" BU_SG_REL_ CIOM SG_ 2432693154 BnkH1IntLghtMMenu_stat_IL_Mode 60;
BA_REL_ "GenSigFirstTimeoutTime" BU_SG_REL_ CIOM SG_ 2432693154 BunkH1AudioSource_rqst2 3000;
BA_REL_ "GenSigTimeoutTime" BU_SG_REL_ CIOM SG_ 2432693154 BunkH1AudioSource_rqst2 60;
BA_REL_ "GenSigFirstTimeoutTime" BU_SG_REL_ CIOM SG_ 2432693154 BnkH1IntLghtMMenu_stat_EventFlag 3000;
BA_REL_ "GenSigTimeoutTime" BU_SG_REL_ CIOM SG_ 2432693154 BnkH1IntLghtMMenu_stat_EventFlag 60;
BA_REL_ "GenSigFirstTimeoutTime" BU_SG_REL_ CIOM SG_ 2432693154 BunkH1PowerWinOpenPSBtn_stat 3000;
BA_REL_ "GenSigTimeoutTime" BU_SG_REL_ CIOM SG_ 2432693154 BunkH1PowerWinOpenPSBtn_stat 500;
BA_REL_ "GenSigFirstTimeoutTime" BU_SG_REL_ CIOM SG_ 2432693154 BunkH1PowerWinClosePSBtn_stat 3000;
BA_REL_ "GenSigTimeoutTime" BU_SG_REL_ CIOM SG_ 2432693154 BunkH1PowerWinClosePSBtn_stat 500;
BA_REL_ "GenSigFirstTimeoutTime" BU_SG_REL_ CCM SG_ 2432693154 BunkH1TempInc_ButtonStatus 3000;
BA_REL_ "GenSigTimeoutTime" BU_SG_REL_ CCM SG_ 2432693154 BunkH1TempInc_ButtonStatus 60;
BA_REL_ "GenSigFirstTimeoutTime" BU_SG_REL_ CIOM SG_ 2499790739 CMSFailureStat_SqC 3000;
BA_REL_ "GenSigTimeoutTime" BU_SG_REL_ CIOM SG_ 2499790739 CMSFailureStat_SqC 3000;
BA_REL_ "GenSigFirstTimeoutTime" BU_SG_REL_ CIOM SG_ 2499790739 CMSFailureStat_Status 3000;
BA_REL_ "GenSigTimeoutTime" BU_SG_REL_ CIOM SG_ 2499790739 CMSFailureStat_Status 3000;
BA_REL_ "GenSigFirstTimeoutTime" BU_SG_REL_ CIOM SG_ 2499790739 CMSFailureStat_CRC 3000;
BA_REL_ "GenSigTimeoutTime" BU_SG_REL_ CIOM SG_ 2499790739 CMSFailureStat_CRC 3000;
BA_REL_ "GenSigFirstTimeoutTime" BU_SG_REL_ CIOM SG_ 2499790995 CMSManualAlignmStat_CRC 3000;
BA_REL_ "GenSigTimeoutTime" BU_SG_REL_ CIOM SG_ 2499790995 CMSManualAlignmStat_CRC 3000;
BA_REL_ "GenSigFirstTimeoutTime" BU_SG_REL_ LECM1 SG_ 2499790995 CMSActvtnDeactvtnStat_Status 3000;
BA_REL_ "GenSigTimeoutTime" BU_SG_REL_ LECM1 SG_ 2499790995 CMSActvtnDeactvtnStat_Status 300;
BA_REL_ "GenSigFirstTimeoutTime" BU_SG_REL_ CIOM SG_ 2499790995 CMSActvtnDeactvtnStat_Status 3000;
BA_REL_ "GenSigTimeoutTime" BU_SG_REL_ CIOM SG_ 2499790995 CMSActvtnDeactvtnStat_Status 3000;
BA_REL_ "GenSigFirstTimeoutTime" BU_SG_REL_ CIOM SG_ 2499790995 CMSZoomStat_Status 3000;
BA_REL_ "GenSigTimeoutTime" BU_SG_REL_ CIOM SG_ 2499790995 CMSZoomStat_Status 3000;
BA_REL_ "GenSigFirstTimeoutTime" BU_SG_REL_ CIOM SG_ 2499790995 CMSZoomStat_SqC 3000;
BA_REL_ "GenSigTimeoutTime" BU_SG_REL_ CIOM SG_ 2499790995 CMSZoomStat_SqC 3000;
BA_REL_ "GenSigFirstTimeoutTime" BU_SG_REL_ CIOM SG_ 2499790995 CMSFoldingStat_CRC 3000;
BA_REL_ "GenSigTimeoutTime" BU_SG_REL_ CIOM SG_ 2499790995 CMSFoldingStat_CRC 3000;
BA_REL_ "GenSigFirstTimeoutTime" BU_SG_REL_ LECM1 SG_ 2499790995 CMSActvtnDeactvtnStat_SqC 3000;
BA_REL_ "GenSigTimeoutTime" BU_SG_REL_ LECM1 SG_ 2499790995 CMSActvtnDeactvtnStat_SqC 300;
BA_REL_ "GenSigFirstTimeoutTime" BU_SG_REL_ CIOM SG_ 2499790995 CMSActvtnDeactvtnStat_SqC 3000;
BA_REL_ "GenSigTimeoutTime" BU_SG_REL_ CIOM SG_ 2499790995 CMSActvtnDeactvtnStat_SqC 3000;
BA_REL_ "GenSigFirstTimeoutTime" BU_SG_REL_ CIOM SG_ 2499790995 CMSFoldingStat_Status 3000;
BA_REL_ "GenSigTimeoutTime" BU_SG_REL_ CIOM SG_ 2499790995 CMSFoldingStat_Status 3000;
BA_REL_ "GenSigFirstTimeoutTime" BU_SG_REL_ CIOM SG_ 2499790995 CMSManualAlignmStat_Status 3000;
BA_REL_ "GenSigTimeoutTime" BU_SG_REL_ CIOM SG_ 2499790995 CMSManualAlignmStat_Status 3000;
BA_REL_ "GenSigFirstTimeoutTime" BU_SG_REL_ CIOM SG_ 2499790995 CMSManualAlignmStat_SqC 3000;
BA_REL_ "GenSigTimeoutTime" BU_SG_REL_ CIOM SG_ 2499790995 CMSManualAlignmStat_SqC 3000;
BA_REL_ "GenSigFirstTimeoutTime" BU_SG_REL_ CIOM SG_ 2499790995 CMSFoldingStat_SqC 3000;
BA_REL_ "GenSigTimeoutTime" BU_SG_REL_ CIOM SG_ 2499790995 CMSFoldingStat_SqC 3000;
BA_REL_ "GenSigFirstTimeoutTime" BU_SG_REL_ CIOM SG_ 2499790995 CMSZoomStat_CRC 3000;
BA_REL_ "GenSigTimeoutTime" BU_SG_REL_ CIOM SG_ 2499790995 CMSZoomStat_CRC 3000;
BA_REL_ "GenSigFirstTimeoutTime" BU_SG_REL_ CIOM SG_ 2499790995 CMSActvtnDeactvtnStat_CRC 3000;
BA_REL_ "GenSigTimeoutTime" BU_SG_REL_ CIOM SG_ 2499790995 CMSActvtnDeactvtnStat_CRC 3000;
BA_REL_ "GenSigFirstTimeoutTime" BU_SG_REL_ LECM1 SG_ 2499790995 CMSActvtnDeactvtnStat_CRC 3000;
BA_REL_ "GenSigTimeoutTime" BU_SG_REL_ LECM1 SG_ 2499790995 CMSActvtnDeactvtnStat_CRC 300;
VAL_ 2499772198 TipperTarpaulinRequest 7 "CoverUncoverRqst_NotAvailable" 6 "CoverUncoverRqst_Error" 5 "CoverUncoverRqst_Spare3" 4 "CoverUncoverRqst_Spare2" 3 "CoverUncoverRqst_Spare1" 2 "CoverUncoverRqst_Uncover" 1 "CoverUncoverRqst_Cover" 0 "CoverUncoverRqst_NoRequest" ;
VAL_ 2499772198 TipperUpDownRequest 7 "UpDown_NotAvailable" 6 "UpDown_Error" 5 "UpDown_Spare2" 4 "UpDown_Spare1" 3 "UpDown_RequestDownAuto" 2 "UpDown_RequestDown" 1 "UpDown_RequestUp" 0 "UpDown_NoRequest" ;
VAL_ 2499772198 TailLiftMotionRequest 7 "RqstTiltUpDown_NotAvailable" 6 "RqstTiltUpDown_Error" 5 "RqstTiltUpDown_Spare" 4 "RqstTiltUpDown_TiltDown" 3 "RqstTiltUpDown_TiltUp" 2 "RqstTiltUpDown_RequestDown" 1 "RqstTiltUpDown_RequestUp" 0 "RqstTiltUpDown_NoRequest" ;
VAL_ 2499772198 TipperEmergencyStop 3 "StopRqst_NotAvailable" 2 "StopRqst_Error" 1 "StopRqst_Stop" 0 "StopRqst_NoRequest" ;
VAL_ 2499772198 ExtraBbWrcWatchdog 3 "LowHigh_NotAvailable" 2 "LowHigh_Error" 1 "LowHigh_High" 0 "LowHigh_Low" ;
VAL_ 2499772198 TipperTailGateRequest 7 "OpenCloseRqst_NotAvailable" 6 "OpenCloseRqst_Error" 5 "OpenCloseRqst_Spare3" 4 "OpenCloseRqst_Spare2" 3 "OpenCloseRqst_Spare1" 2 "OpenCloseRqst_Close" 1 "OpenCloseRqst_Open" 0 "OpenCloseRqst_NoRequest" ;
VAL_ 2499772198 TipperTippingBodySelection 3 "PrimarySecondary_NotAvailable" 2 "PrimarySecondary_Error" 1 "PrimarySecondary_Secondary" 0 "PrimarySecondary_Primary" ;
VAL_ 2499772198 TipperShakerRequest 3 "ShakeRqst_NotAvailable" 2 "ShakeRqst_Error" 1 "ShakeRqst_Shake" 0 "ShakeRqst_NoRequest" ;
VAL_ 2432679743 WRC5thWheelRequest 3 "PushButtonStatus_NotAvailable" 2 "PushButtonStatus_Error" 1 "PushButtonStatus_Pushed" 0 "PushButtonStatus_Neutral" ;
VAL_ 2432679743 WRC_Docking_stat 3 "Docking_stat_NotAvailable" 2 "Docking_stat_Error" 1 "Docking_stat_Docked" 0 "Docking_stat_Undocked" ;
VAL_ 2432679743 WRCLevelUserMemoryAction 7 "LevelUserMemoryAction_NotAvailable" 6 "LevelUserMemoryAction_Error" 5 "LevelUserMemoryAction_Reserved_01" 4 "LevelUserMemoryAction_Reserved" 3 "LevelUserMemoryAction_Default" 2 "LevelUserMemoryAction_Store" 1 "LevelUserMemoryAction_Recall" 0 "LevelUserMemoryAction_Inactive" ;
VAL_ 2432679743 WRCLevelUserMemory 15 "LevelUserMemory_NotAvailable" 14 "LevelUserMemory_Error" 13 "LevelUserMemory_Spare05" 12 "LevelUserMemory_Spare04" 11 "LevelUserMemory_Spare03" 10 "LevelUserMemory_Spare02" 9 "LevelUserMemory_Spare01" 8 "LevelUserMemory_Spare" 7 "LevelUserMemory_M7" 6 "LevelUserMemory_M6" 5 "LevelUserMemory_M5" 4 "LevelUserMemory_M4" 3 "LevelUserMemory_M3" 2 "LevelUserMemory_M2" 1 "LevelUserMemory_M1" 0 "LevelUserMemory_NotUsed" ;
VAL_ 2432679743 WrcEngSpdCtrlResumeButtonStat 3 "ButtonStatus_NotAvailable" 2 "ButtonStatus_Error" 1 "ButtonStatus_Pressed" 0 "ButtonStatus_Idle" ;
VAL_ 2432679743 WRCBeaconRequest 3 "PushButtonStatus_NotAvailable" 2 "PushButtonStatus_Error" 1 "PushButtonStatus_Pushed" 0 "PushButtonStatus_Neutral" ;
VAL_ 2432679743 WrcEngSpdCtrlDecreaseButtStat 3 "ButtonStatus_NotAvailable" 2 "ButtonStatus_Error" 1 "ButtonStatus_Pressed" 0 "ButtonStatus_Idle" ;
VAL_ 2432679743 WRCEngineStartRequest 3 "PushButtonStatus_NotAvailable" 2 "PushButtonStatus_Error" 1 "PushButtonStatus_Pushed" 0 "PushButtonStatus_Neutral" ;
VAL_ 2432679743 WrcEngSpdCtrlEnableStatus 3 "DisableEnable_NotAvailable" 2 "DisableEnable_Error" 1 "DisableEnable_Enable" 0 "DisableEnable_Disable" ;
VAL_ 2432679743 WRCCabBodyWLightsRqst 3 "PushButtonStatus_NotAvailable" 2 "PushButtonStatus_Error" 1 "PushButtonStatus_Pushed" 0 "PushButtonStatus_Neutral" ;
VAL_ 2432679743 WRCEngineStopRequest 3 "PushButtonStatus_NotAvailable" 2 "PushButtonStatus_Error" 1 "PushButtonStatus_Pushed" 0 "PushButtonStatus_Neutral" ;
VAL_ 2432679743 WrcEngSpdCtrlIncreaseButtStat 3 "ButtonStatus_NotAvailable" 2 "ButtonStatus_Error" 1 "ButtonStatus_Pressed" 0 "ButtonStatus_Idle" ;
VAL_ 2365554559 WrcPto1ButtonStatus 3 "ButtonStatus_NotAvailable" 2 "ButtonStatus_Error" 1 "ButtonStatus_Pressed" 0 "ButtonStatus_Idle" ;
VAL_ 2365554559 ECSStandByReqWRC 7 "ECSStandByReq_NotAvailable" 6 "ECSStandByReq_Error" 5 "ECSStandByReq_Reserved_02" 4 "ECSStandByReq_Reserved_01" 3 "ECSStandByReq_Reserved" 2 "ECSStandByReq_StopStandby" 1 "ECSStandByReq_StandbyRequested" 0 "ECSStandByReq_Idle" ;
VAL_ 2365554559 WRCCraneRequest 3 "PushButtonStatus_NotAvailable" 2 "PushButtonStatus_Error" 1 "PushButtonStatus_Pushed" 0 "PushButtonStatus_Neutral" ;
VAL_ 2365554559 WRCUnlockButtonStatus 3 "PushButtonStatus_NotAvailable" 2 "PushButtonStatus_Error" 1 "PushButtonStatus_Pushed" 0 "PushButtonStatus_Neutral" ;
VAL_ 2365554559 WRCRollRequest 7 "RollRequest_NotAvailable" 6 "RollRequest_Error" 5 "RollRequest_Reserved" 4 "RollRequest_CounterClockwiseShort" 3 "RollRequest_ClockwiseShort" 2 "RollRequest_CounterClockwise" 1 "RollRequest_Clockwise" 0 "RollRequest_Idle" ;
VAL_ 2365554559 WRCAux3Request 3 "OffOn_NotAvailable" 2 "OffOn_Error" 1 "OffOn_On" 0 "OffOn_Off" ;
VAL_ 2365554559 WRCAux2Request 3 "OffOn_NotAvailable" 2 "OffOn_Error" 1 "OffOn_On" 0 "OffOn_Off" ;
VAL_ 2365554559 WrcPto3ButtonStatus 3 "ButtonStatus_NotAvailable" 2 "ButtonStatus_Error" 1 "ButtonStatus_Pressed" 0 "ButtonStatus_Idle" ;
VAL_ 2365554559 WRCLevelAdjustmentAction 15 "LevelAdjustmentAction_NotAvailable" 14 "LevelAdjustmentAction_Error" 13 "LevelAdjustmentAction_Reserved_06" 12 "LevelAdjustmentAction_Reserved_05" 11 "LevelAdjustmentAction_Reserved_04" 10 "LevelAdjustmentAction_Reserved_03" 9 "LevelAdjustmentAction_Reserved_02" 8 "LevelAdjustmentAction_Ferry" 7 "LevelAdjustmentAction_Reserved_01" 6 "LevelAdjustmentAction_GotoDriveLevel" 5 "LevelAdjustmentAction_Reserved" 4 "LevelAdjustmentAction_DownShortMovement" 3 "LevelAdjustmentAction_UpShortMovement" 2 "LevelAdjustmentAction_DownBasic" 1 "LevelAdjustmentAction_UpBasic" 0 "LevelAdjustmentAction_Idle" ;
VAL_ 2365554559 WRCAux4Request 3 "OffOn_NotAvailable" 2 "OffOn_Error" 1 "OffOn_On" 0 "OffOn_Off" ;
VAL_ 2365554559 WRCAux5Request 3 "OffOn_NotAvailable" 2 "OffOn_Error" 1 "OffOn_On" 0 "OffOn_Off" ;
VAL_ 2365554559 WRCAux6Request 3 "OffOn_NotAvailable" 2 "OffOn_Error" 1 "OffOn_On" 0 "OffOn_Off" ;
VAL_ 2365554559 WRCSideReverseWorkingRequest 3 "PushButtonStatus_NotAvailable" 2 "PushButtonStatus_Error" 1 "PushButtonStatus_Pushed" 0 "PushButtonStatus_Neutral" ;
VAL_ 2365554559 WrcPto2ButtonStatus 3 "ButtonStatus_NotAvailable" 2 "ButtonStatus_Error" 1 "ButtonStatus_Pressed" 0 "ButtonStatus_Idle" ;
VAL_ 2365554559 WRCTailLiftRequest 3 "PushButtonStatus_NotAvailable" 2 "PushButtonStatus_Error" 1 "PushButtonStatus_Pushed" 0 "PushButtonStatus_Neutral" ;
VAL_ 2365554559 WrcPto4ButtonStatus 3 "ButtonStatus_NotAvailable" 2 "ButtonStatus_Error" 1 "ButtonStatus_Pressed" 0 "ButtonStatus_Idle" ;
VAL_ 2365554559 WRCLevelAdjustmentStroke 7 "LevelAdjustmentStroke_NotAvailable" 6 "LevelAdjustmentStroke_Error" 5 "LevelAdjustmentStroke_Reserved_03" 4 "LevelAdjustmentStroke_Reserved_02" 3 "LevelAdjustmentStroke_Reserved_01" 2 "LevelAdjustmentStroke_Reserved" 1 "LevelAdjustmentStroke_DockingStroke" 0 "LevelAdjustmentStroke_DriveStroke" ;
VAL_ 2365554559 WRCLevelAdjustmentAxles 7 "LevelAdjustmentAxles_NotAvailable" 6 "LevelAdjustmentAxles_Error" 5 "LevelAdjustmentAxles_Reserved_02" 4 "LevelAdjustmentAxles_Reserved_01" 3 "LevelAdjustmentAxles_Reserved" 2 "LevelAdjustmentAxles_Parallel" 1 "LevelAdjustmentAxles_Front" 0 "LevelAdjustmentAxles_Rear" ;
VAL_ 2365554559 WRCAirSuspensionStopRequest 3 "FalseTrue_NotAvaiable" 2 "FalseTrue_Error" 1 "FalseTrue_True" 0 "FalseTrue_False" ;
VAL_ 2365554559 WRCAux1Request 3 "OffOn_NotAvailable" 2 "OffOn_Error" 1 "OffOn_On" 0 "OffOn_Off" ;
VAL_ 2365554559 WRCLockButtonStatus 3 "PushButtonStatus_NotAvailable" 2 "PushButtonStatus_Error" 1 "PushButtonStatus_Pushed" 0 "PushButtonStatus_Neutral" ;
VAL_ 2516576083 TrafficAccidentStat_Status 3 "NotDetected_NotAvaliable" 2 "NotDetected_Error" 1 "NotDetected_Detected" 0 "NotDetected_NotDetected" ;
VAL_ 2432689747 SideColliAccidentStat_RightSide 7 "RightSideCrashStatus_NotAvailable" 6 "RightSideCrashStatus_Error" 5 "RightSideCrashStatus_Reserved3" 4 "RightSideCrashStatus_Reserved2" 3 "RightSideCrashStatus_Reserved1" 2 "RightSideCrashStatus_Level2RightSideCrashDetected" 1 "RightSideCrashStatus_Level1RightSideCrashDetected" 0 "RightSideCrashStatus_NoRightSideCrashDetected" ;
VAL_ 2432689747 SideColliAccidentStat_LeftSide 7 "LeftSideCrashStatus_NotAvailable" 6 "LeftSideCrashStatus_Error" 5 "LeftSideCrashStatus_Reserved3" 4 "LeftSideCrashStatus_Reserved2" 3 "LeftSideCrashStatus_Reserved1" 2 "LeftSideCrashStatus_Level2LeftSideCrashDetected" 1 "LeftSideCrashStatus_Level1LeftSideCrashDetected" 0 "LeftSideCrashStatus_NoLeftSideCrashDetected" ;
VAL_ 2499788607 TrafficAccIntlightReq 3 "NotRequested_NotAvailable" 2 "NotRequested_Error" 1 "NotRequested_Requested" 0 "NotRequested_NotRequested" ;
VAL_ 2499788607 TrafficAccShutDownReq_Rqst 3 "Request_NotAvailable" 2 "Request_Error" 1 "Request_RequestActive" 0 "Request_NotRequested" ;
VAL_ 2432689491 SRSWarningLamp 3 "OffOnSpare_NotAvailable" 2 "OffOnSpare_Spare" 1 "OffOnSpare_On" 0 "OffOnSpare_Off" ;
VAL_ 2432689491 RollOverAccidentStatus 3 "RollOverAccidentStatus_NotAvailable" 2 "RollOverAccidentStatus_Error" 1 "RollOverAccidentStatus_RollOverAccidentDetected" 0 "RollOverAccidentStatus_NoRollOverAccidentDetected" ;
VAL_ 2432689491 SRSAirbagStatus 3 "SRSAirbagStatus_NotAvailable" 2 "SRSAirbagStatus_ErrorIndicator" 1 "SRSAirbagStatus_DriverAirbagDeployed" 0 "SRSAirbagStatus_NoAirbagDeployed" ;
VAL_ 2432689491 EmergencyDoorsUnlock_rqst 7 "EmergencyDoorsUnlock_rqst_NotAvailable" 6 "EmergencyDoorsUnlock_rqst_Error" 2 "EmergencyDoorsUnlock_rqst_EmergencyUnlockRequest" 1 "EmergencyDoorsUnlock_rqst_Spare" 0 "EmergencyDoorsUnlock_rqst_Idle" ;
VAL_ 2432689491 TrafficAccidentHazardLightRqst 3 "Request_NotAvailable" 2 "Request_Error" 1 "Request_RequestActive" 0 "Request_NotRequested" ;
VAL_ 2432689491 FrontalCollisionAccidentStatus 3 "NotDetected_NotAvaliable" 2 "NotDetected_Error" 1 "NotDetected_Detected" 0 "NotDetected_NotDetected" ;
VAL_ 2549208482 LECM_Ent_UpDown_WheelStatus 15 "FreeWheel_Status_NotAvailable" 14 "FreeWheel_Status_Error" 13 "FreeWheel_Status_Spare" 12 "FreeWheel_Status_6StepsCounterClockwise" 11 "FreeWheel_Status_5StepsCounterClockwise" 10 "FreeWheel_Status_4StepsCounterClockwise" 9 "FreeWheel_Status_3StepsCounterClockwise" 8 "FreeWheel_Status_2StepsCounterClockwise" 7 "FreeWheel_Status_1StepCounterClockwise" 6 "FreeWheel_Status_6StepsClockwise" 5 "FreeWheel_Status_5StepsClockwise" 4 "FreeWheel_Status_4StepsClockwise" 3 "FreeWheel_Status_3StepsClockwise" 2 "FreeWheel_Status_2StepsClockwise" 1 "FreeWheel_Status_1StepClockwise" 0 "FreeWheel_Status_NoMovement" ;
VAL_ 2549208482 LECM_IntLight_SlprMaxLight_BS 3 "PushButtonStatus_NotAvailable" 2 "PushButtonStatus_Error" 1 "PushButtonStatus_Pushed" 0 "PushButtonStatus_Neutral" ;
VAL_ 2549208482 LECM_CabClim_Pwr_BtnStat 3 "PushButtonStatus_NotAvailable" 2 "PushButtonStatus_Error" 1 "PushButtonStatus_Pushed" 0 "PushButtonStatus_Neutral" ;
VAL_ 2549208482 LECM_LockControl_Lock_BtnStat 3 "PushButtonStatus_NotAvailable" 2 "PushButtonStatus_Error" 1 "PushButtonStatus_Pushed" 0 "PushButtonStatus_Neutral" ;
VAL_ 2549208482 LECM_CabClim_Auto_BtnStat 3 "PushButtonStatus_NotAvailable" 2 "PushButtonStatus_Error" 1 "PushButtonStatus_Pushed" 0 "PushButtonStatus_Neutral" ;
VAL_ 2549208482 LECM_CabClim_AC_BtnStat 3 "PushButtonStatus_NotAvailable" 2 "PushButtonStatus_Error" 1 "PushButtonStatus_Pushed" 0 "PushButtonStatus_Neutral" ;
VAL_ 2549208482 LECM_CabClim_FrPwr_BtnStat 3 "PushButtonStatus_NotAvailable" 2 "PushButtonStatus_Error" 1 "PushButtonStatus_Pushed" 0 "PushButtonStatus_Neutral" ;
VAL_ 2549208482 LECM_Ent_Volume_WheelStatus 15 "FreeWheel_Status_NotAvailable" 14 "FreeWheel_Status_Error" 13 "FreeWheel_Status_Spare" 12 "FreeWheel_Status_6StepsCounterClockwise" 11 "FreeWheel_Status_5StepsCounterClockwise" 10 "FreeWheel_Status_4StepsCounterClockwise" 9 "FreeWheel_Status_3StepsCounterClockwise" 8 "FreeWheel_Status_2StepsCounterClockwise" 7 "FreeWheel_Status_1StepCounterClockwise" 6 "FreeWheel_Status_6StepsClockwise" 5 "FreeWheel_Status_5StepsClockwise" 4 "FreeWheel_Status_4StepsClockwise" 3 "FreeWheel_Status_3StepsClockwise" 2 "FreeWheel_Status_2StepsClockwise" 1 "FreeWheel_Status_1StepClockwise" 0 "FreeWheel_Status_NoMovement" ;
VAL_ 2549208482 LECMCabClimSetTempSelectGuiReq 3 "PushButtonStatus_NotAvailable" 2 "PushButtonStatus_Error" 1 "PushButtonStatus_Pushed" 0 "PushButtonStatus_Neutral" ;
VAL_ 2549208482 LECM_IntLight_SlprAmbLow_BS 3 "PushButtonStatus_NotAvailable" 2 "PushButtonStatus_Error" 1 "PushButtonStatus_Pushed" 0 "PushButtonStatus_Neutral" ;
VAL_ 2549208482 LECM_CabClim_MaxDef_GuiReq 3 "PushButtonStatus_NotAvailable" 2 "PushButtonStatus_Error" 1 "PushButtonStatus_Pushed" 0 "PushButtonStatus_Neutral" ;
VAL_ 2549208482 LECM_CabClim_Fan_WheelStatus 15 "FreeWheel_Status_NotAvailable" 14 "FreeWheel_Status_Error" 13 "FreeWheel_Status_Spare" 12 "FreeWheel_Status_6StepsCounterClockwise" 11 "FreeWheel_Status_5StepsCounterClockwise" 10 "FreeWheel_Status_4StepsCounterClockwise" 9 "FreeWheel_Status_3StepsCounterClockwise" 8 "FreeWheel_Status_2StepsCounterClockwise" 7 "FreeWheel_Status_1StepCounterClockwise" 6 "FreeWheel_Status_6StepsClockwise" 5 "FreeWheel_Status_5StepsClockwise" 4 "FreeWheel_Status_4StepsClockwise" 3 "FreeWheel_Status_3StepsClockwise" 2 "FreeWheel_Status_2StepsClockwise" 1 "FreeWheel_Status_1StepClockwise" 0 "FreeWheel_Status_NoMovement" ;
VAL_ 2549208482 LECM_IntLight_SlprAmbUpp_BS 3 "PushButtonStatus_NotAvailable" 2 "PushButtonStatus_Error" 1 "PushButtonStatus_Pushed" 0 "PushButtonStatus_Neutral" ;
VAL_ 2549208482 LECM_Ent_AudioSettingsViewSts 15 "EntAudioSettingsViewStatus_NotAvailable" 14 "EntAudioSettingsViewStatus_Error" 13 "EntAudioSettingsViewStatus_SIDReferenceViewActive" 12 "EntAudioSettingsViewStatus_Spare12" 11 "EntAudioSettingsViewStatus_Spare11" 10 "EntAudioSettingsViewStatus_Spare10" 9 "EntAudioSettingsViewStatus_Spare9" 8 "EntAudioSettingsViewStatus_Spare8" 7 "EntAudioSettingsViewStatus_Spare7" 6 "EntAudioSettingsViewStatus_Spare6" 5 "EntAudioSettingsViewStatus_MidViewActive" 4 "EntAudioSettingsViewStatus_FaderViewActive" 3 "EntAudioSettingsViewStatus_BalanceViewActive" 2 "EntAudioSettingsViewStatus_TrebleViewActive" 1 "EntAudioSettingsViewStatus_BassViewActive" 0 "EntAudioSettingsViewStatus_ViewNotActive" ;
VAL_ 2549208482 LECM_Panic_CMS_BtnStat 3 "PushButtonStatus_NotAvailable" 2 "PushButtonStatus_Error" 1 "PushButtonStatus_Pushed" 0 "PushButtonStatus_Neutral" ;
VAL_ 2549208482 LECM_CabClim_Sync_GuiReq 3 "PushButtonStatus_NotAvailable" 2 "PushButtonStatus_Error" 1 "PushButtonStatus_Pushed" 0 "PushButtonStatus_Neutral" ;
VAL_ 2549208482 LecmCutOffAnswerGuiRqst 3 "CutOffAnswerGuiRqst_NotAvailable" 2 "CutOffAnswerGuiRqst_Delay" 1 "CutOffAnswerGuiRqst_Accept" 0 "CutOffAnswerGuiRqst_NoAnswer" ;
VAL_ 2549208482 LECM_Ent_MediaSource_BtnStat 3 "PushButtonStatus_NotAvailable" 2 "PushButtonStatus_Error" 1 "PushButtonStatus_Pushed" 0 "PushButtonStatus_Neutral" ;
VAL_ 2549208482 LECM_CabClim_Temp_WheelStatus 15 "FreeWheel_Status_NotAvailable" 14 "FreeWheel_Status_Error" 13 "FreeWheel_Status_Spare" 12 "FreeWheel_Status_6StepsCounterClockwise" 11 "FreeWheel_Status_5StepsCounterClockwise" 10 "FreeWheel_Status_4StepsCounterClockwise" 9 "FreeWheel_Status_3StepsCounterClockwise" 8 "FreeWheel_Status_2StepsCounterClockwise" 7 "FreeWheel_Status_1StepCounterClockwise" 6 "FreeWheel_Status_6StepsClockwise" 5 "FreeWheel_Status_5StepsClockwise" 4 "FreeWheel_Status_4StepsClockwise" 3 "FreeWheel_Status_3StepsClockwise" 2 "FreeWheel_Status_2StepsClockwise" 1 "FreeWheel_Status_1StepClockwise" 0 "FreeWheel_Status_NoMovement" ;
VAL_ 2549208482 LECM_Power_Inverter_BtnStat 3 "PushButtonStatus_NotAvailable" 2 "PushButtonStatus_Error" 1 "PushButtonStatus_Pushed" 0 "PushButtonStatus_Neutral" ;
VAL_ 2549208482 LECM_Ent_SkpLeft_BtnStat 3 "PushButtonStatus_NotAvailable" 2 "PushButtonStatus_Error" 1 "PushButtonStatus_Pushed" 0 "PushButtonStatus_Neutral" ;
VAL_ 2549208482 LECM_IntLight_SlprDecrease_BS 3 "PushButtonStatus_NotAvailable" 2 "PushButtonStatus_Error" 1 "PushButtonStatus_Pushed" 0 "PushButtonStatus_Neutral" ;
VAL_ 2549208482 LECM_Ent_OnOff_BtnStat 3 "PushButtonStatus_NotAvailable" 2 "PushButtonStatus_Error" 1 "PushButtonStatus_Pushed" 0 "PushButtonStatus_Neutral" ;
VAL_ 2549208482 LECM_IntLight_SlprIncrease_BS 3 "PushButtonStatus_NotAvailable" 2 "PushButtonStatus_Error" 1 "PushButtonStatus_Pushed" 0 "PushButtonStatus_Neutral" ;
VAL_ 2549208482 LECM_Ent_SkpRight_BtnStat 3 "PushButtonStatus_NotAvailable" 2 "PushButtonStatus_Error" 1 "PushButtonStatus_Pushed" 0 "PushButtonStatus_Neutral" ;
VAL_ 2566337698 LECM_Display_Navi_OK_BtnStat 3 "PushButtonStatus_NotAvailable" 2 "PushButtonStatus_Error" 1 "PushButtonStatus_Pushed" 0 "PushButtonStatus_Neutral" ;
VAL_ 2566337698 LECM_AlClkSnze_GRqst_ID 127 "AlarmClkID_NotAvailable" 126 "AlarmClkID_Error" 10 "AlarmClkID_Alarm10" 9 "AlarmClkID_Alarm9" 8 "AlarmClkID_Alarm8" 7 "AlarmClkID_Alarm7" 6 "AlarmClkID_Alarm6" 5 "AlarmClkID_Alarm5" 4 "AlarmClkID_Alarm4" 3 "AlarmClkID_Alarm3" 2 "AlarmClkID_Alarm2" 1 "AlarmClkID_Alarm1" 0 "AlarmClkID_NotUsed" ;
VAL_ 2566337698 LECM_AlClkSetAl_GRqst_Mode 3 "AlarmClkMode_Spare" 2 "AlarmClkMode_Timer" 1 "AlarmClkMode_Recurrent" 0 "AlarmClkMode_OneTime" ;
VAL_ 2566337698 LECM_AlClkSetAl_GRqst_Stat 3 "AlarmClkStat2_Snoozed" 2 "AlarmClkStat2_Ringing" 1 "AlarmClkStat2_Active" 0 "AlarmClkStat2_Inactive" ;
VAL_ 2566337698 LECM_AlClkSetAl_GRqst_ID 127 "AlarmClkID_NotAvailable" 126 "AlarmClkID_Error" 10 "AlarmClkID_Alarm10" 9 "AlarmClkID_Alarm9" 8 "AlarmClkID_Alarm8" 7 "AlarmClkID_Alarm7" 6 "AlarmClkID_Alarm6" 5 "AlarmClkID_Alarm5" 4 "AlarmClkID_Alarm4" 3 "AlarmClkID_Alarm3" 2 "AlarmClkID_Alarm2" 1 "AlarmClkID_Alarm1" 0 "AlarmClkID_NotUsed" ;
VAL_ 2566337698 LECM_Display_Navi_WheelStatus 15 "FreeWheel_Status_NotAvailable" 14 "FreeWheel_Status_Error" 13 "FreeWheel_Status_Spare" 12 "FreeWheel_Status_6StepsCounterClockwise" 11 "FreeWheel_Status_5StepsCounterClockwise" 10 "FreeWheel_Status_4StepsCounterClockwise" 9 "FreeWheel_Status_3StepsCounterClockwise" 8 "FreeWheel_Status_2StepsCounterClockwise" 7 "FreeWheel_Status_1StepCounterClockwise" 6 "FreeWheel_Status_6StepsClockwise" 5 "FreeWheel_Status_5StepsClockwise" 4 "FreeWheel_Status_4StepsClockwise" 3 "FreeWheel_Status_3StepsClockwise" 2 "FreeWheel_Status_2StepsClockwise" 1 "FreeWheel_Status_1StepClockwise" 0 "FreeWheel_Status_NoMovement" ;
VAL_ 2566337698 LECM_AlClkSetAl_GRqst_Type 7 "AlarmClkType_NotAvailable" 6 "AlarmClkType_Error" 5 "AlarmClkType_Reserved_02" 4 "AlarmClkType_Reserved_01" 3 "AlarmClkType_Light" 2 "AlarmClkType_Radio" 1 "AlarmClkType_Buzzer" 0 "AlarmClkType_NoAudibleNotification" ;
VAL_ 2566337698 LECM_AlClkSnze_GRqst_Action 7 "AlmClkSnzeAction_NotAvailable" 6 "AlmClkSnzeAction_Error" 5 "AlmClkSnzeAction_Spare02" 4 "AlmClkSnzeAction_Spare01" 3 "AlmClkSnzeAction_RequestToContinuePlay" 2 "AlmClkSnzeAction_RequestToTurnAlarmOff" 1 "AlmClkSnzeAction_RequestToSnoozeAlarm" 0 "AlmClkSnzeAction_NoRequest" ;
VAL_ 2499772322 MediaSourcesListReq_SInfo 3 "SignalInfo2bitType_NotAvailable" 2 "SignalInfo2bitType_ErrorIndication" 1 "SignalInfo2bitType_Spare" 0 "SignalInfo2bitType_Valid" ;
VAL_ 2489730210 BunkH1AudioSrcSem_rqst 15 "AudioSource_NotAvailable" 14 "AudioSource_Error" 13 "AudioSource_Source13" 12 "AudioSource_Source12" 11 "AudioSource_Source11" 10 "AudioSource_Source10" 9 "AudioSource_Source09" 8 "AudioSource_Source08" 7 "AudioSource_Source07" 6 "AudioSource_Source06" 5 "AudioSource_Source05" 4 "AudioSource_Source04" 3 "AudioSource_Source03" 2 "AudioSource_Source02" 1 "AudioSource_Source01" 0 "AudioSource_Source00" ;
VAL_ 2489730210 CMSOnOffRqst 3 "CMSOnOffRqst_NotAvailable" 2 "CMSOnOffRqst_Error" 1 "CMSOnOffRqst_BothButtonsPressed" 0 "CMSOnOffRqst_BothButtonsNotPressed" ;
VAL_ 2566043647 AlmClkSetAlm_LECM_rq_Type 7 "AlarmClkType_NotAvailable" 6 "AlarmClkType_Error" 5 "AlarmClkType_Reserved_02" 4 "AlarmClkType_Reserved_01" 3 "AlarmClkType_Light" 2 "AlarmClkType_Radio" 1 "AlarmClkType_Buzzer" 0 "AlarmClkType_NoAudibleNotification" ;
VAL_ 2566043647 AlmClkSnze_LECM_rqst_ID 127 "AlarmClkID_NotAvailable" 126 "AlarmClkID_Error" 10 "AlarmClkID_Alarm10" 9 "AlarmClkID_Alarm9" 8 "AlarmClkID_Alarm8" 7 "AlarmClkID_Alarm7" 6 "AlarmClkID_Alarm6" 5 "AlarmClkID_Alarm5" 4 "AlarmClkID_Alarm4" 3 "AlarmClkID_Alarm3" 2 "AlarmClkID_Alarm2" 1 "AlarmClkID_Alarm1" 0 "AlarmClkID_NotUsed" ;
VAL_ 2566043647 AlmClkSetAlm_LECM_rq_Mode 3 "AlarmClkMode_Spare" 2 "AlarmClkMode_Timer" 1 "AlarmClkMode_Recurrent" 0 "AlarmClkMode_OneTime" ;
VAL_ 2566043647 AlmClkSetAlm_LECM_rq_Stat 3 "AlarmClkStat2_Snoozed" 2 "AlarmClkStat2_Ringing" 1 "AlarmClkStat2_Active" 0 "AlarmClkStat2_Inactive" ;
VAL_ 2566043647 AlmClkSetAlm_LECM_rq_ID 127 "AlarmClkID_NotAvailable" 126 "AlarmClkID_Error" 10 "AlarmClkID_Alarm10" 9 "AlarmClkID_Alarm9" 8 "AlarmClkID_Alarm8" 7 "AlarmClkID_Alarm7" 6 "AlarmClkID_Alarm6" 5 "AlarmClkID_Alarm5" 4 "AlarmClkID_Alarm4" 3 "AlarmClkID_Alarm3" 2 "AlarmClkID_Alarm2" 1 "AlarmClkID_Alarm1" 0 "AlarmClkID_NotUsed" ;
VAL_ 2566043647 AlmClkSnze_LECM_rqst_Action 7 "AlmClkSnzeAction_NotAvailable" 6 "AlmClkSnzeAction_Error" 5 "AlmClkSnzeAction_Spare02" 4 "AlmClkSnzeAction_Spare01" 3 "AlmClkSnzeAction_RequestToContinuePlay" 2 "AlmClkSnzeAction_RequestToTurnAlarmOff" 1 "AlmClkSnzeAction_RequestToSnoozeAlarm" 0 "AlmClkSnzeAction_NoRequest" ;
VAL_ 2432693154 BunkH1Prev_ButtonStatus 3 "PushButtonStatus_NotAvailable" 2 "PushButtonStatus_Error" 1 "PushButtonStatus_Pushed" 0 "PushButtonStatus_Neutral" ;
VAL_ 2432693154 BunkH1RoofhatchOpenBtn_Stat 3 "PushButtonStatus_NotAvailable" 2 "PushButtonStatus_Error" 1 "PushButtonStatus_Pushed" 0 "PushButtonStatus_Neutral" ;
VAL_ 2432693154 BunkH1IntLghtActvnBtn_stat 3 "PushButtonStatus_NotAvailable" 2 "PushButtonStatus_Error" 1 "PushButtonStatus_Pushed" 0 "PushButtonStatus_Neutral" ;
VAL_ 2432693154 BunkH1AudioSource_rqst 7 "BunkH1AudioSource_rqst_NotAvailable" 6 "BunkH1AudioSource_rqst_Error" 5 "BunkH1AudioSource_rqst_AUX1" 4 "BunkH1AudioSource_rqst_iPod" 3 "BunkH1AudioSource_rqst_AUX2" 2 "BunkH1AudioSource_rqst_USB" 1 "BunkH1AudioSource_rqst_CD" 0 "BunkH1AudioSource_rqst_Radio" ;
VAL_ 2432693154 BunkH1TempDec_ButtonStatus 3 "PushButtonStatus_NotAvailable" 2 "PushButtonStatus_Error" 1 "PushButtonStatus_Pushed" 0 "PushButtonStatus_Neutral" ;
VAL_ 2432693154 BunkH1IntLghtDirAccsUpBtn_stat 3 "PushButtonStatus_NotAvailable" 2 "PushButtonStatus_Error" 1 "PushButtonStatus_Pushed" 0 "PushButtonStatus_Neutral" ;
VAL_ 2432693154 BunkH1RoofhatchCloseBtn_Stat 3 "PushButtonStatus_NotAvailable" 2 "PushButtonStatus_Error" 1 "PushButtonStatus_Pushed" 0 "PushButtonStatus_Neutral" ;
VAL_ 2432693154 BunkH1VolumeDown_ButtonStatus 3 "PushButtonStatus_NotAvailable" 2 "PushButtonStatus_Error" 1 "PushButtonStatus_Pushed" 0 "PushButtonStatus_Neutral" ;
VAL_ 2432693154 BunkH1PowerWinCloseDSBtn_stat 3 "PushButtonStatus_NotAvailable" 2 "PushButtonStatus_Error" 1 "PushButtonStatus_Pushed" 0 "PushButtonStatus_Neutral" ;
VAL_ 2432693154 BunkH1Next_ButtonStatus 3 "PushButtonStatus_NotAvailable" 2 "PushButtonStatus_Error" 1 "PushButtonStatus_Pushed" 0 "PushButtonStatus_Neutral" ;
VAL_ 2432693154 BunkH1UnlockButtonStatus 3 "PushButtonStatus_NotAvailable" 2 "PushButtonStatus_Error" 1 "PushButtonStatus_Pushed" 0 "PushButtonStatus_Neutral" ;
VAL_ 2432693154 BunkH1ParkHeaterTimer2_cmd 7 "ParkHeaterTimer_cmd_NotAvailable" 6 "ParkHeaterTimer_cmd_Error" 5 "ParkHeaterTimer_cmd_Spare_02" 4 "ParkHeaterTimer_cmd_Spare_01" 3 "ParkHeaterTimer_cmd_Spare" 2 "ParkHeaterTimer_cmd_TimerDisable" 1 "ParkHeaterTimer_cmd_TimerEnable" 0 "ParkHeaterTimer_cmd_NoAction" ;
VAL_ 2432693154 BunkH1AudioOnOff_ButtonStatus 3 "PushButtonStatus_NotAvailable" 2 "PushButtonStatus_Error" 1 "PushButtonStatus_Pushed" 0 "PushButtonStatus_Neutral" ;
VAL_ 2432693154 BunkH1PowerWinOpenDSBtn_stat 3 "PushButtonStatus_NotAvailable" 2 "PushButtonStatus_Error" 1 "PushButtonStatus_Pushed" 0 "PushButtonStatus_Neutral" ;
VAL_ 2432693154 BunkH1ParkHeater_ButtonStatus 3 "PushButtonStatus_NotAvailable" 2 "PushButtonStatus_Error" 1 "PushButtonStatus_Pushed" 0 "PushButtonStatus_Neutral" ;
VAL_ 2432693154 BunkH1VolumeUp_ButtonStatus 3 "PushButtonStatus_NotAvailable" 2 "PushButtonStatus_Error" 1 "PushButtonStatus_Pushed" 0 "PushButtonStatus_Neutral" ;
VAL_ 2432693154 BunkH1ParkHeaterTimer3_cmd 7 "ParkHeaterTimer_cmd_NotAvailable" 6 "ParkHeaterTimer_cmd_Error" 5 "ParkHeaterTimer_cmd_Spare_02" 4 "ParkHeaterTimer_cmd_Spare_01" 3 "ParkHeaterTimer_cmd_Spare" 2 "ParkHeaterTimer_cmd_TimerDisable" 1 "ParkHeaterTimer_cmd_TimerEnable" 0 "ParkHeaterTimer_cmd_NoAction" ;
VAL_ 2432693154 BunkH1Mute_ButtonStatus 3 "PushButtonStatus_NotAvailable" 2 "PushButtonStatus_Error" 1 "PushButtonStatus_Pushed" 0 "PushButtonStatus_Neutral" ;
VAL_ 2432693154 BunkH1IntLghtDirAccsDnBtn_stat 3 "PushButtonStatus_NotAvailable" 2 "PushButtonStatus_Error" 1 "PushButtonStatus_Pushed" 0 "PushButtonStatus_Neutral" ;
VAL_ 2432693154 BunkH1LockButtonStatus 3 "PushButtonStatus_NotAvailable" 2 "PushButtonStatus_Error" 1 "PushButtonStatus_Pushed" 0 "PushButtonStatus_Neutral" ;
VAL_ 2432693154 BunkH1ParkHeaterTimer1_cmd 7 "ParkHeaterTimer_cmd_NotAvailable" 6 "ParkHeaterTimer_cmd_Error" 5 "ParkHeaterTimer_cmd_Spare_02" 4 "ParkHeaterTimer_cmd_Spare_01" 3 "ParkHeaterTimer_cmd_Spare" 2 "ParkHeaterTimer_cmd_TimerDisable" 1 "ParkHeaterTimer_cmd_TimerEnable" 0 "ParkHeaterTimer_cmd_NoAction" ;
VAL_ 2432693154 BnkH1IntLghtMMenu_stat_IL_Mode 7 "IL_Mode_NotAvailable" 6 "IL_Mode_ErrorIndicator" 5 "IL_Mode_spare_2" 4 "IL_Mode_spare_1" 3 "IL_Mode_Max" 2 "IL_Mode_Resting" 1 "IL_Mode_NightDriving" 0 "IL_Mode_OFF" ;
VAL_ 2432693154 BunkH1AudioSource_rqst2 15 "AudioSource_rqst4bit_NotAvailable" 14 "AudioSource_rqst4bit_Error" 13 "AudioSource_rqst4bit_Spare7" 12 "AudioSource_rqst4bit_Spare6" 11 "AudioSource_rqst4bit_Spare5" 10 "AudioSource_rqst4bit_Spare4" 9 "AudioSource_rqst4bit_Spare3" 8 "AudioSource_rqst4bit_Spare2" 7 "AudioSource_rqst4bit_Spare1" 6 "AudioSource_rqst4bit_BtStream" 5 "AudioSource_rqst4bit_AUX1" 4 "AudioSource_rqst4bit_IPOD" 3 "AudioSource_rqst4bit_AUX2" 2 "AudioSource_rqst4bit_USB" 1 "AudioSource_rqst4bit_CD" 0 "AudioSource_rqst4bit_Radio" ;
VAL_ 2432693154 BnkH1IntLghtMMenu_stat_EventFlag 1 "EventFlag_High" 0 "EventFlag_Low" ;
VAL_ 2432693154 BunkH1PowerWinOpenPSBtn_stat 3 "PushButtonStatus_NotAvailable" 2 "PushButtonStatus_Error" 1 "PushButtonStatus_Pushed" 0 "PushButtonStatus_Neutral" ;
VAL_ 2432693154 BunkH1PowerWinClosePSBtn_stat 3 "PushButtonStatus_NotAvailable" 2 "PushButtonStatus_Error" 1 "PushButtonStatus_Pushed" 0 "PushButtonStatus_Neutral" ;
VAL_ 2432693154 BunkH1TempInc_ButtonStatus 3 "PushButtonStatus_NotAvailable" 2 "PushButtonStatus_Error" 1 "PushButtonStatus_Pushed" 0 "PushButtonStatus_Neutral" ;
VAL_ 2499790739 CMSFailureStat_Status 7 "CMSFailureStatus_NotAvailable" 6 "CMSFailureStatus_Error" 5 "CMSFailureStatus_Spare3" 4 "CMSFailureStatus_Spare2" 3 "CMSFailureStatus_Spare1" 2 "CMSFailureStatus_Red" 1 "CMSFailureStatus_Amber" 0 "CMSFailureStatus_OK" ;
VAL_ 2499790995 CMSActvtnDeactvtnStat_Status 7 "CMSinactive_NotAvailable" 6 "CMSinactive_Error" 5 "CMSinactive_Spare3" 4 "CMSinactive_Spare2" 3 "CMSinactive_Spare1" 2 "CMSinactive_Spare0" 1 "CMSinactive_Active" 0 "CMSinactive_Inactive" ;
VAL_ 2499790995 CMSZoomStat_Status 3 "OffOn_NotAvailable" 2 "OffOn_Error" 1 "OffOn_On" 0 "OffOn_Off" ;
VAL_ 2499790995 CMSFoldingStat_Status 7 "CMSFolding_stat_NotAvailable" 6 "CMSFolding_stat_Error" 5 "CMSFolding_stat_Spare3" 4 "CMSFolding_stat_Spare2" 3 "CMSFolding_stat_Spare1" 2 "CMSFolding_stat_WingsUnfolded" 1 "CMSFolding_stat_Idle" 0 "CMSFolding_stat_WingsFolded" ;
VAL_ 2499790995 CMSManualAlignmStat_Status 7 "CMSManualAlignment_stat_NotAvailable" 6 "CMSManualAlignment_stat_Error" 5 "CMSManualAlignment_stat_Spare4" 4 "CMSManualAlignment_stat_Spare3" 3 "CMSManualAlignment_stat_ActiveOnPassengerSide" 2 "CMSManualAlignment_stat_ActiveOnDriverSide" 1 "CMSManualAlignment_stat_ActiveOnBothSides" 0 "CMSManualAlignment_stat_Off" ;
SIG_GROUP_ 2516576083 TrafficAccidentStat_sg 1 : TrafficAccidentStat_Status TrafficAccidentStat_CRC TrafficAccidentStat_SqC;
SIG_GROUP_ 2432689747 SideColliAccidentStat_sg 1 : SideColliAccidentStat_RightSide SideColliAccidentStat_LeftSide SideColliAccidentStat_CRC SideColliAccidentStat_SqC;
SIG_GROUP_ 2499788607 TrafficAccShutDownReq_sg 1 : TrafficAccShutDownReq_CRC TrafficAccShutDownReq_Rqst TrafficAccShutDownReq_SqC;
SIG_GROUP_ 2566337698 LECM_AlClkSnze_GRqst_sg 1 : LECM_AlClkSnze_GRqst_ID LECM_AlClkSnze_GRqst_Action;
SIG_GROUP_ 2566337698 LECM_AlClkSetAl_GRqst_sg 1 : LECM_AlClkSetAl_GRqst_Mode LECM_AlClkSetAl_GRqst_Stat LECM_AlClkSetAl_GRqst_SetHr LECM_AlClkSetAl_GRqst_ID LECM_AlClkSetAl_GRqst_DaySet LECM_AlClkSetAl_GRqst_Type LECM_AlClkSetAl_GRqst_SetMin;
SIG_GROUP_ 2499772322 MediaSourcesListReq_sg 1 : MediaSourcesListReq_SInfo MediaSourcesListReq_Items MediaSourcesListReq_ItemID;
SIG_GROUP_ 2566043647 AlmClkSetAlm_LECM_rq_sg 1 : AlmClkSetAlm_LECM_rq_Type AlmClkSetAlm_LECM_rq_SetHr AlmClkSetAlm_LECM_rq_DaySet AlmClkSetAlm_LECM_rq_Mode AlmClkSetAlm_LECM_rq_Stat AlmClkSetAlm_LECM_rq_SetMin AlmClkSetAlm_LECM_rq_ID;
SIG_GROUP_ 2566043647 AlmClkSnze_LECM_rqst_sg 1 : AlmClkSnze_LECM_rqst_ID AlmClkSnze_LECM_rqst_Action;
SIG_GROUP_ 2432693154 BnkH1IntLghtMMenu_stat_sg 1 : BnkH1IntLghtMMenu_stat_IL_Mode BnkH1IntLghtMMenu_stat_EventFlag;
SIG_GROUP_ 2567057439 DiagFaultStat_WRCS_sg 1 : DiagFaultStat_WRCS_FailTA DiagFaultStat_WRCS_DtcIdB DiagFaultStat_WRCS_FailTB DiagFaultStat_WRCS_EcuAdr DiagFaultStat_WRCS_DtcIdA;
SIG_GROUP_ 2567057438 DiagFaultStat_SRS_sg 1 : DiagFaultStat_SRS_DtcIdA DiagFaultStat_SRS_FailTA DiagFaultStat_SRS_FailTB DiagFaultStat_SRS_DtcIdB DiagFaultStat_SRS_EcuAdr;
SIG_GROUP_ 2567057437 DiagFaultStat_LECM_sg 1 : DiagFaultStat_LECM_DtcIdA DiagFaultStat_LECM_FailTA DiagFaultStat_LECM_FailTB DiagFaultStat_LECM_DtcIdB DiagFaultStat_LECM_EcuAdr;
SIG_GROUP_ 2567049378 DiagFaultStat_LECM3_sg 1 : DiagFaultStat_LECM3_DtcIdB DiagFaultStat_LECM3_EcuAdr DiagFaultStat_LECM3_DtcIdA DiagFaultStat_LECM3_FailTA DiagFaultStat_LECM3_FailTB;
SIG_GROUP_ 2567049363 DiagFaultStat_CMS_sg 1 : DiagFaultStat_CMS_EcuAdr DiagFaultStat_CMS_DtcIdB DiagFaultStat_CMS_FailTB DiagFaultStat_CMS_DtcIdA DiagFaultStat_CMS_FailTA;
SIG_GROUP_ 2567057436 DiagFaultStat_CCM_sg 1 : DiagFaultStat_CCM_FailTB DiagFaultStat_CCM_DtcIdB DiagFaultStat_CCM_EcuAdr DiagFaultStat_CCM_DtcIdA DiagFaultStat_CCM_FailTA;
SIG_GROUP_ 2499790739 CMSFailureStat_sg 1 : CMSFailureStat_SqC CMSFailureStat_Status CMSFailureStat_CRC;
SIG_GROUP_ 2499790995 CMSFoldingStat_sg 1 : CMSFoldingStat_CRC CMSFoldingStat_Status CMSFoldingStat_SqC;
SIG_GROUP_ 2499790995 CMSActvtnDeactvtnStat_sg 1 : CMSActvtnDeactvtnStat_Status CMSActvtnDeactvtnStat_SqC CMSActvtnDeactvtnStat_CRC;
SIG_GROUP_ 2499790995 CMSManualAlignmStat_sg 1 : CMSManualAlignmStat_CRC CMSManualAlignmStat_Status CMSManualAlignmStat_SqC;
SIG_GROUP_ 2499790995 CMSZoomStat_sg 1 : CMSZoomStat_Status CMSZoomStat_SqC CMSZoomStat_CRC;
